VERSION ""

NS_ :

BS_:

BU_: CEM20 GW IDM Tester

BO_ 579 HUT_FD3: 64 GW
 SG_ LgtFolwDistanceSet : 378|3@0+ (1,0) [0|7] "NoUnit"  IDM
 SG_ IntellgntAsscLmpEnaReq : 369|2@0+ (1,0) [0|3] "NoUnit"  IDM
 SG_ UsrExperiProgAuthorSts : 371|2@0+ (1,0) [0|3] "NoUnit"  IDM
 SG_ SidePrkgReq : 373|2@0+ (1,0) [0|3] "NoUnit"  IDM
 SG_ NOAFuncSet : 375|2@0+ (1,0) [0|3] "NoUnit"  IDM
 SG_ OvertakingLightModReq : 361|2@0+ (1,0) [0|3] "NoUnit"  IDM
 SG_ IDsceneModReq : 365|4@0+ (1,0) [0|15] "NoUnit"  IDM
 SG_ PassETCEnaReq : 367|2@0+ (1,0) [0|3] "NoUnit"  IDM
 SG_ DeviateSpdPreReq : 357|6@0+ (1,-1) [-1|39] "Perc"  IDM
 SG_ StartReminderEnaReq : 359|2@0+ (1,0) [0|3] "NoUnit"  IDM
 SG_ DeviateSpdFixdValReq : 349|6@0+ (1,-1) [-1|39] "NoUnit"  IDM
 SG_ HandsoffModReq : 351|2@0+ (1,0) [0|3] "NoUnit"  IDM
 SG_ HWA_FaststSwtReq : 337|2@0+ (1,0) [0|3] "NoUnit"  IDM
 SG_ DeviateSpdModSwtReq : 339|2@0+ (1,0) [0|3] "NoUnit"  IDM
 SG_ MapStatus : 343|4@0+ (1,0) [0|15] ""  IDM
 SG_ ADAS_gpsAuthSys : 329|1@0+ (1,0) [0|1] ""  IDM
 SG_ PrivacySts : 330|1@0+ (1,0) [0|1] ""  IDM
 SG_ UNP_SwtReq : 331|1@0+ (1,0) [0|1] "NoUnit"  IDM
 SG_ NOH_Act_Req : 334|1@0+ (1,0) [0|1] ""  IDM
 SG_ NOH_Swt_Req : 335|1@0+ (1,0) [0|1] ""  IDM
 SG_ AVM_3DAngleReq : 239|9@0+ (1,0) [1|361] "NoUnit"  IDM
 SG_ PrkAreaSts : 225|2@0+ (1,0) [0|3] "NoUnit"  IDM
 SG_ BeginnerModSts : 191|2@0+ (1,0) [0|3] "NoUnit"  IDM
 SG_ OneClickAutDrvgSts : 125|1@0+ (1,0) [0|1] "NoUnit"  IDM
 SG_ HandsoffTimSet : 127|2@0+ (1,0) [0|3] "NoUnit"  IDM
 SG_ HUT_OD_WorkSts : 113|2@0+ (1,0) [0|3] "NoUnit"  IDM
 SG_ TraLightSwtReq : 62|1@0+ (1,0) [0|1] ""  IDM

BO_ 580 CSA3: 8 GW
 SG_ InrMalfct : 43|1@0+ (1,0) [0|1] ""  IDM

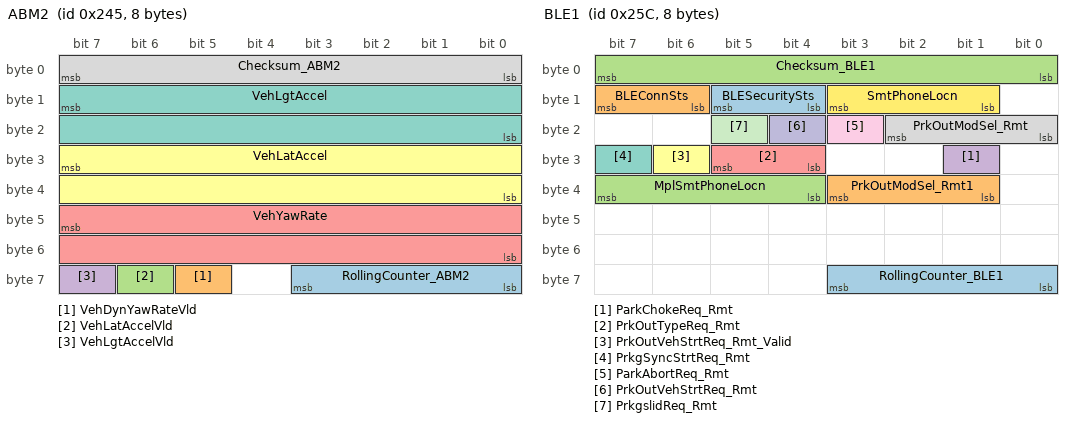
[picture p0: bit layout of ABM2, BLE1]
BO_ 581 ABM2: 8 GW
 SG_ RollingCounter_ABM2 : 59|4@0+ (1,0) [0|15] ""  IDM
 SG_ VehDynYawRateVld : 61|1@0+ (1,0) [0|1] ""  IDM
 SG_ VehLatAccelVld : 62|1@0+ (1,0) [0|1] ""  IDM
 SG_ VehLgtAccelVld : 63|1@0+ (1,0) [0|1] ""  IDM
 SG_ VehYawRate : 47|16@0+ (0.00024,-2.093) [-2.093|2.093] "rad/s"  IDM
 SG_ VehLatAccel : 31|16@0+ (0.00098,-21.592) [-21.592|21.592] "m/s^2"  IDM
 SG_ VehLgtAccel : 15|16@0+ (0.00098,-21.592) [-21.592|21.592] "m/s^2"  IDM
 SG_ Checksum_ABM2 : 7|8@0+ (1,0) [0|255] ""  IDM

BO_ 589 DMS_FD1: 64 GW
 SG_ DrvBehvSts : 370|3@0+ (1,0) [0|7] ""  IDM
 SG_ DMSSts : 303|3@0+ (1,0) [0|7] ""  IDM
 SG_ HeadDetn : 288|1@0+ (1,0) [0|1] ""  IDM
 SG_ DrowsnsLvl_ACC : 92|3@0+ (1,0) [0|7] ""  IDM
 SG_ DistrctnLvl_ACC : 95|3@0+ (1,0) [0|7] ""  IDM
 SG_ ExprsnSts : 34|3@0+ (1,0) [0|7] "NoUnit"  IDM
 SG_ DrvGazSts : 2|3@0+ (1,0) [0|7] ""  IDM

BO_ 596 CSA6: 8 GW
 SG_ LeSideDoRollSts : 19|4@0+ (1,0) [0|15] ""  IDM
 SG_ LeSideUpRollSts : 23|4@0+ (1,0) [0|15] ""  IDM

BO_ 604 BLE1: 8 GW
 SG_ RollingCounter_BLE1 : 59|4@0+ (1,0) [0|15] ""  IDM
 SG_ PrkOutModSel_Rmt1 : 35|3@0+ (1,0) [0|7] "NoUnit"  IDM
 SG_ MplSmtPhoneLocn : 39|4@0+ (1,0) [0|15] "NoUnit"  IDM
 SG_ ParkChokeReq_Rmt : 25|1@0+ (1,0) [0|1] "NoUnit"  IDM
 SG_ PrkOutTypeReq_Rmt : 29|2@0+ (1,0) [0|3] ""  IDM
 SG_ PrkOutVehStrtReq_Rmt_Valid : 30|1@0+ (1,0) [0|1] ""  IDM
 SG_ PrkgSyncStrtReq_Rmt : 31|1@0+ (1,0) [0|1] ""  IDM
 SG_ PrkOutModSel_Rmt : 18|3@0+ (1,0) [0|7] ""  IDM
 SG_ ParkAbortReq_Rmt : 19|1@0+ (1,0) [0|1] ""  IDM
 SG_ PrkOutVehStrtReq_Rmt : 20|1@0+ (1,0) [0|1] ""  IDM
 SG_ PrkgslidReq_Rmt : 21|1@0+ (1,0) [0|1] ""  IDM
 SG_ SmtPhoneLocn : 11|3@0+ (1,0) [0|7] "NoUnit"  IDM
 SG_ BLESecuritySts : 13|2@0+ (1,0) [0|3] ""  IDM
 SG_ BLEConnSts : 15|2@0+ (1,0) [0|3] ""  IDM
 SG_ Checksum_BLE1 : 7|8@0+ (1,0) [0|255] ""  IDM

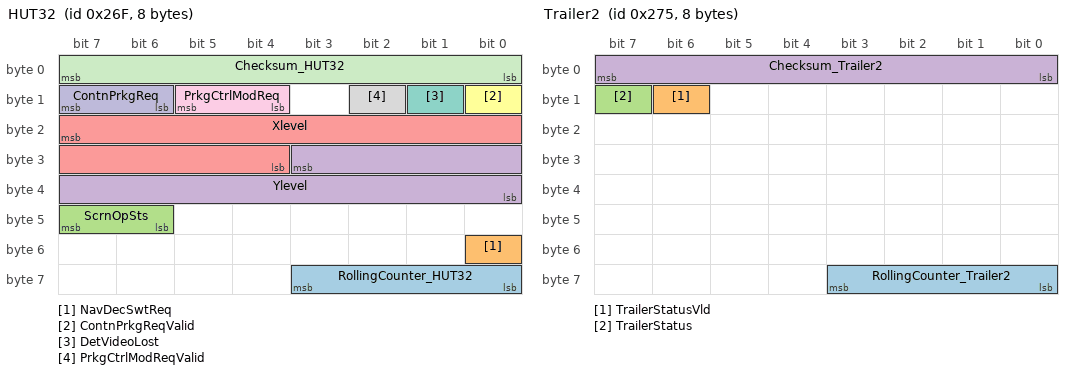
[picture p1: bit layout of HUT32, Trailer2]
BO_ 623 HUT32: 8 GW
 SG_ RollingCounter_HUT32 : 59|4@0+ (1,0) [0|14] ""  IDM
 SG_ NavDecSwtReq : 48|1@0+ (1,0) [0|1] "_"  IDM
 SG_ ScrnOpSts : 47|2@0+ (1,0) [0|3] ""  IDM
 SG_ Ylevel : 27|12@0+ (1,0) [0|4094] "NoUnit"  IDM
 SG_ Xlevel : 23|12@0+ (1,0) [0|4094] "NoUnit"  IDM
 SG_ ContnPrkgReqValid : 8|1@0+ (1,0) [0|1] ""  IDM
 SG_ DetVideoLost : 9|1@0+ (1,0) [0|1] ""  IDM
 SG_ PrkgCtrlModReqValid : 10|1@0+ (1,0) [0|1] ""  IDM
 SG_ PrkgCtrlModReq : 13|2@0+ (1,0) [0|3] ""  IDM
 SG_ ContnPrkgReq : 15|2@0+ (1,0) [0|3] ""  IDM
 SG_ Checksum_HUT32 : 7|8@0+ (1,0) [0|255] ""  IDM

BO_ 627 Trailer1: 8 GW
 SG_ TrailerSts : 7|1@0+ (1,0) [0|1] ""  IDM

BO_ 629 Trailer2: 8 GW
 SG_ RollingCounter_Trailer2 : 59|4@0+ (1,0) [0|14] "NoUnit"  IDM
 SG_ TrailerStatusVld : 14|1@0+ (1,0) [0|1] "NoUnit"  IDM
 SG_ TrailerStatus : 15|1@0+ (1,0) [0|1] "NoUnit"  IDM
 SG_ Checksum_Trailer2 : 7|8@0+ (1,0) [0|255] "NoUnit"  IDM

BO_ 639 IP2: 16 GW
 SG_ IP_Err : 52|1@0+ (1,0) [0|1] ""  IDM
 SG_ IP_VehSpdUnit : 53|1@0+ (1,0) [0|1] ""  IDM
 SG_ IP_VehTotDistanceValid : 46|1@0+ (1,0) [0|1] ""  IDM
 SG_ IP_ACCErr : 47|1@0+ (1,0) [0|1] ""  IDM
 SG_ IP_VehTotDistance : 15|24@0+ (0.1,0) [0|999999.9] "Km"  IDM

BO_ 659 IP1: 8 GW
 SG_ IP_VelSpdDisp_Mile : 51|8@0+ (1,0) [0|254] "mph"  IDM
 SG_ IP_VehSpdDisp : 15|9@0+ (0.5,0) [0|255] "km/h"  IDM

BO_ 670 BMS_FD2: 64 GW
 SG_ BMS_CC2LineSts : 211|2@0+ (1,0) [0|3] "NoUnit"  IDM

BO_ 707 HUT_FD1: 64 GW
 SG_ MAC_Check_HUT_FD1 : 471|48@0+ (1,0) [0|281474976710655] ""  IDM
 SG_ FreshnessValue_HUT_FD1 : 455|16@0+ (1,0) [0|65535] ""  IDM
 SG_ ADAS_Posn_Rehead : 383|8@0+ (1.41732283464567,0) [2.83464566929134|357.165354330709] "NoUnit"  IDM
 SG_ ADAS_Posn_Spd : 360|9@0+ (0.2,-12.8) [-12.6|89] "mps"  IDM
 SG_ ADAS_Posn_CurLane : 363|3@0+ (1,0) [0|7] ""  IDM
 SG_ ADAS_Posn_PosConfdc : 366|3@0+ (1,0) [0|6] "NoUnit"  IDM
 SG_ ADAS_Posn_Age : 344|9@0+ (5,0) [0|2545] "ms"  IDM
 SG_ ADAS_Posn_PosProbb : 349|5@0+ (3.33,0) [3.33|99.9] "NoUnit"  IDM
 SG_ ADAS_Posn_Idx : 351|2@0+ (1,0) [0|3] "m"  IDM
 SG_ ADAS_Posn_Pathldx : 341|6@0+ (1,0) [0|63] ""  IDM
 SG_ ADAS_Posn_CycCnt : 343|2@0+ (1,0) [0|3] ""  IDM
 SG_ ADAS_Posn_Offset : 324|13@0+ (1,0) [0|8190] "m"  IDM
 SG_ ADAS_Posn_MsgTye : 327|3@0+ (1,0) [0|7] ""  IDM
 SG_ NavSpdLimType : 307|2@0+ (1,0) [0|3] ""  IDM
 SG_ NavigationRoadType : 311|4@0+ (1,0) [0|15] ""  IDM
 SG_ ALC_SwtReq : 296|1@0+ (1,0) [0|1] ""  IDM
 SG_ AESSwtReq : 298|1@0+ (1,0) [0|1] ""  IDM
 SG_ AEB_JASwtReq : 299|1@0+ (1,0) [0|1] ""  IDM
 SG_ FCTABrkSwtReq : 300|1@0+ (1,0) [0|1] ""  IDM
 SG_ FCTASwtReq : 301|1@0+ (1,0) [0|1] ""  IDM
 SG_ HWA_SnvtySet : 303|2@0+ (1,0) [0|3] ""  IDM
 SG_ NavTSRTrafSign : 295|8@0+ (1,0) [0|255] ""  IDM
 SG_ HWA_SwtReq : 280|1@0+ (1,0) [0|1] ""  IDM
 SG_ NavSpdLimSignSts : 285|3@0+ (1,0) [0|7] ""  IDM
 SG_ NavCtryType : 279|10@0+ (1,0) [0|1023] ""  IDM
 SG_ NavSpdLimUnit_HUT : 265|2@0+ (1,0) [0|3] ""  IDM
 SG_ NavSpdLimValue : 271|6@0+ (1,0) [0|63] ""  IDM
 SG_ NavVehToTrafEyeDist : 239|10@0+ (1,0) [0|1023] ""  IDM
 SG_ MOD_SwtReq : 207|2@0+ (1,0) [0|3] "NoUnit"  IDM
 SG_ TSR_SnvtySet : 125|5@0+ (1,-15) [-15|15] "km/h"  IDM
 SG_ ISLSwtReq : 126|1@0+ (1,0) [0|1] ""  IDM
 SG_ DOWSwtReq : 104|1@0+ (1,0) [0|1] ""  IDM
 SG_ AEB_PedSwtReq : 105|1@0+ (1,0) [0|1] ""  IDM
 SG_ LSSSwtReq : 106|1@0+ (1,0) [0|1] ""  IDM
 SG_ IntelligentEvaSwtReq : 107|1@0+ (1,0) [0|1] ""  IDM
 SG_ LSSWarnFormSwtReq : 100|2@0+ (1,0) [0|3] ""  IDM
 SG_ TSRWarnSwtReq : 101|1@0+ (1,0) [0|1] ""  IDM
 SG_ TSRSwtReq : 102|1@0+ (1,0) [0|1] ""  IDM
 SG_ LDWSwtReq : 88|1@0+ (1,0) [0|1] ""  IDM
 SG_ ESS_VehSwtReq : 89|1@0+ (1,0) [0|1] ""  IDM
 SG_ ESS_PedSwtReq : 90|1@0+ (1,0) [0|1] ""  IDM
 SG_ ELKSwtReq : 91|1@0+ (1,0) [0|1] ""  IDM
 SG_ LCKSwtReq : 92|1@0+ (1,0) [0|1] ""  IDM
 SG_ LKASwtReq : 93|1@0+ (1,0) [0|1] ""  IDM
 SG_ AEB_VehSwtReq : 95|1@0+ (1,0) [0|1] ""  IDM
 SG_ FCW_SnvtySet : 81|2@0+ (1,0) [0|3] ""  IDM
 SG_ RCWSwtReq : 82|1@0+ (1,0) [0|1] ""  IDM
 SG_ RCTABrkSwtReq : 83|1@0+ (1,0) [0|1] ""  IDM
 SG_ RCTASwtReq : 84|1@0+ (1,0) [0|1] ""  IDM
 SG_ LCASwtReq : 85|1@0+ (1,0) [0|1] ""  IDM
 SG_ IFC_SnvtySet : 77|2@0+ (1,0) [0|3] ""  IDM
 SG_ NOH_Btn_Sts : 65|1@0+ (1,0) [0|1] ""  IDM
 SG_ DR_CalibratedSts : 69|1@0+ (1,0) [0|1] ""  IDM
 SG_ IntellgntcurveReq : 9|1@0+ (1,0) [0|1] ""  IDM

BO_ 717 PDCM1: 8 GW
 SG_ PassWinPosnSts_Perc : 39|5@0+ (1,0) [0|31] ""  IDM
 SG_ RSDS_Pass_LED_Sts : 8|1@0+ (1,0) [0|1] ""  IDM

BO_ 725 PRDCM1: 8 GW
 SG_ PassRearDoorWinPosnSts_Perc : 15|5@0+ (1,0) [0|31] "NoUnit"  IDM

BO_ 726 VCU_FD4: 64 GW
 SG_ WtrAirCoolrPmp_FltSts : 272|1@0+ (1,0) [0|1] "NoUnit"  IDM
 SG_ RollingCounter_VCU13 : 251|4@0+ (1,0) [0|15] "NoUnit"  IDM
 SG_ VCU_LTRadrOutlWtrTemp : 223|8@0+ (1,-40) [-40|130] "DegCgrd"  IDM
 SG_ VCU_WtrPmpOpenRateCtrl : 215|7@0+ (1,0) [0|100] "Perc"  IDM
 SG_ Checksum_VCU13 : 199|8@0+ (1,0) [0|255] "NoUnit"  IDM
 SG_ VCU_VCUSts : 181|5@0+ (1,0) [0|31] "NoUnit"  IDM
 SG_ VCU_ResrDrvRng : 175|10@0+ (1,0) [0|999] "Km"  IDM
 SG_ RollingCounter_VCU3 : 123|4@0+ (1,0) [0|15] "NoUnit"  IDM
 SG_ ChrgnSts : 127|4@0+ (1,0) [0|15] ""  IDM
 SG_ VCU_SysFltLmp : 114|2@0+ (1,0) [0|3] ""  IDM
 SG_ EnrgFlowInd : 111|6@0+ (1,0) [0|63] ""  IDM
 SG_ VCU_TMWtrPmpSts : 98|1@0+ (1,0) [0|1] "NoUnit"  IDM
 SG_ VCU_PwrLo : 99|1@0+ (1,0) [0|1] ""  IDM
 SG_ VCU_EPSEnable : 101|1@0+ (1,0) [0|1] ""  IDM
 SG_ VCU_RdyLEDSts : 103|2@0+ (1,0) [0|3] "No Unit"  IDM
 SG_ VCU_VehBrkLiActv : 80|1@0+ (1,0) [0|1] ""  IDM
 SG_ VCU_OPDSts : 87|3@0+ (1,0) [0|7] ""  IDM
 SG_ VCU_HeatgAimT : 79|8@0+ (1,0) [0|165] ""  IDM
 SG_ Checksum_VCU3 : 71|8@0+ (1,0) [0|255] "NoUnit"  IDM

BO_ 728 HUT23: 8 GW
 SG_ ADAS_Stub_NumOfLaneDrvDir : 58|3@0+ (1,0) [0|7] ""  IDM
 SG_ ADAS_Stub_NumOfLaneOppDir : 60|2@0+ (1,0) [0|3] ""  IDM
 SG_ ADAS_Stub_RtOfWay : 62|2@0+ (1,0) [0|3] ""  IDM
 SG_ ADAS_Stub_LastStub : 63|1@0+ (1,0) [0|1] ""  IDM
 SG_ ADAS_Stub_TurnAngl : 55|8@0+ (1.417,0) [2.834|357.084] "NoUnit"  IDM
 SG_ ADAS_Stub_FormOfWay : 43|4@0+ (1,0) [0|15] ""  IDM
 SG_ ADAS_Stub_CmplxInsct : 45|2@0+ (1,0) [0|3] ""  IDM
 SG_ ADAS_Stub_PartOfCalcRoute : 47|2@0+ (1,0) [0|3] ""  IDM
 SG_ ADAS_Stub_FuncRoadClass : 34|3@0+ (1,0) [0|7] ""  IDM
 SG_ ADAS_Stub_RelProbb : 39|5@0+ (3.33333,0) [3.33333|99.9999] "NoUnit"  IDM
 SG_ ADAS_Stub_Update : 24|1@0+ (1,0) [0|1] ""  IDM
 SG_ ADAS_Stub_Retr : 25|1@0+ (1,0) [0|1] ""  IDM
 SG_ ADAS_Stub_StubPathIdx : 31|6@0+ (1,0) [0|63] ""  IDM
 SG_ ADAS_Stub_PathIdx : 21|6@0+ (1,0) [0|63] ""  IDM
 SG_ ADAS_Stub_CycCnt : 23|2@0+ (1,0) [0|3] "NoUnit"  IDM
 SG_ ADAS_Stub_Offset : 4|13@0+ (1,0) [0|8190] "m"  IDM
 SG_ ADAS_Stub_MsgTyp : 7|3@0+ (1,0) [0|7] ""  IDM

BO_ 730 HUT22: 8 GW
 SG_ ADAS_Seg_NumOfLaneDrvDir : 58|3@0+ (1,0) [0|7] "NoUnit"  IDM
 SG_ ADAS_Seg_NumOfLaneOppDir : 60|2@0+ (1,0) [0|3] ""  IDM
 SG_ ADAS_Seg_DivideRoad : 62|2@0+ (1,0) [0|3] ""  IDM
 SG_ ADAS_Seg_EffSpdLmtTyp : 50|3@0+ (1,0) [0|7] ""  IDM
 SG_ ADAS_Seg_EffSpdLmt : 55|5@0+ (1,0) [0|31] "NoUnit"  IDM
 SG_ ADAS_Seg_FormOfWay : 43|4@0+ (1,0) [0|15] ""  IDM
 SG_ ADAS_Seg_CmplxInsct : 45|2@0+ (1,0) [0|3] ""  IDM
 SG_ ADAS_Seg_PartOfCalcRoute : 47|2@0+ (1,0) [0|3] ""  IDM
 SG_ ADAS_Seg_FuncRoadClass : 34|3@0+ (1,0) [0|7] ""  IDM
 SG_ ADAS_Seg_RelProbb : 39|5@0+ (3.33333333333333,0) [3.33333333333333|99.9999999999999] "NoUnit"  IDM
 SG_ ADAS_Seg_Update : 24|1@0+ (1,0) [0|1] ""  IDM
 SG_ ADAS_Seg_Retr : 25|1@0+ (1,0) [0|1] ""  IDM
 SG_ ADAS_Seg_BuildUpArea : 27|2@0+ (1,0) [0|3] ""  IDM
 SG_ ADAS_Seg_Brdg : 29|2@0+ (1,0) [0|3] ""  IDM
 SG_ ADAS_Seg_Tunnel : 31|2@0+ (1,0) [0|3] ""  IDM
 SG_ ADAS_Seg_PathIdx : 21|6@0+ (1,0) [0|63] "NoUnit"  IDM
 SG_ ADAS_Seg_CycCnt : 23|2@0+ (1,0) [0|3] "NoUnit"  IDM
 SG_ ADAS_Seg_Offset : 4|13@0+ (1,0) [0|8190] "m"  IDM
 SG_ ADAS_Seg_MsgTyp : 7|3@0+ (1,0) [0|7] ""  IDM

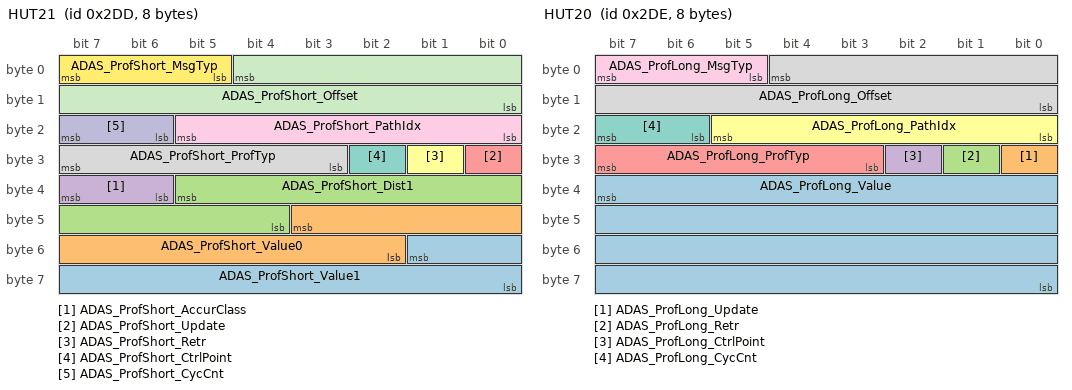
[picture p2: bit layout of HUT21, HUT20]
BO_ 733 HUT21: 8 GW
 SG_ ADAS_ProfShort_Value1 : 49|10@0+ (1,0) [0|1022] ""  IDM
 SG_ ADAS_ProfShort_Value0 : 43|10@0+ (1,0) [0|1022] ""  IDM
 SG_ ADAS_ProfShort_Dist1 : 37|10@0+ (1,0) [1|1022] "m"  IDM
 SG_ ADAS_ProfShort_AccurClass : 39|2@0+ (1,0) [0|3] ""  IDM
 SG_ ADAS_ProfShort_Update : 24|1@0+ (1,0) [0|1] ""  IDM
 SG_ ADAS_ProfShort_Retr : 25|1@0+ (1,0) [0|1] ""  IDM
 SG_ ADAS_ProfShort_CtrlPoint : 26|1@0+ (1,0) [0|1] ""  IDM
 SG_ ADAS_ProfShort_ProfTyp : 31|5@0+ (1,0) [0|31] ""  IDM
 SG_ ADAS_ProfShort_PathIdx : 21|6@0+ (1,0) [0|63] ""  IDM
 SG_ ADAS_ProfShort_CycCnt : 23|2@0+ (1,0) [0|3] ""  IDM
 SG_ ADAS_ProfShort_Offset : 4|13@0+ (1,0) [0|8190] "m"  IDM
 SG_ ADAS_ProfShort_MsgTyp : 7|3@0+ (1,0) [0|7] ""  IDM

BO_ 734 HUT20: 8 GW
 SG_ ADAS_ProfLong_Value : 39|32@0+ (1,0) [0|4294967295] ""  IDM
 SG_ ADAS_ProfLong_Update : 24|1@0+ (1,0) [0|1] ""  IDM
 SG_ ADAS_ProfLong_Retr : 25|1@0+ (1,0) [0|1] ""  IDM
 SG_ ADAS_ProfLong_CtrlPoint : 26|1@0+ (1,0) [0|1] ""  IDM
 SG_ ADAS_ProfLong_ProfTyp : 31|5@0+ (1,0) [0|31] ""  IDM
 SG_ ADAS_ProfLong_PathIdx : 21|6@0+ (1,0) [0|63] ""  IDM
 SG_ ADAS_ProfLong_CycCnt : 23|2@0+ (1,0) [0|3] ""  IDM
 SG_ ADAS_ProfLong_Offset : 4|13@0+ (1,0) [0|8190] "m"  IDM
 SG_ ADAS_ProfLong_MsgTyp : 7|3@0+ (1,0) [0|7] ""  IDM

BO_ 769 ECM_FD3: 64 GW
 SG_ ECM_WCACPmpFailrSts : 294|1@0+ (1,0) [0|1] "NoUnit"  IDM
 SG_ CoolerSts : 167|7@0+ (1,0) [0|100] "Perc"  IDM
 SG_ EngLimpHomeSts : 115|1@0+ (1,0) [0|1] "NoUnit"  IDM

BO_ 795 VCU5: 8 GW
 SG_ VCU_SysFltLvl : 62|3@0+ (1,0) [0|7] "No Unit"  IDM

BO_ 796 HUT13: 8 GW
 SG_ HUT_EPB_SwtPosn : 51|2@0+ (1,0) [0|3] "NoUnit"  IDM

BO_ 799 OBC_FD2: 8 GW
 SG_ OBC_CCLineSts : 48|2@0+ (1,0) [0|3] "NoUnit"  IDM

BO_ 822 HUT_FD10: 32 GW
 SG_ DrvImpairmAsstReq : 185|2@0+ (1,0) [0|3] "NoUnit"  IDM

BO_ 827 HUT17: 8 GW
 SG_ LowPowerEgyMngmntModReq : 57|2@0+ (1,0) [0|3] ""  IDM

BO_ 829 T_BOX_FD6: 16 GW
 SG_ T_BOX_AVPActvReq : 3|2@0+ (1,0) [0|3] ""  IDM

BO_ 840 HUT16: 8 GW
 SG_ IntellgntDrvChildModDetn : 59|2@0+ (1,0) [0|3] "NoUnit"  IDM
 SG_ SentinelMode_HUT : 35|2@0+ (1,0) [0|3] "Nounit"  IDM

BO_ 849 ABM1: 16 GW
 SG_ RollingCounter_ABM1 : 59|4@0+ (1,0) [0|15] ""  IDM
 SG_ CrashSev_1 : 60|1@0+ (1,0) [0|1] "NoUnit"  IDM
 SG_ CrashSev_2 : 61|1@0+ (1,0) [0|1] "NoUnit"  IDM
 SG_ CrashSev_3 : 62|1@0+ (1,0) [0|1] ""  IDM
 SG_ CrashSev_4 : 63|1@0+ (1,0) [0|1] ""  IDM
 SG_ ThrdRowLSperSts : 50|1@0+ (1,0) [0|1] ""  IDM
 SG_ ThrdRowRSperSts : 51|1@0+ (1,0) [0|1] ""  IDM
 SG_ CrashSev_5 : 40|1@0+ (1,0) [0|1] ""  IDM
 SG_ AmntOfPass : 43|3@0+ (1,0) [0|7] ""  IDM
 SG_ SecRowMidSperSts : 44|1@0+ (1,0) [0|1] ""  IDM
 SG_ SecRowRSperSts : 45|1@0+ (1,0) [0|1] ""  IDM
 SG_ SecRowLSperSts : 46|1@0+ (1,0) [0|1] ""  IDM
 SG_ PassSperSts : 47|1@0+ (1,0) [0|1] ""  IDM
 SG_ SecRowRSBR_Visual : 33|2@0+ (1,0) [0|3] ""  IDM
 SG_ ThrdRowLSBR_Visual : 35|2@0+ (1,0) [0|3] ""  IDM
 SG_ ThrdRowRSBR_Visual : 37|2@0+ (1,0) [0|3] ""  IDM
 SG_ ThrdRowLSBR : 38|1@0+ (1,0) [0|1] ""  IDM
 SG_ ThrdRowRSBR : 39|1@0+ (1,0) [0|1] ""  IDM
 SG_ DrvSBR_Visual : 25|2@0+ (1,0) [0|3] ""  IDM
 SG_ PassSBR_Visual : 27|2@0+ (1,0) [0|3] ""  IDM
 SG_ SecRowLSBR_Visual : 29|2@0+ (1,0) [0|3] ""  IDM
 SG_ SecRowMidSBR_Visual : 31|2@0+ (1,0) [0|3] ""  IDM
 SG_ CrashOutputSts : 23|8@0+ (1,0) [0|18] ""  IDM
 SG_ RSCAOFFSts : 8|1@0+ (1,0) [0|1] ""  IDM
 SG_ PassSBLockSts : 9|1@0+ (1,0) [0|1] ""  IDM
 SG_ SecRowRSBLockSts : 10|1@0+ (1,0) [0|1] ""  IDM
 SG_ DrvSBR : 11|1@0+ (1,0) [0|1] ""  IDM
 SG_ SecRowMidSBLockSts : 12|1@0+ (1,0) [0|1] ""  IDM
 SG_ AirbFailLmpCmd : 13|1@0+ (1,0) [0|1] ""  IDM
 SG_ SecRowLSBLockSts : 14|1@0+ (1,0) [0|1] ""  IDM
 SG_ PABSwtSts : 15|1@0+ (1,0) [0|1] ""  IDM
 SG_ Checksum_ABM1 : 7|8@0+ (1,0) [0|255] ""  IDM

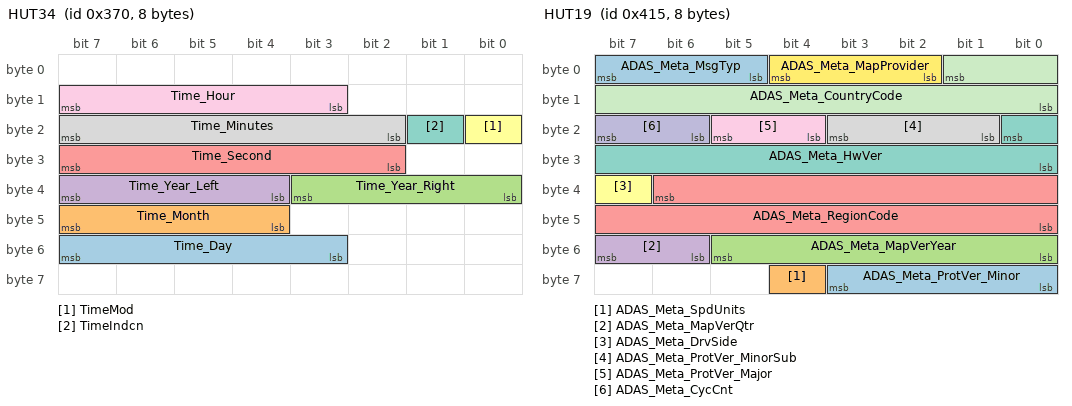
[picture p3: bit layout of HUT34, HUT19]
BO_ 880 HUT34: 8 GW
 SG_ Time_Day : 55|5@0+ (1,0) [1|31] "NoUnit"  IDM
 SG_ Time_Month : 47|4@0+ (1,0) [0|15] ""  IDM
 SG_ Time_Year_Right : 35|4@0+ (1,0) [0|15] ""  IDM
 SG_ Time_Year_Left : 39|4@0+ (1,0) [0|15] ""  IDM
 SG_ Time_Second : 31|6@0+ (1,0) [0|59] "NoUnit"  IDM
 SG_ TimeMod : 16|1@0+ (1,0) [0|1] ""  IDM
 SG_ TimeIndcn : 17|1@0+ (1,0) [0|1] ""  IDM
 SG_ Time_Minutes : 23|6@0+ (1,0) [0|59] "NoUnit"  IDM
 SG_ Time_Hour : 15|5@0+ (1,0) [0|23] "NoUnit"  IDM

BO_ 907 PTCC1: 24 GW
 SG_ RollingCounter_PTCC1_1 : 59|4@0+ (1,0) [0|14] "NoUnit"  IDM
 SG_ BSCSts : 15|3@0+ (1,0) [0|7] "NoUnit"  IDM
 SG_ Checksum_PTCC1_1 : 7|8@0+ (1,0) [0|255] "NoUnit"  IDM

BO_ 1001 T_BOX_FD3: 16 GW
 SG_ MAC_Check_T_BOX_FD3 : 87|48@0+ (1,0) [0|281474976710655] ""  IDM
 SG_ FreshnessValue_T_BOX_FD3 : 71|16@0+ (1,0) [0|65535] ""  IDM
 SG_ T_BOX_SysErrSts : 7|5@0+ (1,0) [0|31] ""  IDM

BO_ 1045 HUT19: 8 GW
 SG_ ADAS_Meta_ProtVer_Minor : 59|4@0+ (1,0) [0|15] ""  IDM
 SG_ ADAS_Meta_SpdUnits : 60|1@0+ (1,0) [0|1] ""  IDM
 SG_ ADAS_Meta_MapVerYear : 53|6@0+ (1,0) [0|62] "NoUnit"  IDM
 SG_ ADAS_Meta_MapVerQtr : 55|2@0+ (1,0) [0|3] ""  IDM
 SG_ ADAS_Meta_RegionCode : 38|15@0+ (1,0) [1|32766] "NoUnit"  IDM
 SG_ ADAS_Meta_DrvSide : 39|1@0+ (1,0) [0|1] ""  IDM
 SG_ ADAS_Meta_HwVer : 16|9@0+ (1,0) [1|511] "NoUnit"  IDM
 SG_ ADAS_Meta_ProtVer_MinorSub : 19|3@0+ (1,0) [0|7] ""  IDM
 SG_ ADAS_Meta_ProtVer_Major : 21|2@0+ (1,0) [0|3] ""  IDM
 SG_ ADAS_Meta_CycCnt : 23|2@0+ (1,0) [0|3] ""  IDM
 SG_ ADAS_Meta_CountryCode : 1|10@0+ (1,0) [1|1023] "NoUnit"  IDM
 SG_ ADAS_Meta_MapProvider : 4|3@0+ (1,0) [0|7] ""  IDM
 SG_ ADAS_Meta_MsgTyp : 7|3@0+ (1,0) [0|7] ""  IDM

BO_ 68 HUT7: 8 GW
 SG_ CarWashModeReq : 50|2@0+ (1,0) [0|3] "NoUnit"  IDM

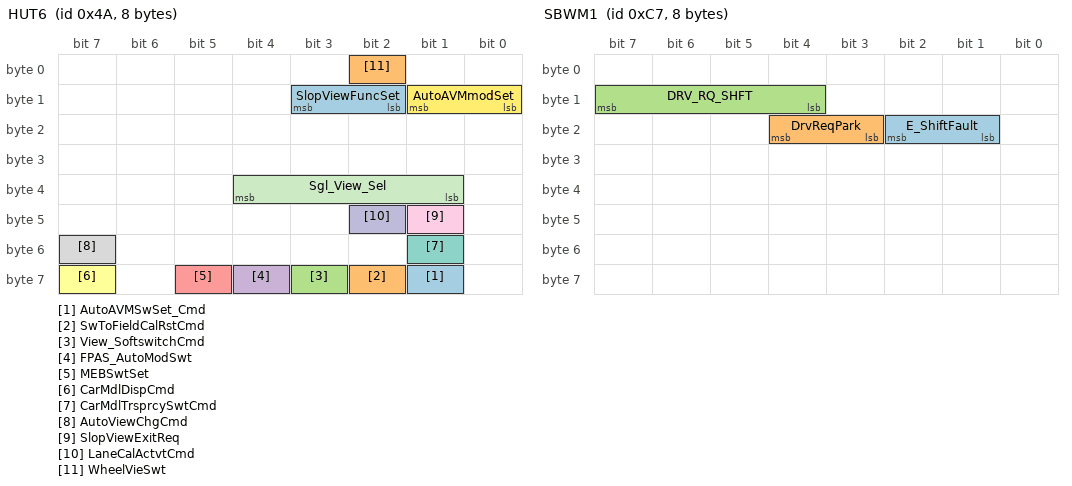
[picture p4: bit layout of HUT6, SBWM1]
BO_ 74 HUT6: 8 GW
 SG_ AutoAVMSwSet_Cmd : 57|1@0+ (1,0) [0|1] ""  IDM
 SG_ SwToFieldCalRstCmd : 58|1@0+ (1,0) [0|1] ""  IDM
 SG_ View_SoftswitchCmd : 59|1@0+ (1,0) [0|1] ""  IDM
 SG_ FPAS_AutoModSwt : 60|1@0+ (1,0) [0|1] ""  IDM
 SG_ MEBSwtSet : 61|1@0+ (1,0) [0|1] ""  IDM
 SG_ CarMdlDispCmd : 63|1@0+ (1,0) [0|1] ""  IDM
 SG_ CarMdlTrsprcySwtCmd : 49|1@0+ (1,0) [0|1] ""  IDM
 SG_ AutoViewChgCmd : 55|1@0+ (1,0) [0|1] ""  IDM
 SG_ SlopViewExitReq : 41|1@0+ (1,0) [0|1] "NoUnit"  IDM
 SG_ LaneCalActvtCmd : 42|1@0+ (1,0) [0|1] ""  IDM
 SG_ Sgl_View_Sel : 36|4@0+ (1,0) [0|15] ""  IDM
 SG_ AutoAVMmodSet : 9|2@0+ (1,0) [0|3] "NoUnit"  IDM
 SG_ SlopViewFuncSet : 11|2@0+ (1,0) [0|3] "NoUnit"  IDM
 SG_ WheelVieSwt : 2|1@0+ (1,0) [0|1] "NoUnit"  IDM

BO_ 96 HCU_FD1: 64 GW
 SG_ RollingCounter_HCU_PT14 : 443|4@0+ (1,0) [0|14] ""  IDM
 SG_ EGRreq : 434|2@0+ (1,0) [0|3] ""  IDM
 SG_ HCU_TgtGearReq_TCU : 407|4@0+ (1,0) [0|15] ""  IDM
 SG_ EmgyEngageReq_TCU : 393|1@0+ (1,0) [0|1] ""  IDM
 SG_ EmgyShiftNReq_TCU : 394|1@0+ (1,0) [0|1] ""  IDM
 SG_ ShiftAllwdCmd_TCU : 395|1@0+ (1,0) [0|1] ""  IDM
 SG_ HCU_bAcvTqCtrl : 396|1@0+ (1,0) [0|1] ""  IDM
 SG_ HCU_bAcvSyncReq : 397|1@0+ (1,0) [0|1] ""  IDM
 SG_ HCU_TCUPTAllwdCmd : 398|1@0+ (1,0) [0|1] ""  IDM
 SG_ HCU_TCUKPAllwdCmd : 399|1@0+ (1,0) [0|1] ""  IDM
 SG_ Checksum_HCU_PT14 : 391|8@0+ (1,0) [0|255] ""  IDM
 SG_ RollingCounter_HCU_HP11 : 379|4@0+ (1,0) [0|14] ""  IDM
 SG_ HCU_TCUEmgyEngageReq : 383|1@0+ (1,0) [0|1] ""  IDM
 SG_ HCU_AccPedalPosnCorrdValid : 368|1@0+ (1,0) [0|1] ""  IDM
 SG_ TargetGear_RA : 370|2@0+ (1,0) [0|3] ""  IDM
 SG_ HCU_TCUEmgyShiftNReq : 360|1@0+ (1,0) [0|1] ""  IDM
 SG_ HCU_StLimphm : 361|1@0+ (1,0) [0|1] ""  IDM
 SG_ HCU_TrqReq_TrsmClutchValid : 362|1@0+ (1,0) [0|1] ""  IDM
 SG_ HCU_AccPedalPosnCorrd : 351|8@0+ (0.3937,0) [0|100.3935] "Perc"  IDM
 SG_ Checksum_HCU_HP11 : 327|8@0+ (1,0) [0|255] ""  IDM
 SG_ RollingCounter_HCU_HP10 : 315|4@0+ (1,0) [0|15] "NoUnit"  IDM
 SG_ TrqReq_FAValid : 316|1@0+ (1,0) [0|1] ""  IDM
 SG_ HCU_EPBReleaseReq : 317|1@0+ (1,0) [0|1] ""  IDM
 SG_ TrqReq_FA : 298|11@0+ (1,-400) [-400|799] "Nm"  IDM
 SG_ HCU_PowertrainSts : 303|5@0+ (1,0) [0|31] "NoUnit"  IDM
 SG_ HCU_ActvSysOperMode : 292|3@0+ (1,0) [0|7] ""  IDM
 SG_ HCU_TgtSysOperMode : 295|3@0+ (1,0) [0|7] ""  IDM
 SG_ HCU_EPBReleaseReqValid : 280|1@0+ (1,0) [0|1] ""  IDM
 SG_ HCU_ChrgDeplt : 281|1@0+ (1,0) [0|1] ""  IDM
 SG_ HCU_DCTCreepInhbn : 282|1@0+ (1,0) [0|1] ""  IDM
 SG_ HCU_KickDownActv : 283|1@0+ (1,0) [0|1] ""  IDM
 SG_ TrqReqFastPathEnable : 284|1@0+ (1,0) [0|1] ""  IDM
 SG_ TrqReqSlowPathEnable : 285|1@0+ (1,0) [0|1] ""  IDM
 SG_ HCU_EngBrkActv_Flg : 286|1@0+ (1,0) [0|1] ""  IDM
 SG_ HCU_TCUSleepReq : 287|1@0+ (1,0) [0|1] ""  IDM
 SG_ HCU_TgtSyPosnReq : 273|2@0+ (1,0) [0|3] ""  IDM
 SG_ HCU_EVTgtGearSts : 275|2@0+ (1,0) [0|3] ""  IDM
 SG_ TrqLowLimit : 271|10@0+ (1,-224) [-224|798] "Nm"  IDM
 SG_ Checksum_HCU_HP10 : 263|8@0+ (1,0) [0|255] "NoUnit"  IDM
 SG_ RollingCounter_HCU_HP1 : 251|4@0+ (1,0) [0|14] ""  IDM
 SG_ HCU_TgtEngTrqValid : 252|1@0+ (1,0) [0|1] ""  IDM
 SG_ HCU_TrqReqWoDCT_TrsmClutchValid : 253|1@0+ (1,0) [0|1] ""  IDM
 SG_ HCU_MaxEngTrqLimtValid : 254|1@0+ (1,0) [0|1] ""  IDM
 SG_ HCU_NetTrq_TrsmClutchValid : 255|1@0+ (1,0) [0|1] ""  IDM
 SG_ HCU_K0ClutchAdaptAck : 240|1@0+ (1,0) [0|1] ""  IDM
 SG_ HCU_TrsmClutchAdaptAck : 241|1@0+ (1,0) [0|1] ""  IDM
 SG_ HCU_MaxTrqLimt_TrsmClutch : 235|10@0+ (0.2,-100) [-100|100] "Perc"  IDM
 SG_ HCU_TrqReqWoDCT_TrsmClutch : 231|12@0+ (0.05,-100) [-100|100] "Perc"  IDM
 SG_ HCU_TrqReq_TrsmClutch : 211|12@0+ (0.05,-100) [-100|100] "Perc"  IDM
 SG_ HCU_NetTrq_TrsmClutch : 207|12@0+ (0.05,-100) [-100|100] "Perc"  IDM
 SG_ Checksum_HCU_HP1 : 199|8@0+ (1,0) [0|255] ""  IDM
 SG_ RollingCounter_HCU_HP8 : 187|4@0+ (1,0) [0|14] ""  IDM
 SG_ HCU_StCluReq : 169|2@0+ (1,0) [0|3] ""  IDM
 SG_ TorqueLossValid : 171|1@0+ (1,0) [0|1] ""  IDM
 SG_ HCU_TrqLimMax_Norm : 144|9@0+ (2,0) [0|880] "Nm"  IDM
 SG_ TorqueLoss : 143|12@0+ (0.0488281,-100) [-100|99.9510695] "Perc"  IDM
 SG_ Checksum_HCU_HP8 : 135|8@0+ (1,0) [0|255] ""  IDM
 SG_ RollingCounter_HCU_PT1 : 123|4@0+ (1,0) [0|15] ""  IDM
 SG_ HCU_StartStopTypReq : 127|4@0+ (1,0) [0|15] ""  IDM
 SG_ ActWheelTrqDmd : 83|12@0+ (5,-6000) [-6000|14475] "Nm"  IDM
 SG_ VCU_RoadTyp : 87|4@0+ (1,0) [0|15] ""  IDM
 SG_ Checksum_HCU_PT1 : 71|8@0+ (1,0) [0|255] ""  IDM
 SG_ RollingCounter_HCU_PT11 : 59|4@0+ (1,0) [0|14] ""  IDM
 SG_ HCU_TrqCrksftReq : 55|12@0+ (0.25,-224) [-224|799.75] "Nm"  IDM
 SG_ HCU_ActTqCrksft : 35|12@0+ (0.25,-224) [-224|799.75] "Nm"  IDM
 SG_ HCU_ActTqCrksftValid : 39|1@0+ (1,0) [0|1] ""  IDM
 SG_ HCU_RefAllwdCmd_TCU : 24|1@0+ (1,0) [0|1] ""  IDM
 SG_ HCU_ECMPumpReq : 31|7@0+ (1,0) [0|100] "Perc"  IDM
 SG_ Idle_C_AWDActv : 16|1@0+ (1,0) [0|1] ""  IDM
 SG_ Idle_H_AWDActv : 17|1@0+ (1,0) [0|1] ""  IDM
 SG_ Idle_E_AWDActv : 18|1@0+ (1,0) [0|1] ""  IDM
 SG_ Checksum_HCU_PT11 : 7|8@0+ (1,0) [0|255] ""  IDM

BO_ 121 ECM_FD1: 64 GW
 SG_ RollingCounter_ECM1 : 315|4@0+ (1,0) [0|15] "NoUnit"  IDM
 SG_ EngSpdVldty : 319|2@0+ (1,0) [0|3] "NoUnit"  IDM
 SG_ EngSpd : 303|16@0+ (0.125,0) [0|8191.875] "rpm"  IDM
 SG_ Start_StopSts : 295|3@0+ (1,0) [0|7] "NoUnit"  IDM
 SG_ BrkPedalSts : 275|2@0+ (1,0) [0|3] "NoUnit"  IDM
 SG_ Checksum_ECM1 : 263|8@0+ (1,0) [0|255] "NoUnit"  IDM

BO_ 124 DCT_FD1: 64 GW
 SG_ TCU_TrqRatio : 431|16@0+ (0.001,0) [0|65.533] ""  IDM
 SG_ RatAct : 215|8@0+ (0.1,0) [0|25.5] "NoUnit"  IDM
 SG_ TC_SLIP_STATE : 191|3@0+ (1,0) [0|7] ""  IDM

BO_ 161 CSA2: 8 GW
 SG_ RollingCounter_CSA2 : 59|4@0+ (1,0) [0|15] ""  IDM
 SG_ HWA_OK_OFFSwt : 60|1@0+ (1,0) [0|1] ""  IDM
 SG_ ManualShiftReq : 63|3@0+ (1,0) [0|7] ""  IDM
 SG_ CC_ACCSwtErr : 48|1@0+ (1,0) [0|1] ""  IDM
 SG_ ACCTimeGapSetSwt : 49|1@0+ (1,0) [0|1] "NoUnit"  IDM
 SG_ CC_ACC_DecSetSpd_SetSwt : 50|1@0+ (1,0) [0|1] ""  IDM
 SG_ CC_ACC_IncSetSpd_ResuSwt : 51|1@0+ (1,0) [0|1] ""  IDM
 SG_ SAS_Sts : 55|2@0+ (1,0) [0|3] ""  IDM
 SG_ ACC_TimeGap_DecSetSwt : 44|1@0+ (1,0) [0|1] ""  IDM
 SG_ ACC_TimeGap_IncSetSwt : 45|1@0+ (1,0) [0|1] ""  IDM
 SG_ CC_ACC_CANCEL_OFFSwt : 46|1@0+ (1,0) [0|1] ""  IDM
 SG_ CC_ACC_CRUISE_OFFSwt : 47|1@0+ (1,0) [0|1] ""  IDM
 SG_ SteerWheelSpdSign : 32|1@0+ (1,0) [0|1] ""  IDM
 SG_ SteerWheelSpd : 31|15@0+ (0.1,0) [0|1016] "deg/s"  IDM
 SG_ SteerWheelAngSign : 16|1@0+ (1,0) [0|1] ""  IDM
 SG_ SteerWheelAng : 15|15@0+ (0.1,0) [0|780] "deg"  IDM
 SG_ Checksum_CSA2 : 7|8@0+ (1,0) [0|255] ""  IDM

BO_ 181 VCU_FD1: 64 GW
 SG_ RollingCounter_VCU19 : 443|4@0+ (1,0) [0|14] ""  IDM
 SG_ FuelCutOffReq : 444|1@0+ (1,0) [0|1] ""  IDM
 SG_ FullTrqReq : 445|1@0+ (1,0) [0|1] ""  IDM
 SG_ RelsIGNReq : 446|1@0+ (1,0) [0|1] ""  IDM
 SG_ HCU_GentrIdleSts_Flg : 447|1@0+ (1,0) [0|1] "NoUnit"  IDM
 SG_ HCU_EngStartPre : 432|1@0+ (1,0) [0|1] "NoUnit"  IDM
 SG_ CrsCtrlOvldAccelPedal : 433|1@0+ (1,0) [0|1] ""  IDM
 SG_ HCU_EngStopReq : 434|1@0+ (1,0) [0|1] ""  IDM
 SG_ HCU_EngStartReq : 435|1@0+ (1,0) [0|1] "NoUnit"  IDM
 SG_ TotWheelTrq_FA : 431|12@0+ (5,-6000) [-6000|14475] "Nm"  IDM
 SG_ NoRampsReq : 416|1@0+ (1,0) [0|1] ""  IDM
 SG_ FastTrqIntvntn : 417|1@0+ (1,0) [0|1] ""  IDM
 SG_ HCU_EngIdleReq : 400|1@0+ (1,0) [0|1] "NoUnit"  IDM
 SG_ TotWheelTrqVld_FA : 401|1@0+ (1,0) [0|1] "NoUnit"  IDM
 SG_ TrqAct_RAValid : 403|1@0+ (1,0) [0|1] ""  IDM
 SG_ TrqAct_RA : 399|12@0+ (0.5,-1024) [-1024|1023.5] "Perc"  IDM
 SG_ Checksum_VCU19 : 391|8@0+ (1,0) [0|255] ""  IDM
 SG_ RollingCounter_VCU8 : 379|4@0+ (1,0) [0|14] ""  IDM
 SG_ HCU_PTRdy : 380|1@0+ (1,0) [0|1] ""  IDM
 SG_ AntiSurgeDamperInhb : 381|1@0+ (1,0) [0|1] ""  IDM
 SG_ IdleTrqReserveReq : 375|10@0+ (1,-224) [-224|799] "Nm"  IDM
 SG_ HCU_EngStopReq_Mon : 360|1@0+ (1,0) [0|1] ""  IDM
 SG_ HCU_TrqInterventionStateESP : 362|2@0+ (1,0) [0|3] ""  IDM
 SG_ HCU_TrsmStsReq : 363|1@0+ (1,0) [0|1] ""  IDM
 SG_ IdleLoadTrq : 359|12@0+ (0.25,-224) [-224|799.5] "Nm"  IDM
 SG_ TrqReqSlowPath : 339|12@0+ (0.25,-224) [-224|799.5] "Nm"  IDM
 SG_ TrqReqFastPath : 335|12@0+ (0.25,-224) [-224|799.5] "Nm"  IDM
 SG_ Checksum_VCU8 : 327|8@0+ (1,0) [0|255] ""  IDM
 SG_ RollingCounter_VCU15 : 315|4@0+ (1,0) [0|15] "NoUnit"  IDM
 SG_ TotWheelTrq_RA : 311|12@0+ (5,-6000) [-6000|14475] "Nm"  IDM
 SG_ VCU_RespHWP : 296|1@0+ (1,0) [0|1] "NoUnit"  IDM
 SG_ TotWheelTrqVld_RA : 297|1@0+ (1,0) [0|1] "NoUnit"  IDM
 SG_ VCU_HWPInterface : 289|2@0+ (1,0) [0|3] "NoUnit"  IDM
 SG_ VCU_HWPInterErrReason : 287|4@0+ (1,0) [0|15] "NoUnit"  IDM
 SG_ VCU_DrvrIntvGearSts : 271|1@0+ (1,0) [0|1] "NoUnit"  IDM
 SG_ Checksum_VCU15 : 263|8@0+ (1,0) [0|255] "NoUnit"  IDM
 SG_ RollingCounter_VCU6 : 251|4@0+ (1,0) [0|15] ""  IDM
 SG_ VCU_RaceLaunchAvlSts : 253|2@0+ (1,0) [0|3] ""  IDM
 SG_ VCU_ActAccrPedlRat : 247|8@0+ (0.3937,0) [0|100.3935] "Perc"  IDM
 SG_ VCU_AutParkAvlSts : 227|1@0+ (1,0) [0|1] "No Unit"  IDM
 SG_ VCU_BrkPedlSts : 217|2@0+ (1,0) [0|3] "No Unit"  IDM
 SG_ HCU_BrkPedalStsValid : 218|1@0+ (1,0) [0|1] "NoUnit"  IDM
 SG_ VCU_APedlPosVld : 219|1@0+ (1,0) [0|1] "No Unit"  IDM
 SG_ VCU_AccelPedalPosnValid : 220|1@0+ (1,0) [0|1] "NoUnit"  IDM
 SG_ VCU_VirtAccrPedlRat : 207|8@0+ (0.3937,0) [0|100.3935] "Perc"  IDM
 SG_ Checksum_VCU6 : 199|8@0+ (1,0) [0|255] ""  IDM
 SG_ RollingCounter_VCU4 : 187|4@0+ (1,0) [0|14] ""  IDM
 SG_ VCU_CurrRgnTqVld : 189|2@0+ (1,0) [0|3] ""  IDM
 SG_ VCU_MaxAvlRgnTqVld : 191|2@0+ (1,0) [0|3] ""  IDM
 SG_ VCU_EPBActvReqVld : 176|1@0+ (1,0) [0|1] ""  IDM
 SG_ VCU_EPBActvReq : 177|1@0+ (1,0) [0|1] ""  IDM
 SG_ VCU_CurrRgnTq : 159|16@0+ (1,-32768) [-32768|32767] "Nm"  IDM
 SG_ VCU_MaxAvlRgnTq : 143|16@0+ (1,-32768) [-32768|32767] "Nm"  IDM
 SG_ Checksum_VCU4 : 135|8@0+ (1,0) [0|255] ""  IDM
 SG_ RollingCounter_VCU1 : 123|4@0+ (1,0) [0|14] ""  IDM
 SG_ VCU_HvPowerCtrl : 126|3@0+ (1,0) [0|7] ""  IDM
 SG_ VCU_IntellEscapeSts : 107|1@0+ (1,0) [0|1] ""  IDM
 SG_ VCU_LoUBattSpU : 103|8@0+ (0.05,4) [4|16] "V"  IDM
 SG_ VCU_DCDCModReq : 90|3@0+ (1,0) [0|7] ""  IDM
 SG_ VCU_ChrgEna : 92|2@0+ (1,0) [0|3] ""  IDM
 SG_ VCU_ACURefFailr : 81|2@0+ (1,0) [0|3] ""  IDM
 SG_ VCU_RaceLaunchSts : 87|3@0+ (1,0) [0|7] ""  IDM
 SG_ VCU_ACUEmgyShiftNReq : 72|1@0+ (1,0) [0|1] ""  IDM
 SG_ VCU_ShiftAllwdCmd_ACU : 73|1@0+ (1,0) [0|1] ""  IDM
 SG_ VCU_TgtGearReq_ACU : 76|3@0+ (1,0) [0|7] ""  IDM
 SG_ VCU_ACUSleepReq : 77|1@0+ (1,0) [0|1] ""  IDM
 SG_ VCU_RefAllwdCmd_ACU : 78|1@0+ (1,0) [0|1] ""  IDM
 SG_ VCU_ACUEmgyEngageReq : 79|1@0+ (1,0) [0|1] ""  IDM
 SG_ Checksum_VCU1 : 71|8@0+ (1,0) [0|255] ""  IDM
 SG_ RollingCounter_VCU18 : 59|4@0+ (1,0) [0|14] ""  IDM
 SG_ HCU_K0ClutchStatusReq : 61|2@0+ (1,0) [0|3] ""  IDM
 SG_ HCU_MinEngTrqLimValid : 62|1@0+ (1,0) [0|1] ""  IDM
 SG_ FastRedTrqLimValid : 63|1@0+ (1,0) [0|1] ""  IDM
 SG_ HCU_TrsmClutchStatusReq : 49|2@0+ (1,0) [0|3] ""  IDM
 SG_ HCU_TrsmClutchTargetSpeedDif : 43|10@0+ (1,-500) [-500|500] ""  IDM
 SG_ HCU_K0ClutchTrqReq : 39|12@0+ (0.05,-100) [-100|100] ""  IDM
 SG_ HCU_MinTrqLim_TrsmClutch : 19|12@0+ (0.05,-100) [-100|100] "Perc"  IDM
 SG_ HCU_FastRedTrqLim_TrsmClutch : 15|12@0+ (0.05,-100) [-100|100] "Perc"  IDM
 SG_ Checksum_VCU18 : 7|8@0+ (1,0) [0|255] ""  IDM

BO_ 189 ESP_FD1: 16 GW
 SG_ RollingCounter_ESP12 : 123|4@0+ (1,0) [0|15] "NoUnit"  IDM
 SG_ ESP_VehHldSts : 107|1@0+ (1,0) [0|1] "NoUnit"  IDM
 SG_ TgtRcprtnTrqReq : 79|14@0+ (1,-16383) [-16383|0] "Nm"  IDM
 SG_ Checksum_ESP12 : 71|8@0+ (1,0) [0|255] "NoUnit"  IDM
 SG_ TgtRcprtnTrqSts : 53|2@0+ (1,0) [0|3] "NoUnit"  IDM

BO_ 199 SBWM1: 8 GW
 SG_ E_ShiftFault : 18|2@0+ (1,0) [0|3] ""  IDM
 SG_ DrvReqPark : 20|2@0+ (1,0) [0|2] ""  IDM
 SG_ DRV_RQ_SHFT : 15|4@0+ (1,0) [0|15] ""  IDM

BO_ 216 ESP10: 8 GW
 SG_ ESP_VehHldSts : 45|1@0+ (1,0) [0|1] "NoUnit"  IDM

BO_ 240 ACU1: 8 GW
 SG_ ACU_ShiftInProgress : 36|2@0+ (1,0) [0|3] "NoUnit"  IDM

BO_ 669 AC1: 8 GW
 SG_ InCarTemp : 15|8@0+ (0.5,-40) [-40|86.5] "°C"  IDM

BO_ 901 AC2: 8 GW
 SG_ ACAmbTemp : 23|8@0+ (0.5,-40) [-40|86.5] "°C"  IDM
 SG_ ACFrntBlwrSpd : 11|4@0+ (1,0) [0|15] ""  IDM

BO_ 688 DRDCM1: 8 GW
 SG_ DrvRearDoorWinPosnSts_Perc : 15|5@0+ (1,0) [0|31] "NoUnit"  IDM

BO_ 714 DDCM1: 8 GW
 SG_ DrvWinPosnSts_Perc : 42|5@0+ (1,0) [0|31] ""  IDM
 SG_ RSDS_Driver_LED_Sts : 9|1@0+ (1,0) [0|1] ""  IDM

BO_ 680 EEM1: 8 CEM20
 SG_ TranPMode_Sts : 7|1@0+ (1,0) [0|1] "NoUnit"  IDM

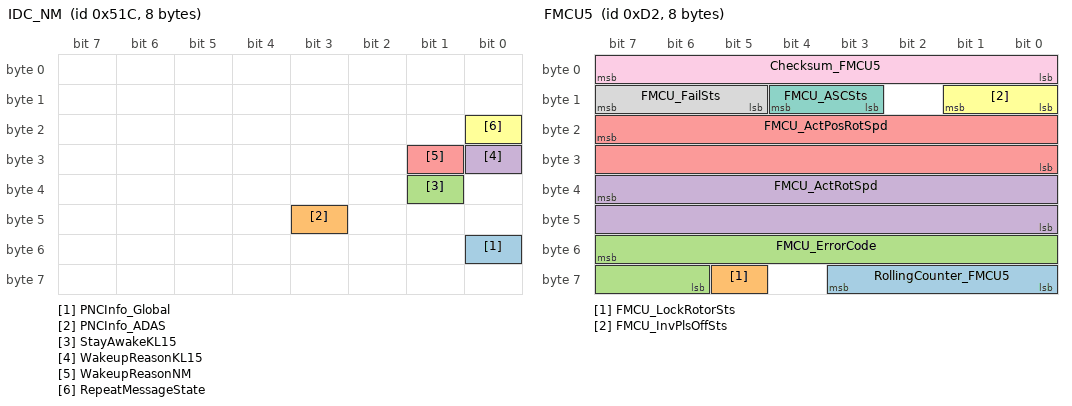
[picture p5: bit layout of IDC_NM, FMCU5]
BO_ 1308 IDC_NM: 8 IDM
 SG_ PNCInfo_Global : 48|1@0+ (1,0) [0|1] "" Vector__XXX
 SG_ PNCInfo_ADAS : 43|1@0+ (1,0) [0|1] "" Vector__XXX
 SG_ StayAwakeKL15 : 33|1@0+ (1,0) [0|1] "" Vector__XXX
 SG_ WakeupReasonKL15 : 24|1@0+ (1,0) [0|1] "" Vector__XXX
 SG_ WakeupReasonNM : 25|1@0+ (1,0) [0|1] "" Vector__XXX
 SG_ RepeatMessageState : 16|1@0+ (1,0) [0|1] "" Vector__XXX

BO_ 1751 IDC_Phy_Req: 8 Tester
 SG_ IDC_Phy_Req : 7|64@0+ (1,0) [0|18446744073709600768] ""  IDM

BO_ 1888 DiagFuncReq: 8 Tester
 SG_ DiagFuncReq : 7|64@0+ (1,0) [0|18446744073709600768] ""  IDM

BO_ 1906 FR_Phy_Req: 8 Tester
 SG_ FR_Phy_Req : 7|64@0+ (1,0) [0|18446744073709600768] ""  IDM

BO_ 1759 IDC_Phy_Resp: 8 IDM
 SG_ IDC_Phy_Resp : 7|64@0+ (1,0) [0|18446744073709600768] ""  Tester

BO_ 1970 FR_Phy_Resp: 8 IDM
 SG_ FR_Phy_Resp : 7|64@0+ (1,0) [0|18446744073709600768] "" Vector__XXX

BO_ 148 FMCU4: 8 GW
 SG_ FMCU_ActualOperMod : 63|4@0+ (1,0) [0|15] "" Vector__XXX
 SG_ FMCU_ActTrq : 31|14@0+ (0.1,-819) [-819|819] "Nm" Vector__XXX

BO_ 210 FMCU5: 8 GW
 SG_ RollingCounter_FMCU5 : 59|4@0+ (1,0) [0|14] "" Vector__XXX
 SG_ FMCU_LockRotorSts : 61|1@0+ (1,0) [0|1] "" Vector__XXX
 SG_ FMCU_ErrorCode : 55|10@0+ (1,0) [0|1023] "" Vector__XXX
 SG_ FMCU_ActRotSpd : 39|16@0+ (1,-20000) [-20000|45534] "rpm" Vector__XXX
 SG_ FMCU_ActPosRotSpd : 23|16@0+ (1,0) [0|65534] "rpm" Vector__XXX
 SG_ FMCU_InvPlsOffSts : 9|2@0+ (1,0) [0|3] "" Vector__XXX
 SG_ FMCU_ASCSts : 12|2@0+ (1,0) [0|3] "" Vector__XXX
 SG_ FMCU_FailSts : 15|3@0+ (1,0) [0|7] "" Vector__XXX
 SG_ Checksum_FMCU5 : 7|8@0+ (1,0) [0|255] "" Vector__XXX

BO_ 230 RMCU3: 8 GW
 SG_ RMCU_ActTrq : 47|14@0+ (0.1,-819) [-819|819] "Nm" Vector__XXX

BO_ 231 RMCU4: 8 GW
 SG_ RMCU_ActualOperMod : 63|4@0+ (1,0) [0|15] "" Vector__XXX
 SG_ RMCU_ActRotSpd : 31|16@0+ (1,-20000) [-20000|45534] "rpm" Vector__XXX

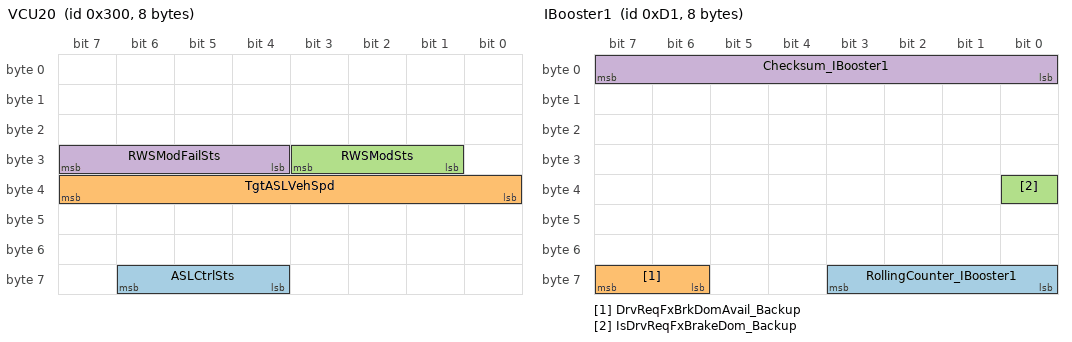
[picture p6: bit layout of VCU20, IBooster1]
BO_ 768 VCU20: 8 GW
 SG_ ASLCtrlSts : 62|3@0+ (1,0) [0|7] "" Vector__XXX
 SG_ TgtASLVehSpd : 39|8@0+ (1,0) [0|255] "" Vector__XXX
 SG_ RWSModSts : 27|3@0+ (1,0) [0|7] "" Vector__XXX
 SG_ RWSModFailSts : 31|4@0+ (1,0) [0|15] "" Vector__XXX

BO_ 188 RWS1: 16 GW
 SG_ RWS_FailSts : 63|2@0+ (1,0) [0|3] "" Vector__XXX
 SG_ RWS_SteerSpd : 38|9@0+ (0.1,-0.1) [0|27] "DegPerSec" Vector__XXX
 SG_ RWS_SteerSpdVld : 39|1@0+ (1,0) [0|1] "" Vector__XXX
 SG_ RWS_AngActVld : 24|1@0+ (1,0) [0|1] "" Vector__XXX
 SG_ RWS_AngAct : 23|12@0+ (0.01,-10) [-10|10] "Deg" Vector__XXX
 SG_ RWS_StsResp : 15|2@0+ (1,0) [0|3] "" Vector__XXX

BO_ 209 IBooster1: 8 GW
 SG_ RollingCounter_IBooster1 : 59|4@0+ (1,0) [0|15] "" Vector__XXX
 SG_ DrvReqFxBrkDomAvail_Backup : 63|2@0+ (1,0) [0|3] "" Vector__XXX
 SG_ IsDrvReqFxBrakeDom_Backup : 32|1@0+ (1,0) [0|1] "" Vector__XXX
 SG_ Checksum_IBooster1 : 7|8@0+ (1,0) [0|255] "" Vector__XXX

BO_ 241 BMS4: 8 GW
 SG_ BMS_ErrCategory : 62|3@0+ (1,0) [0|7] "" Vector__XXX

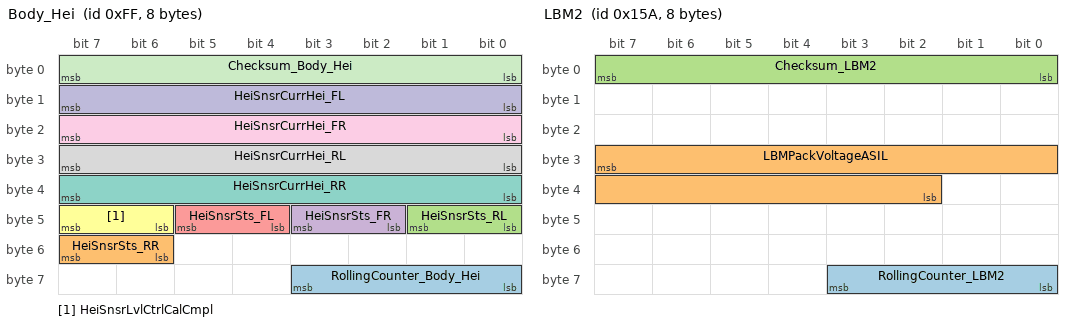
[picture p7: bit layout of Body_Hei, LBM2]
BO_ 255 Body_Hei: 8 GW
 SG_ RollingCounter_Body_Hei : 59|4@0+ (1,0) [0|14] "" Vector__XXX
 SG_ HeiSnsrSts_RR : 55|2@0+ (1,0) [0|3] "" Vector__XXX
 SG_ HeiSnsrSts_RL : 41|2@0+ (1,0) [0|3] "" Vector__XXX
 SG_ HeiSnsrSts_FR : 43|2@0+ (1,0) [0|3] "" Vector__XXX
 SG_ HeiSnsrSts_FL : 45|2@0+ (1,0) [0|3] "" Vector__XXX
 SG_ HeiSnsrLvlCtrlCalCmpl : 47|2@0+ (1,0) [0|3] "" Vector__XXX
 SG_ HeiSnsrCurrHei_RR : 39|8@0+ (1.2,-151.2) [-150|153.6] "mm" Vector__XXX
 SG_ HeiSnsrCurrHei_RL : 31|8@0+ (1.2,-151.2) [-150|153.6] "mm" Vector__XXX
 SG_ HeiSnsrCurrHei_FR : 23|8@0+ (1.2,-151.2) [-150|153.6] "mm" Vector__XXX
 SG_ HeiSnsrCurrHei_FL : 15|8@0+ (1.2,-151.2) [-150|153.6] "mm" Vector__XXX
 SG_ Checksum_Body_Hei : 7|8@0+ (1,0) [0|255] "" Vector__XXX

BO_ 287 RBC_FD1: 64 GW
 SG_ L3_ADCRampOffSuspendSts_Backup : 9|2@0+ (1,0) [0|3] "" Vector__XXX

BO_ 288 IBooster_FD2: 64 GW
 SG_ RollingCounter_ABS2_Backup : 379|4@0+ (1,0) [0|15] "" Vector__XXX
 SG_ WssRREdgesSumVld_Backup : 382|1@0+ (1,0) [0|1] "" Vector__XXX
 SG_ WssRLEdgesSumVld_Backup : 383|1@0+ (1,0) [0|1] "" Vector__XXX
 SG_ WssRLEdgesSum_Backup : 375|8@0+ (1,0) [0|255] "" Vector__XXX
 SG_ WssRREdgesSum_Backup : 367|8@0+ (1,0) [0|255] "" Vector__XXX
 SG_ RRWheelSpd_Backup : 348|13@0+ (0.05625,0) [0|299.98125] "kph" Vector__XXX
 SG_ RRWheelSpdVld_Backup : 349|1@0+ (1,0) [0|1] "" Vector__XXX
 SG_ RRWheelDriveDirection_Backup : 351|2@0+ (1,0) [0|3] "" Vector__XXX
 SG_ RLWheelSpd_Backup : 332|13@0+ (0.05625,0) [0|299.98125] "kph" Vector__XXX
 SG_ RLWheelSpdVld_Backup : 333|1@0+ (1,0) [0|1] "" Vector__XXX
 SG_ RLWheelDriveDirection_Backup : 335|2@0+ (1,0) [0|3] "" Vector__XXX
 SG_ Checksum_ABS2_Backup : 327|8@0+ (1,0) [0|255] "" Vector__XXX
 SG_ RollingCounter_IBooster_FD2_5 : 315|4@0+ (1,0) [0|15] "" Vector__XXX
 SG_ Checksum_IBooster_FD2_5 : 263|8@0+ (1,0) [0|255] "" Vector__XXX
 SG_ RollingCounter_ABS3_Backup : 251|4@0+ (1,0) [0|15] "" Vector__XXX
 SG_ VehSpd_Backup : 204|13@0+ (0.05625,0) [0|299.98125] "kph" Vector__XXX
 SG_ VehSpdVld_Backup : 205|1@0+ (1,0) [0|1] "" Vector__XXX
 SG_ Checksum_ABS3_Backup : 199|8@0+ (1,0) [0|255] "" Vector__XXX
 SG_ RollingCounter_ABS1_Backup : 187|4@0+ (1,0) [0|15] "" Vector__XXX
 SG_ WssFREdgesSumVld_Backup : 190|1@0+ (1,0) [0|1] "" Vector__XXX
 SG_ WssFLEdgesSumVld_Backup : 191|1@0+ (1,0) [0|1] "" Vector__XXX
 SG_ WssFREdgesSum_Backup : 183|8@0+ (1,0) [0|255] "" Vector__XXX
 SG_ WssFLEdgesSum_Backup : 175|8@0+ (1,0) [0|255] "" Vector__XXX
 SG_ FRWheelSpd_Backup : 156|13@0+ (0.05625,0) [0|299.98125] "kph" Vector__XXX
 SG_ FRWheelSpdVld_Backup : 157|1@0+ (1,0) [0|1] "" Vector__XXX
 SG_ FRWheelDriveDirection_Backup : 159|2@0+ (1,0) [0|3] "" Vector__XXX
 SG_ FLWheelSpd_Backup : 140|13@0+ (0.05625,0) [0|299.98125] "kph" Vector__XXX
 SG_ FLWheelSpdVld_Backup : 141|1@0+ (1,0) [0|1] "" Vector__XXX
 SG_ FLWheelDriveDirection_Backup : 143|2@0+ (1,0) [0|3] "" Vector__XXX
 SG_ Checksum_ABS1_Backup : 135|8@0+ (1,0) [0|255] "" Vector__XXX
 SG_ VehStandstill_Backup : 78|2@0+ (1,0) [0|3] "" Vector__XXX
 SG_ IB_BrkPedalAppldVld : 10|2@0+ (1,0) [0|3] "" Vector__XXX
 SG_ IB_BrkPedalAppld : 11|1@0+ (1,0) [0|1] "" Vector__XXX

BO_ 296 DCDC1: 8 GW
 SG_ DCDC_FailSts : 63|4@0+ (1,0) [0|15] "" Vector__XXX

BO_ 320 RWA_FD2: 24 GW
 SG_ RollingCounter_RWA_FD2_2 : 123|4@0+ (1,0) [0|14] "" Vector__XXX
 SG_ SBWActr_PinionAngSpd_Backup : 81|15@0+ (0.1,-1016.1) [-1016|1016] "DegPerSec" Vector__XXX
 SG_ SBWActr_PinionAng_Backup : 79|14@0+ (0.1,-780.1) [-780|780] "Deg" Vector__XXX
 SG_ Checksum_RWA_FD2_2 : 71|8@0+ (1,0) [0|255] "" Vector__XXX

BO_ 326 VDC_FD1: 24 GW
 SG_ SuspLvlTrigSrc : 83|3@0+ (1,0) [0|7] "" Vector__XXX
 SG_ RollingCounter_VDC1 : 59|4@0+ (1,0) [0|15] "" Vector__XXX
 SG_ LvlCtrlCalCmpl : 63|1@0+ (1,0) [0|1] "" Vector__XXX
 SG_ TarLvlChg : 51|3@0+ (1,0) [0|7] "" Vector__XXX
 SG_ CurrLvlCtrlMode : 54|3@0+ (1,0) [0|7] "" Vector__XXX
 SG_ CurrHei_RR : 47|8@0+ (1.2,-150) [-150|154.8] "mm" Vector__XXX
 SG_ CurrHei_RL : 39|8@0+ (1.2,-150) [-150|154.8] "mm" Vector__XXX
 SG_ CurrHei_FR : 31|8@0+ (1.2,-150) [-150|154.8] "mm" Vector__XXX
 SG_ CurrHei_FL : 23|8@0+ (1.2,-150) [-150|154.8] "mm" Vector__XXX
 SG_ LvlAdjmtSts : 10|3@0+ (1,0) [0|7] "" Vector__XXX
 SG_ Checksum_VDC1 : 7|8@0+ (1,0) [0|255] "" Vector__XXX

BO_ 332 RWA_FD1: 24 GW
 SG_ RollingCounter_RWA_FD1_2 : 123|4@0+ (1,0) [0|14] "" Vector__XXX
 SG_ SBWActr_PinionAngSpd : 81|15@0+ (0.1,-1016.1) [-1016|1016] "DegPerSec" Vector__XXX
 SG_ SBWActr_PinionAng : 79|14@0+ (0.1,-780.1) [-780|780] "Deg" Vector__XXX
 SG_ Checksum_RWA_FD1_2 : 71|8@0+ (1,0) [0|255] "" Vector__XXX

BO_ 346 LBM2: 8 GW
 SG_ RollingCounter_LBM2 : 59|4@0+ (1,0) [0|15] "" Vector__XXX
 SG_ LBMPackVoltageASIL : 31|14@0+ (0.001,0) [0|16.382] "V" Vector__XXX
 SG_ Checksum_LBM2 : 7|8@0+ (1,0) [0|255] "" Vector__XXX

BO_ 356 EPS_FD2: 64 GW
 SG_ RollingCounter_EPS_FD2_3 : 187|4@0+ (1,0) [0|14] "" Vector__XXX
 SG_ Checksum_EPS_FD2_3 : 135|8@0+ (1,0) [0|255] "" Vector__XXX
 SG_ RollingCounter_EPS_FD2_2 : 123|4@0+ (1,0) [0|14] "" Vector__XXX
 SG_ EPS_LKATrqOvlDlvdSts_Backup : 115|2@0+ (1,0) [0|3] "" Vector__XXX
 SG_ EPS_LKAAngDlvdSts_Backup : 117|2@0+ (1,0) [0|3] "" Vector__XXX
 SG_ EPS_HADHndShkRespSt_Backup : 104|3@0+ (1,0) [0|7] "" Vector__XXX
 SG_ EPS_AvailSts_Backup : 107|3@0+ (1,0) [0|3] "" Vector__XXX
 SG_ EPS_DrvInpTrqVal_HiRes_Backup : 103|12@0+ (0.015625,-31.984375) [-31.984375|32] "Nm" Vector__XXX
 SG_ EPS_DrvInpTrqVal_HiResVld_Backup : 88|1@0+ (1,0) [0|1] "" Vector__XXX
 SG_ EPS_AvailStsforHAD_Backup : 90|2@0+ (1,0) [0|3] "" Vector__XXX
 SG_ EPS_HADerror_Reason_Backup : 94|4@0+ (1,0) [0|15] "" Vector__XXX
 SG_ EPS_LKATorqOvrlDlvdVld_Backup : 95|1@0+ (1,0) [0|1] "" Vector__XXX
 SG_ EPS_LKATorqOvrlDlvd_Backup : 79|16@0+ (0.01,-15) [-15|15] "Nm" Vector__XXX
 SG_ Checksum_EPS_FD2_2 : 71|8@0+ (1,0) [0|255] "" Vector__XXX
 SG_ RollingCounter_EPS_FD2_1 : 59|4@0+ (1,0) [0|14] "" Vector__XXX
 SG_ EPS_TrqSnsrSts_Backup : 60|1@0+ (1,0) [0|1] "" Vector__XXX
 SG_ EPS_InterferDetdVld_Backup : 48|1@0+ (1,0) [0|1] "" Vector__XXX
 SG_ EPS_SteerWheelSpd_Backup : 47|15@0+ (0.1,0) [0|1016] "DegPerSec" Vector__XXX
 SG_ EPS_SteerWheelSpdSign_Backup : 32|1@0+ (1,0) [0|1] "" Vector__XXX
 SG_ EPS_SteerWheelAng_Backup : 31|15@0+ (0.1,0) [0|780] "Deg" Vector__XXX
 SG_ EPS_SteerWheelAngVld_Backup : 16|1@0+ (1,0) [0|1] "" Vector__XXX
 SG_ EPS_SteerWheelAngSign_Backup : 17|1@0+ (1,0) [0|1] "" Vector__XXX
 SG_ EPS_InterferDetd_Backup : 12|1@0+ (1,0) [0|1] "" Vector__XXX
 SG_ EPS_AngCmdOverRange_Backup : 13|1@0+ (1,0) [0|1] "" Vector__XXX
 SG_ EPS_FailSts_Backup : 15|2@0+ (1,0) [0|3] "" Vector__XXX
 SG_ Checksum_EPS_FD2_1 : 7|8@0+ (1,0) [0|255] "" Vector__XXX

BO_ 536 DCDC6: 8 GW
 SG_ DCDC_ActSts : 27|4@0+ (1,0) [0|15] "" Vector__XXX

BO_ 597 ZCU_L1: 8 CEM20
 SG_ PhyHazardSwt : 63|1@0+ (1,0) [0|1] "" Vector__XXX
 SG_ RFPosnLmpFailSts_Zone : 40|1@0+ (1,0) [0|1] "" Vector__XXX
 SG_ LFPosnLmpFailSts_Zone : 41|1@0+ (1,0) [0|1] "" Vector__XXX
 SG_ RFTurnLmpFailSts_Zone : 42|1@0+ (1,0) [0|1] "" Vector__XXX
 SG_ LFTurnLmpFailSts_Zone : 43|1@0+ (1,0) [0|1] "" Vector__XXX
 SG_ RLowBeamFailSts_Zone : 46|1@0+ (1,0) [0|1] "" Vector__XXX
 SG_ LLowBeamFailSts_Zone : 47|1@0+ (1,0) [0|1] "" Vector__XXX
 SG_ RHiBeamFailSts_Zone : 32|1@0+ (1,0) [0|1] "" Vector__XXX
 SG_ LHiBeamFailSts_Zone : 33|1@0+ (1,0) [0|1] "" Vector__XXX
 SG_ HiPosnBrkLmpFailSts_Zone : 35|1@0+ (1,0) [0|1] "" Vector__XXX
 SG_ RRFogLmpFailSts_Zone : 38|1@0+ (1,0) [0|1] "" Vector__XXX
 SG_ LRFogLmpFailSts_Zone : 39|1@0+ (1,0) [0|1] "" Vector__XXX
 SG_ RFFogLmpFailSts_Zone : 24|1@0+ (1,0) [0|1] "" Vector__XXX
 SG_ LFFogLmpFailSts_Zone : 25|1@0+ (1,0) [0|1] "" Vector__XXX
 SG_ RBrkLmpFailSts_Zone : 26|1@0+ (1,0) [0|1] "" Vector__XXX
 SG_ LBrkLmpFailSts_Zone : 27|1@0+ (1,0) [0|1] "" Vector__XXX
 SG_ RRPosnLmpFailSts_Zone : 28|1@0+ (1,0) [0|1] "" Vector__XXX
 SG_ LRPosnLmpFailSts_Zone : 29|1@0+ (1,0) [0|1] "" Vector__XXX
 SG_ RRTurnLmpFailSts_Zone : 30|1@0+ (1,0) [0|1] "" Vector__XXX
 SG_ LRTurnLmpFailSts_Zone : 31|1@0+ (1,0) [0|1] "" Vector__XXX
 SG_ HiPosnBrkLmpOutpSts_Zone : 22|1@0+ (1,0) [0|1] "" Vector__XXX
 SG_ PosnLmpOutpSts_Zone : 23|1@0+ (1,0) [0|1] "" Vector__XXX
 SG_ RBrkLmpOutpSts_Zone : 8|1@0+ (1,0) [0|1] "" Vector__XXX
 SG_ LBrkLmpOutpSts_Zone : 9|1@0+ (1,0) [0|1] "" Vector__XXX
 SG_ RFogLmpSts_Zone : 10|1@0+ (1,0) [0|1] "" Vector__XXX
 SG_ FFogLmpSts_Zone : 11|1@0+ (1,0) [0|1] "" Vector__XXX
 SG_ RTurnLmpSts_Zone : 12|1@0+ (1,0) [0|1] "" Vector__XXX
 SG_ LTurnLmpSts_Zone : 13|1@0+ (1,0) [0|1] "" Vector__XXX
 SG_ LowBeamSts_Zone : 14|1@0+ (1,0) [0|1] "" Vector__XXX
 SG_ HiBeamSts_Zone : 15|1@0+ (1,0) [0|1] "" Vector__XXX

BO_ 647 ALS1: 16 GW
 SG_ RollingCounter_HC1 : 59|4@0+ (1,0) [0|15] "" Vector__XXX
 SG_ ALS_FailSts : 8|1@0+ (1,0) [0|1] "" Vector__XXX
 SG_ Checksum_HC1 : 7|8@0+ (1,0) [0|255] "" Vector__XXX

BO_ 748 DVR_FD1: 64 GW
 SG_ DVR_360VideoCaptureReq : 9|1@0+ (1,0) [0|1] "" Vector__XXX
 SG_ DVRSts : 15|4@0+ (1,0) [0|15] "" Vector__XXX

BO_ 770 PEPS4: 8 CEM20
 SG_ WarnKeyInCarWhenExit : 10|1@0+ (1,0) [0|1] "" Vector__XXX

BO_ 772 HCM_L2: 8 GW
 SG_ FLIntellgntAsscLmpSts : 23|2@0+ (1,0) [0|3] "" Vector__XXX

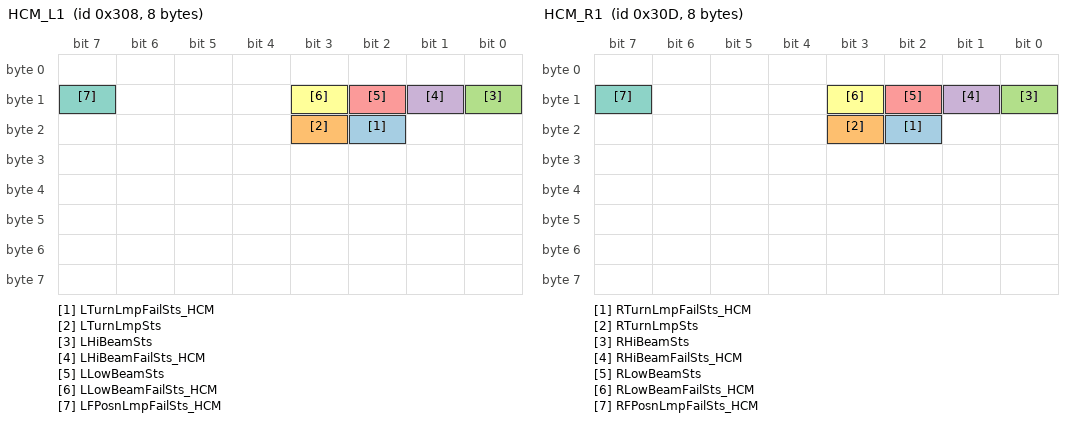
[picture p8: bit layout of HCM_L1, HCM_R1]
BO_ 776 HCM_L1: 8 GW
 SG_ LTurnLmpFailSts_HCM : 18|1@0+ (1,0) [0|1] "" Vector__XXX
 SG_ LTurnLmpSts : 19|1@0+ (1,0) [0|1] "" Vector__XXX
 SG_ LHiBeamSts : 8|1@0+ (1,0) [0|1] "" Vector__XXX
 SG_ LHiBeamFailSts_HCM : 9|1@0+ (1,0) [0|1] "" Vector__XXX
 SG_ LLowBeamSts : 10|1@0+ (1,0) [0|1] "" Vector__XXX
 SG_ LLowBeamFailSts_HCM : 11|1@0+ (1,0) [0|1] "" Vector__XXX
 SG_ LFPosnLmpFailSts_HCM : 15|1@0+ (1,0) [0|1] "" Vector__XXX

BO_ 781 HCM_R1: 8 GW
 SG_ RTurnLmpFailSts_HCM : 18|1@0+ (1,0) [0|1] "" Vector__XXX
 SG_ RTurnLmpSts : 19|1@0+ (1,0) [0|1] "" Vector__XXX
 SG_ RHiBeamSts : 8|1@0+ (1,0) [0|1] "" Vector__XXX
 SG_ RHiBeamFailSts_HCM : 9|1@0+ (1,0) [0|1] "" Vector__XXX
 SG_ RLowBeamSts : 10|1@0+ (1,0) [0|1] "" Vector__XXX
 SG_ RLowBeamFailSts_HCM : 11|1@0+ (1,0) [0|1] "" Vector__XXX
 SG_ RFPosnLmpFailSts_HCM : 15|1@0+ (1,0) [0|1] "" Vector__XXX

BO_ 816 HCM_R2: 8 GW
 SG_ FRIntellgntAsscLmpSts : 23|2@0+ (1,0) [0|3] "" Vector__XXX

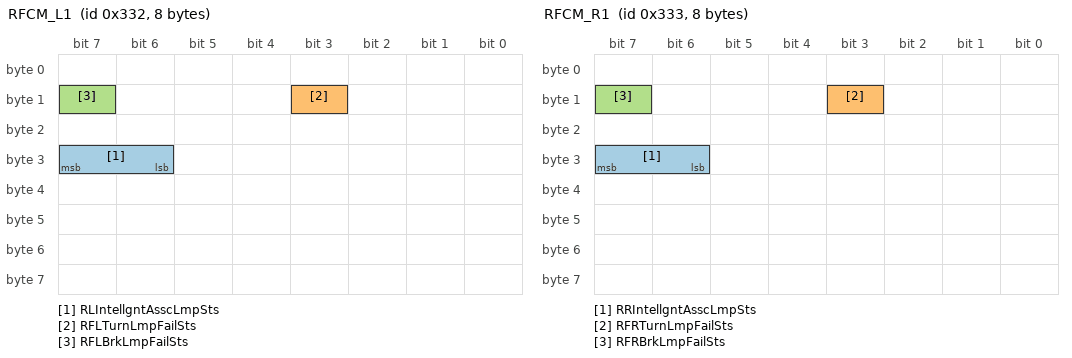
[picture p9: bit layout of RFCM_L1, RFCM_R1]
BO_ 818 RFCM_L1: 8 GW
 SG_ RLIntellgntAsscLmpSts : 31|2@0+ (1,0) [0|3] "" Vector__XXX
 SG_ RFLTurnLmpFailSts : 11|1@0+ (1,0) [0|1] "" Vector__XXX
 SG_ RFLBrkLmpFailSts : 15|1@0+ (1,0) [0|1] "" Vector__XXX

BO_ 819 RFCM_R1: 8 GW
 SG_ RRIntellgntAsscLmpSts : 31|2@0+ (1,0) [0|3] "" Vector__XXX
 SG_ RFRTurnLmpFailSts : 11|1@0+ (1,0) [0|1] "" Vector__XXX
 SG_ RFRBrkLmpFailSts : 15|1@0+ (1,0) [0|1] "" Vector__XXX

BO_ 860 HUT29: 8 GW
 SG_ ValetParkingModSts : 43|2@0+ (1,0) [0|3] "" Vector__XXX

BO_ 879 VCU_FD15: 64 GW
 SG_ WtrPmpSts : 285|2@0+ (1,0) [0|3] "" Vector__XXX
 SG_ WtrPmpActRotSpd : 271|8@0+ (0.4,-0.4) [0|100] "Perc" Vector__XXX

CM_ SG_ 589 DrvGazSts "/";
CM_ SG_ 629 RollingCounter_Trailer2 "ASIL A";
CM_ SG_ 629 TrailerStatusVld "ASIL A";
CM_ SG_ 629 TrailerStatus "ASIL A";
CM_ SG_ 629 Checksum_Trailer2 "ASIL A";
CM_ SG_ 707 IntellgntcurveReq "/";
CM_ SG_ 726 VCU_LTRadrOutlWtrTemp "/";
CM_ SG_ 726 VCU_WtrPmpOpenRateCtrl "/";
CM_ SG_ 726 VCU_VCUSts "/";
CM_ SG_ 726 VCU_ResrDrvRng "/";
CM_ SG_ 726 ChrgnSts "/";
CM_ SG_ 726 VCU_SysFltLmp "/";
CM_ SG_ 726 EnrgFlowInd "/";
CM_ SG_ 726 VCU_PwrLo "/";
CM_ SG_ 726 VCU_EPSEnable "/";
CM_ SG_ 726 VCU_RdyLEDSts "/";
CM_ SG_ 726 VCU_VehBrkLiActv "/";
CM_ SG_ 726 VCU_OPDSts "/";
CM_ SG_ 726 VCU_HeatgAimT "/";
CM_ SG_ 795 VCU_SysFltLvl "/";
CM_ SG_ 799 OBC_CCLineSts "B";
CM_ SG_ 840 IntellgntDrvChildModDetn "/";
CM_ SG_ 849 CrashSev_3 "/";
CM_ SG_ 849 CrashSev_4 "/";
CM_ SG_ 849 ThrdRowLSperSts "/";
CM_ SG_ 849 ThrdRowRSperSts "/";
CM_ SG_ 849 CrashSev_5 "/";
CM_ SG_ 849 AmntOfPass "/";
CM_ SG_ 849 SecRowMidSperSts "/";
CM_ SG_ 849 SecRowRSperSts "/";
CM_ SG_ 849 SecRowLSperSts "/";
CM_ SG_ 849 PassSperSts "/";
CM_ SG_ 849 ThrdRowLSBR_Visual "/";
CM_ SG_ 849 ThrdRowRSBR_Visual "/";
CM_ SG_ 849 ThrdRowLSBR "/";
CM_ SG_ 849 ThrdRowRSBR "/";
CM_ SG_ 849 RSCAOFFSts "/";
CM_ SG_ 1001 MAC_Check_T_BOX_FD3 "/";
CM_ SG_ 1001 FreshnessValue_T_BOX_FD3 "/";
CM_ SG_ 96 RollingCounter_HCU_PT14 "/";
CM_ SG_ 96 EGRreq "/";
CM_ SG_ 96 HCU_TgtGearReq_TCU "/";
CM_ SG_ 96 EmgyEngageReq_TCU "/";
CM_ SG_ 96 EmgyShiftNReq_TCU "/";
CM_ SG_ 96 ShiftAllwdCmd_TCU "/";
CM_ SG_ 96 HCU_bAcvTqCtrl "/";
CM_ SG_ 96 HCU_bAcvSyncReq "/";
CM_ SG_ 96 HCU_TCUPTAllwdCmd "/";
CM_ SG_ 96 HCU_TCUKPAllwdCmd "/";
CM_ SG_ 96 Checksum_HCU_PT14 "/";
CM_ SG_ 96 RollingCounter_HCU_HP11 "/";
CM_ SG_ 96 HCU_TCUEmgyEngageReq "/";
CM_ SG_ 96 HCU_AccPedalPosnCorrdValid "/";
CM_ SG_ 96 TargetGear_RA "/";
CM_ SG_ 96 HCU_TCUEmgyShiftNReq "/";
CM_ SG_ 96 HCU_StLimphm "/";
CM_ SG_ 96 HCU_TrqReq_TrsmClutchValid "/";
CM_ SG_ 96 HCU_AccPedalPosnCorrd "/";
CM_ SG_ 96 Checksum_HCU_HP11 "/";
CM_ SG_ 96 TrqReq_FAValid "/";
CM_ SG_ 96 HCU_EPBReleaseReq "/";
CM_ SG_ 96 TrqReq_FA "/";
CM_ SG_ 96 HCU_ActvSysOperMode "/";
CM_ SG_ 96 HCU_TgtSysOperMode "/";
CM_ SG_ 96 HCU_EPBReleaseReqValid "/";
CM_ SG_ 96 HCU_ChrgDeplt "/";
CM_ SG_ 96 HCU_DCTCreepInhbn "/";
CM_ SG_ 96 HCU_KickDownActv "/";
CM_ SG_ 96 TrqReqFastPathEnable "/";
CM_ SG_ 96 TrqReqSlowPathEnable "/";
CM_ SG_ 96 HCU_EngBrkActv_Flg "/";
CM_ SG_ 96 HCU_TCUSleepReq "/";
CM_ SG_ 96 HCU_TgtSyPosnReq "/";
CM_ SG_ 96 HCU_EVTgtGearSts "/";
CM_ SG_ 96 TrqLowLimit "/";
CM_ SG_ 96 RollingCounter_HCU_HP1 "/";
CM_ SG_ 96 HCU_TgtEngTrqValid "/";
CM_ SG_ 96 HCU_TrqReqWoDCT_TrsmClutchValid "/";
CM_ SG_ 96 HCU_MaxEngTrqLimtValid "/";
CM_ SG_ 96 HCU_NetTrq_TrsmClutchValid "/";
CM_ SG_ 96 HCU_K0ClutchAdaptAck "/";
CM_ SG_ 96 HCU_TrsmClutchAdaptAck "/";
CM_ SG_ 96 HCU_MaxTrqLimt_TrsmClutch "/";
CM_ SG_ 96 HCU_TrqReqWoDCT_TrsmClutch "/";
CM_ SG_ 96 HCU_TrqReq_TrsmClutch "/";
CM_ SG_ 96 HCU_NetTrq_TrsmClutch "/";
CM_ SG_ 96 Checksum_HCU_HP1 "/";
CM_ SG_ 96 RollingCounter_HCU_HP8 "/";
CM_ SG_ 96 HCU_StCluReq "/";
CM_ SG_ 96 TorqueLossValid "/";
CM_ SG_ 96 HCU_TrqLimMax_Norm "/";
CM_ SG_ 96 TorqueLoss "/";
CM_ SG_ 96 Checksum_HCU_HP8 "/";
CM_ SG_ 96 HCU_StartStopTypReq "/";
CM_ SG_ 96 VCU_RoadTyp "/";
CM_ SG_ 96 RollingCounter_HCU_PT11 "/";
CM_ SG_ 96 HCU_TrqCrksftReq "/";
CM_ SG_ 96 HCU_ActTqCrksft "/";
CM_ SG_ 96 HCU_ActTqCrksftValid "/";
CM_ SG_ 96 HCU_RefAllwdCmd_TCU "/";
CM_ SG_ 96 HCU_ECMPumpReq "/";
CM_ SG_ 96 Idle_C_AWDActv "/";
CM_ SG_ 96 Idle_H_AWDActv "/";
CM_ SG_ 96 Idle_E_AWDActv "/";
CM_ SG_ 96 Checksum_HCU_PT11 "/";
CM_ SG_ 161 HWA_OK_OFFSwt "B";
CM_ SG_ 161 CC_ACCSwtErr "A";
CM_ SG_ 161 CC_ACC_DecSetSpd_SetSwt "A";
CM_ SG_ 161 CC_ACC_IncSetSpd_ResuSwt "A";
CM_ SG_ 161 ACC_TimeGap_DecSetSwt "A";
CM_ SG_ 161 ACC_TimeGap_IncSetSwt "A";
CM_ SG_ 161 CC_ACC_CANCEL_OFFSwt "A";
CM_ SG_ 161 CC_ACC_CRUISE_OFFSwt "A";
CM_ SG_ 181 RollingCounter_VCU19 "/";
CM_ SG_ 181 FuelCutOffReq "/";
CM_ SG_ 181 FullTrqReq "/";
CM_ SG_ 181 RelsIGNReq "/";
CM_ SG_ 181 CrsCtrlOvldAccelPedal "/";
CM_ SG_ 181 HCU_EngStopReq "/";
CM_ SG_ 181 NoRampsReq "/";
CM_ SG_ 181 FastTrqIntvntn "/";
CM_ SG_ 181 TrqAct_RAValid "/";
CM_ SG_ 181 TrqAct_RA "/";
CM_ SG_ 181 Checksum_VCU19 "/";
CM_ SG_ 181 RollingCounter_VCU8 "/";
CM_ SG_ 181 HCU_PTRdy "/";
CM_ SG_ 181 AntiSurgeDamperInhb "/";
CM_ SG_ 181 IdleTrqReserveReq "/";
CM_ SG_ 181 HCU_EngStopReq_Mon "/";
CM_ SG_ 181 HCU_TrqInterventionStateESP "/";
CM_ SG_ 181 HCU_TrsmStsReq "/";
CM_ SG_ 181 IdleLoadTrq "/";
CM_ SG_ 181 TrqReqSlowPath "/";
CM_ SG_ 181 TrqReqFastPath "/";
CM_ SG_ 181 Checksum_VCU8 "/";
CM_ SG_ 181 VCU_RespHWP "/";
CM_ SG_ 181 VCU_HWPInterface "/";
CM_ SG_ 181 VCU_RaceLaunchAvlSts "/";
CM_ SG_ 181 VCU_ActAccrPedlRat "/";
CM_ SG_ 181 VCU_AutParkAvlSts "/";
CM_ SG_ 181 VCU_BrkPedlSts "/";
CM_ SG_ 181 HCU_BrkPedalStsValid "/";
CM_ SG_ 181 VCU_APedlPosVld "/";
CM_ SG_ 181 VCU_AccelPedalPosnValid "C";
CM_ SG_ 181 VCU_VirtAccrPedlRat "/";
CM_ SG_ 181 RollingCounter_VCU4 "/";
CM_ SG_ 181 VCU_CurrRgnTqVld "/";
CM_ SG_ 181 VCU_MaxAvlRgnTqVld "/";
CM_ SG_ 181 VCU_EPBActvReqVld "/";
CM_ SG_ 181 VCU_EPBActvReq "/";
CM_ SG_ 181 VCU_CurrRgnTq "/";
CM_ SG_ 181 VCU_MaxAvlRgnTq "/";
CM_ SG_ 181 Checksum_VCU4 "/";
CM_ SG_ 181 RollingCounter_VCU1 "/";
CM_ SG_ 181 VCU_HvPowerCtrl "/";
CM_ SG_ 181 VCU_IntellEscapeSts "/";
CM_ SG_ 181 VCU_LoUBattSpU "/";
CM_ SG_ 181 VCU_DCDCModReq "/";
CM_ SG_ 181 VCU_ChrgEna "/";
CM_ SG_ 181 VCU_ACURefFailr "/";
CM_ SG_ 181 VCU_RaceLaunchSts "/";
CM_ SG_ 181 VCU_ACUEmgyShiftNReq "/";
CM_ SG_ 181 VCU_ShiftAllwdCmd_ACU "/";
CM_ SG_ 181 VCU_TgtGearReq_ACU "/";
CM_ SG_ 181 VCU_ACUSleepReq "/";
CM_ SG_ 181 VCU_RefAllwdCmd_ACU "/";
CM_ SG_ 181 VCU_ACUEmgyEngageReq "/";
CM_ SG_ 181 Checksum_VCU1 "/";
CM_ SG_ 181 RollingCounter_VCU18 "/";
CM_ SG_ 181 HCU_K0ClutchStatusReq "/";
CM_ SG_ 181 HCU_MinEngTrqLimValid "/";
CM_ SG_ 181 FastRedTrqLimValid "/";
CM_ SG_ 181 HCU_TrsmClutchStatusReq "/";
CM_ SG_ 181 HCU_TrsmClutchTargetSpeedDif "/";
CM_ SG_ 181 HCU_K0ClutchTrqReq "/";
CM_ SG_ 181 HCU_MinTrqLim_TrsmClutch "/";
CM_ SG_ 181 HCU_FastRedTrqLim_TrsmClutch "/";
CM_ SG_ 181 Checksum_VCU18 "/";
CM_ SG_ 148 FMCU_ActTrq "C";
CM_ SG_ 210 RollingCounter_FMCU5 "/";
CM_ SG_ 210 FMCU_LockRotorSts "/";
CM_ SG_ 210 FMCU_ErrorCode "/";
CM_ SG_ 210 FMCU_ActPosRotSpd "/";
CM_ SG_ 210 FMCU_InvPlsOffSts "/";
CM_ SG_ 210 FMCU_ASCSts "/";
CM_ SG_ 210 FMCU_FailSts "/";
CM_ SG_ 210 Checksum_FMCU5 "/";
CM_ SG_ 230 RMCU_ActTrq "C";
CM_ SG_ 231 RMCU_ActualOperMod "A";
CM_ SG_ 231 RMCU_ActRotSpd "C";
CM_ SG_ 346 RollingCounter_LBM2 "/";
CM_ SG_ 346 LBMPackVoltageASIL "ASIL B ";
CM_ SG_ 346 Checksum_LBM2 "/";
CM_ SG_ 879 WtrPmpSts "/";
CM_ SG_ 879 WtrPmpActRotSpd "/";
BA_DEF_ BO_  "GenMsgILSupport" ENUM  "No","Yes";
BA_DEF_ BO_  "VFrameFormat" ENUM  "StandardCAN","ExtendedCAN","reserved","reserved","reserved","reserved","reserved","reserved","reserved","reserved","reserved","reserved","reserved","reserved","StandardCAN_FD","ExtendedCAN_FD";
BA_DEF_ BO_  "DiagState" ENUM  "No","Yes";
BA_DEF_ BO_  "DiagRequest" ENUM  "No","Yes";
BA_DEF_ BO_  "DiagResponse" ENUM  "No","Yes";
BA_DEF_ BO_  "NmAsrMessage" ENUM  "No","Yes";
BA_DEF_ SG_  "GenSigSendType" ENUM  "Cyclic","OnWrite","OnWriteWithRepetition","OnChange","OnChangeWithRepetition","IfActive","IfActiveWithRepetition","NoSigSendType","CyclicAndSpontanX","NotUsed","Event","CE";
BA_DEF_ SG_  "IsMonitor" ENUM  "*","Monitor";
BA_DEF_ SG_  "UnitConversionFactor" FLOAT -100 100;
BA_DEF_ SG_  "SigInvalidSetFlag" ENUM  "*","Yes";
BA_DEF_ SG_  "Internal_type" ENUM  "*","UB","UW","UL","SB","SW","SL";
BA_DEF_ SG_  "IsCrcSignal" ENUM  "No","Yes";
BA_DEF_ SG_  "IsRcSignal" ENUM  "No","Yes";
BA_DEF_ BO_  "GenMsgSendType" ENUM  "Cyclic","Event","CE","NotUsed","NotUsed","NotUsed","NotUsed","NotUsed","NoMsgSendType","IfActive","IfActiveWithRepetition","CyclicAndSpontanX";
BA_DEF_ SG_  "GenSigStartValue" INT 0 2147483647;
BA_DEF_ SG_  "GenSigInactiveValue" INT 0 2147483647;
BA_DEF_ BO_  "MsgType" ENUM  "Normal","NM","Diag","";
BA_DEF_ BO_  "GenMsgCycleTime" INT 0 65535;
BA_DEF_DEF_  "GenMsgILSupport" "Yes";
BA_DEF_DEF_  "VFrameFormat" "StandardCAN";
BA_DEF_DEF_  "DiagState" "No";
BA_DEF_DEF_  "DiagRequest" "No";
BA_DEF_DEF_  "DiagResponse" "No";
BA_DEF_DEF_  "NmAsrMessage" "No";
BA_DEF_DEF_  "GenSigSendType" "Cyclic";
BA_DEF_DEF_  "IsMonitor" "*";
BA_DEF_DEF_  "UnitConversionFactor" 1;
BA_DEF_DEF_  "SigInvalidSetFlag" "*";
BA_DEF_DEF_  "Internal_type" "*";
BA_DEF_DEF_  "IsCrcSignal" "No";
BA_DEF_DEF_  "IsRcSignal" "No";
BA_DEF_DEF_  "GenMsgSendType" "Cyclic";
BA_DEF_DEF_  "GenSigStartValue" 0;
BA_DEF_DEF_  "GenSigInactiveValue" 0;
BA_DEF_DEF_  "MsgType" "";
BA_DEF_DEF_  "GenMsgCycleTime" 0;
BA_ "VFrameFormat" BO_ 579 14;
BA_ "MsgType" BO_ 579 0;
BA_ "GenMsgCycleTime" BO_ 579 50;
BA_ "GenSigInactiveValue" SG_ 579 DeviateSpdPreReq 63;
BA_ "GenSigInactiveValue" SG_ 579 DeviateSpdFixdValReq 63;
BA_ "GenSigInactiveValue" SG_ 579 AVM_3DAngleReq 511;
BA_ "VFrameFormat" BO_ 580 14;
BA_ "MsgType" BO_ 580 0;
BA_ "GenMsgCycleTime" BO_ 580 50;
BA_ "VFrameFormat" BO_ 581 14;
BA_ "MsgType" BO_ 581 0;
BA_ "GenMsgCycleTime" BO_ 581 20;
BA_ "GenSigInactiveValue" SG_ 581 RollingCounter_ABM2 15;
BA_ "IsRcSignal" SG_ 581 RollingCounter_ABM2 1;
BA_ "GenSigStartValue" SG_ 581 VehYawRate 8721;
BA_ "GenSigStartValue" SG_ 581 VehLatAccel 22033;
BA_ "GenSigStartValue" SG_ 581 VehLgtAccel 22033;
BA_ "IsCrcSignal" SG_ 581 Checksum_ABM2 1;
BA_ "VFrameFormat" BO_ 589 14;
BA_ "MsgType" BO_ 589 0;
BA_ "GenMsgCycleTime" BO_ 589 50;
BA_ "GenSigStartValue" SG_ 589 DrvBehvSts 7;
BA_ "GenSigInactiveValue" SG_ 589 DrvBehvSts 7;
BA_ "GenSigStartValue" SG_ 589 DMSSts 7;
BA_ "GenSigInactiveValue" SG_ 589 DMSSts 1;
BA_ "GenSigStartValue" SG_ 589 DrowsnsLvl_ACC 7;
BA_ "GenSigInactiveValue" SG_ 589 DrowsnsLvl_ACC 7;
BA_ "GenSigStartValue" SG_ 589 DistrctnLvl_ACC 7;
BA_ "GenSigInactiveValue" SG_ 589 DistrctnLvl_ACC 7;
BA_ "GenSigStartValue" SG_ 589 ExprsnSts 7;
BA_ "GenSigInactiveValue" SG_ 589 ExprsnSts 7;
BA_ "VFrameFormat" BO_ 596 14;
BA_ "MsgType" BO_ 596 0;
BA_ "GenMsgCycleTime" BO_ 596 50;
BA_ "VFrameFormat" BO_ 604 14;
BA_ "MsgType" BO_ 604 0;
BA_ "GenMsgCycleTime" BO_ 604 50;
BA_ "GenSigInactiveValue" SG_ 604 RollingCounter_BLE1 15;
BA_ "IsRcSignal" SG_ 604 RollingCounter_BLE1 1;
BA_ "IsCrcSignal" SG_ 604 Checksum_BLE1 1;
BA_ "VFrameFormat" BO_ 623 14;
BA_ "MsgType" BO_ 623 0;
BA_ "GenMsgCycleTime" BO_ 623 50;
BA_ "GenSigInactiveValue" SG_ 623 RollingCounter_HUT32 15;
BA_ "IsRcSignal" SG_ 623 RollingCounter_HUT32 1;
BA_ "GenSigStartValue" SG_ 623 Ylevel 4094;
BA_ "GenSigInactiveValue" SG_ 623 Ylevel 4095;
BA_ "GenSigStartValue" SG_ 623 Xlevel 4094;
BA_ "GenSigInactiveValue" SG_ 623 Xlevel 4095;
BA_ "GenSigInactiveValue" SG_ 623 ContnPrkgReqValid 1;
BA_ "GenSigInactiveValue" SG_ 623 PrkgCtrlModReqValid 1;
BA_ "GenSigInactiveValue" SG_ 623 ContnPrkgReq 3;
BA_ "IsCrcSignal" SG_ 623 Checksum_HUT32 1;
BA_ "VFrameFormat" BO_ 627 14;
BA_ "MsgType" BO_ 627 0;
BA_ "GenMsgCycleTime" BO_ 627 50;
BA_ "VFrameFormat" BO_ 629 14;
BA_ "MsgType" BO_ 629 0;
BA_ "GenMsgCycleTime" BO_ 629 50;
BA_ "GenSigInactiveValue" SG_ 629 RollingCounter_Trailer2 15;
BA_ "IsRcSignal" SG_ 629 RollingCounter_Trailer2 1;
BA_ "GenSigStartValue" SG_ 629 TrailerStatusVld 1;
BA_ "IsCrcSignal" SG_ 629 Checksum_Trailer2 1;
BA_ "VFrameFormat" BO_ 639 14;
BA_ "MsgType" BO_ 639 0;
BA_ "GenMsgCycleTime" BO_ 639 50;
BA_ "GenSigInactiveValue" SG_ 639 IP_Err 1;
BA_ "GenSigInactiveValue" SG_ 639 IP_ACCErr 1;
BA_ "GenSigInactiveValue" SG_ 639 IP_VehTotDistance 16777215;
BA_ "VFrameFormat" BO_ 659 14;
BA_ "MsgType" BO_ 659 0;
BA_ "GenMsgCycleTime" BO_ 659 100;
BA_ "GenSigInactiveValue" SG_ 659 IP_VelSpdDisp_Mile 255;
BA_ "GenSigInactiveValue" SG_ 659 IP_VehSpdDisp 511;
BA_ "VFrameFormat" BO_ 670 14;
BA_ "MsgType" BO_ 670 0;
BA_ "GenMsgCycleTime" BO_ 670 100;
BA_ "GenSigInactiveValue" SG_ 670 BMS_CC2LineSts 2;
BA_ "VFrameFormat" BO_ 707 14;
BA_ "MsgType" BO_ 707 0;
BA_ "GenMsgCycleTime" BO_ 707 100;
BA_ "GenSigInactiveValue" SG_ 707 ADAS_Posn_Rehead 255;
BA_ "GenSigStartValue" SG_ 707 ADAS_Posn_Spd 511;
BA_ "GenSigInactiveValue" SG_ 707 ADAS_Posn_Spd 511;
BA_ "GenSigInactiveValue" SG_ 707 ADAS_Posn_CurLane 7;
BA_ "GenSigInactiveValue" SG_ 707 ADAS_Posn_PosConfdc 7;
BA_ "GenSigInactiveValue" SG_ 707 ADAS_Posn_Age 511;
BA_ "GenSigInactiveValue" SG_ 707 ADAS_Posn_PosProbb 31;
BA_ "GenSigStartValue" SG_ 707 ADAS_Posn_Offset 8191;
BA_ "GenSigInactiveValue" SG_ 707 ADAS_Posn_Offset 8191;
BA_ "GenSigInactiveValue" SG_ 707 NavTSRTrafSign 255;
BA_ "GenSigStartValue" SG_ 707 HWA_SwtReq 1;
BA_ "GenSigStartValue" SG_ 707 NavCtryType 156;
BA_ "GenSigStartValue" SG_ 707 NavSpdLimUnit_HUT 1;
BA_ "GenSigInactiveValue" SG_ 707 NavSpdLimValue 63;
BA_ "GenSigStartValue" SG_ 707 TSR_SnvtySet 15;
BA_ "GenSigInactiveValue" SG_ 707 TSR_SnvtySet 31;
BA_ "GenSigStartValue" SG_ 707 AEB_PedSwtReq 1;
BA_ "GenSigStartValue" SG_ 707 AEB_VehSwtReq 1;
BA_ "VFrameFormat" BO_ 717 14;
BA_ "MsgType" BO_ 717 0;
BA_ "GenMsgCycleTime" BO_ 717 100;
BA_ "GenSigInactiveValue" SG_ 717 RSDS_Pass_LED_Sts 1;
BA_ "VFrameFormat" BO_ 725 14;
BA_ "MsgType" BO_ 725 0;
BA_ "GenMsgCycleTime" BO_ 725 100;
BA_ "VFrameFormat" BO_ 726 14;
BA_ "MsgType" BO_ 726 0;
BA_ "GenMsgCycleTime" BO_ 726 100;
BA_ "GenSigInactiveValue" SG_ 726 RollingCounter_VCU13 15;
BA_ "IsRcSignal" SG_ 726 RollingCounter_VCU13 1;
BA_ "GenSigInactiveValue" SG_ 726 VCU_LTRadrOutlWtrTemp 255;
BA_ "IsCrcSignal" SG_ 726 Checksum_VCU13 1;
BA_ "GenSigInactiveValue" SG_ 726 RollingCounter_VCU3 15;
BA_ "IsRcSignal" SG_ 726 RollingCounter_VCU3 1;
BA_ "GenSigStartValue" SG_ 726 EnrgFlowInd 1;
BA_ "IsCrcSignal" SG_ 726 Checksum_VCU3 1;
BA_ "GenMsgSendType" BO_ 728 1;
BA_ "VFrameFormat" BO_ 728 14;
BA_ "MsgType" BO_ 728 0;
BA_ "GenSigSendType" SG_ 728 ADAS_Stub_NumOfLaneDrvDir 9;
BA_ "GenSigInactiveValue" SG_ 728 ADAS_Stub_NumOfLaneDrvDir 7;
BA_ "GenSigSendType" SG_ 728 ADAS_Stub_NumOfLaneOppDir 9;
BA_ "GenSigInactiveValue" SG_ 728 ADAS_Stub_NumOfLaneOppDir 3;
BA_ "GenSigSendType" SG_ 728 ADAS_Stub_RtOfWay 9;
BA_ "GenSigInactiveValue" SG_ 728 ADAS_Stub_RtOfWay 3;
BA_ "GenSigSendType" SG_ 728 ADAS_Stub_LastStub 9;
BA_ "GenSigSendType" SG_ 728 ADAS_Stub_TurnAngl 9;
BA_ "GenSigInactiveValue" SG_ 728 ADAS_Stub_TurnAngl 255;
BA_ "GenSigSendType" SG_ 728 ADAS_Stub_FormOfWay 9;
BA_ "GenSigSendType" SG_ 728 ADAS_Stub_CmplxInsct 9;
BA_ "GenSigInactiveValue" SG_ 728 ADAS_Stub_CmplxInsct 3;
BA_ "GenSigSendType" SG_ 728 ADAS_Stub_PartOfCalcRoute 9;
BA_ "GenSigInactiveValue" SG_ 728 ADAS_Stub_PartOfCalcRoute 3;
BA_ "GenSigSendType" SG_ 728 ADAS_Stub_FuncRoadClass 9;
BA_ "GenSigInactiveValue" SG_ 728 ADAS_Stub_FuncRoadClass 7;
BA_ "GenSigSendType" SG_ 728 ADAS_Stub_RelProbb 9;
BA_ "GenSigInactiveValue" SG_ 728 ADAS_Stub_RelProbb 31;
BA_ "GenSigSendType" SG_ 728 ADAS_Stub_Update 9;
BA_ "GenSigSendType" SG_ 728 ADAS_Stub_Retr 9;
BA_ "GenSigSendType" SG_ 728 ADAS_Stub_StubPathIdx 9;
BA_ "GenSigSendType" SG_ 728 ADAS_Stub_PathIdx 9;
BA_ "GenSigSendType" SG_ 728 ADAS_Stub_CycCnt 9;
BA_ "GenSigSendType" SG_ 728 ADAS_Stub_Offset 9;
BA_ "GenSigInactiveValue" SG_ 728 ADAS_Stub_Offset 8191;
BA_ "GenSigSendType" SG_ 728 ADAS_Stub_MsgTyp 9;
BA_ "GenMsgSendType" BO_ 730 1;
BA_ "VFrameFormat" BO_ 730 14;
BA_ "MsgType" BO_ 730 0;
BA_ "GenSigSendType" SG_ 730 ADAS_Seg_NumOfLaneDrvDir 9;
BA_ "GenSigInactiveValue" SG_ 730 ADAS_Seg_NumOfLaneDrvDir 7;
BA_ "GenSigSendType" SG_ 730 ADAS_Seg_NumOfLaneOppDir 9;
BA_ "GenSigInactiveValue" SG_ 730 ADAS_Seg_NumOfLaneOppDir 3;
BA_ "GenSigSendType" SG_ 730 ADAS_Seg_DivideRoad 9;
BA_ "GenSigSendType" SG_ 730 ADAS_Seg_EffSpdLmtTyp 9;
BA_ "GenSigSendType" SG_ 730 ADAS_Seg_EffSpdLmt 9;
BA_ "GenSigSendType" SG_ 730 ADAS_Seg_FormOfWay 9;
BA_ "GenSigSendType" SG_ 730 ADAS_Seg_CmplxInsct 9;
BA_ "GenSigInactiveValue" SG_ 730 ADAS_Seg_CmplxInsct 3;
BA_ "GenSigSendType" SG_ 730 ADAS_Seg_PartOfCalcRoute 9;
BA_ "GenSigInactiveValue" SG_ 730 ADAS_Seg_PartOfCalcRoute 3;
BA_ "GenSigSendType" SG_ 730 ADAS_Seg_FuncRoadClass 9;
BA_ "GenSigInactiveValue" SG_ 730 ADAS_Seg_FuncRoadClass 7;
BA_ "GenSigSendType" SG_ 730 ADAS_Seg_RelProbb 9;
BA_ "GenSigInactiveValue" SG_ 730 ADAS_Seg_RelProbb 31;
BA_ "GenSigSendType" SG_ 730 ADAS_Seg_Update 9;
BA_ "GenSigSendType" SG_ 730 ADAS_Seg_Retr 9;
BA_ "GenSigSendType" SG_ 730 ADAS_Seg_BuildUpArea 9;
BA_ "GenSigInactiveValue" SG_ 730 ADAS_Seg_BuildUpArea 3;
BA_ "GenSigSendType" SG_ 730 ADAS_Seg_Brdg 9;
BA_ "GenSigInactiveValue" SG_ 730 ADAS_Seg_Brdg 3;
BA_ "GenSigSendType" SG_ 730 ADAS_Seg_Tunnel 9;
BA_ "GenSigInactiveValue" SG_ 730 ADAS_Seg_Tunnel 3;
BA_ "GenSigSendType" SG_ 730 ADAS_Seg_PathIdx 9;
BA_ "GenSigSendType" SG_ 730 ADAS_Seg_CycCnt 9;
BA_ "GenSigSendType" SG_ 730 ADAS_Seg_Offset 9;
BA_ "GenSigInactiveValue" SG_ 730 ADAS_Seg_Offset 8191;
BA_ "GenSigSendType" SG_ 730 ADAS_Seg_MsgTyp 9;
BA_ "GenMsgSendType" BO_ 733 1;
BA_ "VFrameFormat" BO_ 733 14;
BA_ "MsgType" BO_ 733 0;
BA_ "GenSigSendType" SG_ 733 ADAS_ProfShort_Value1 9;
BA_ "GenSigSendType" SG_ 733 ADAS_ProfShort_Value0 9;
BA_ "GenSigSendType" SG_ 733 ADAS_ProfShort_Dist1 9;
BA_ "GenSigInactiveValue" SG_ 733 ADAS_ProfShort_Dist1 1023;
BA_ "GenSigStartValue" SG_ 733 ADAS_ProfShort_AccurClass 3;
BA_ "GenSigSendType" SG_ 733 ADAS_ProfShort_AccurClass 9;
BA_ "GenSigSendType" SG_ 733 ADAS_ProfShort_Update 9;
BA_ "GenSigSendType" SG_ 733 ADAS_ProfShort_Retr 9;
BA_ "GenSigSendType" SG_ 733 ADAS_ProfShort_CtrlPoint 9;
BA_ "GenSigSendType" SG_ 733 ADAS_ProfShort_ProfTyp 9;
BA_ "GenSigSendType" SG_ 733 ADAS_ProfShort_PathIdx 9;
BA_ "GenSigSendType" SG_ 733 ADAS_ProfShort_CycCnt 9;
BA_ "GenSigSendType" SG_ 733 ADAS_ProfShort_Offset 9;
BA_ "GenSigInactiveValue" SG_ 733 ADAS_ProfShort_Offset 8191;
BA_ "GenSigSendType" SG_ 733 ADAS_ProfShort_MsgTyp 9;
BA_ "GenMsgSendType" BO_ 734 1;
BA_ "VFrameFormat" BO_ 734 14;
BA_ "MsgType" BO_ 734 0;
BA_ "GenSigSendType" SG_ 734 ADAS_ProfLong_Value 9;
BA_ "GenSigInactiveValue" SG_ 734 ADAS_ProfLong_Value -2147483648;
BA_ "GenSigSendType" SG_ 734 ADAS_ProfLong_Update 9;
BA_ "GenSigSendType" SG_ 734 ADAS_ProfLong_Retr 9;
BA_ "GenSigSendType" SG_ 734 ADAS_ProfLong_CtrlPoint 9;
BA_ "GenSigSendType" SG_ 734 ADAS_ProfLong_ProfTyp 9;
BA_ "GenSigSendType" SG_ 734 ADAS_ProfLong_PathIdx 9;
BA_ "GenSigSendType" SG_ 734 ADAS_ProfLong_CycCnt 9;
BA_ "GenSigSendType" SG_ 734 ADAS_ProfLong_Offset 9;
BA_ "GenSigInactiveValue" SG_ 734 ADAS_ProfLong_Offset 8191;
BA_ "GenSigSendType" SG_ 734 ADAS_ProfLong_MsgTyp 9;
BA_ "VFrameFormat" BO_ 769 14;
BA_ "MsgType" BO_ 769 0;
BA_ "GenMsgCycleTime" BO_ 769 100;
BA_ "GenSigInactiveValue" SG_ 769 CoolerSts 255;
BA_ "VFrameFormat" BO_ 795 14;
BA_ "MsgType" BO_ 795 0;
BA_ "GenMsgCycleTime" BO_ 795 200;
BA_ "VFrameFormat" BO_ 796 14;
BA_ "MsgType" BO_ 796 0;
BA_ "GenMsgCycleTime" BO_ 796 100;
BA_ "VFrameFormat" BO_ 799 14;
BA_ "MsgType" BO_ 799 0;
BA_ "GenMsgCycleTime" BO_ 799 100;
BA_ "GenSigInactiveValue" SG_ 799 OBC_CCLineSts 3;
BA_ "GenMsgSendType" BO_ 822 1;
BA_ "VFrameFormat" BO_ 822 14;
BA_ "MsgType" BO_ 822 0;
BA_ "GenMsgSendType" BO_ 827 1;
BA_ "VFrameFormat" BO_ 827 14;
BA_ "MsgType" BO_ 827 0;
BA_ "GenSigSendType" SG_ 827 LowPowerEgyMngmntModReq 9;
BA_ "GenMsgSendType" BO_ 829 1;
BA_ "VFrameFormat" BO_ 829 14;
BA_ "MsgType" BO_ 829 0;
BA_ "GenSigSendType" SG_ 829 T_BOX_AVPActvReq 9;
BA_ "VFrameFormat" BO_ 840 14;
BA_ "MsgType" BO_ 840 0;
BA_ "GenMsgCycleTime" BO_ 840 500;
BA_ "GenMsgSendType" BO_ 849 11;
BA_ "VFrameFormat" BO_ 849 14;
BA_ "MsgType" BO_ 849 0;
BA_ "GenMsgCycleTime" BO_ 849 500;
BA_ "GenSigInactiveValue" SG_ 849 RollingCounter_ABM1 15;
BA_ "IsRcSignal" SG_ 849 RollingCounter_ABM1 1;
BA_ "GenSigStartValue" SG_ 849 ThrdRowLSperSts 1;
BA_ "GenSigStartValue" SG_ 849 ThrdRowRSperSts 1;
BA_ "GenSigStartValue" SG_ 849 AmntOfPass 1;
BA_ "GenSigStartValue" SG_ 849 SecRowMidSperSts 1;
BA_ "GenSigStartValue" SG_ 849 SecRowRSperSts 1;
BA_ "GenSigStartValue" SG_ 849 SecRowLSperSts 1;
BA_ "GenSigStartValue" SG_ 849 PassSperSts 1;
BA_ "GenSigStartValue" SG_ 849 SecRowRSBR_Visual 1;
BA_ "GenSigStartValue" SG_ 849 ThrdRowLSBR_Visual 1;
BA_ "GenSigStartValue" SG_ 849 ThrdRowRSBR_Visual 1;
BA_ "GenSigStartValue" SG_ 849 ThrdRowLSBR 1;
BA_ "GenSigStartValue" SG_ 849 ThrdRowRSBR 1;
BA_ "GenSigStartValue" SG_ 849 DrvSBR_Visual 1;
BA_ "GenSigStartValue" SG_ 849 PassSBR_Visual 1;
BA_ "GenSigStartValue" SG_ 849 SecRowLSBR_Visual 1;
BA_ "GenSigStartValue" SG_ 849 SecRowMidSBR_Visual 1;
BA_ "GenSigStartValue" SG_ 849 RSCAOFFSts 1;
BA_ "GenSigStartValue" SG_ 849 PassSBLockSts 1;
BA_ "GenSigStartValue" SG_ 849 SecRowRSBLockSts 1;
BA_ "GenSigStartValue" SG_ 849 DrvSBR 1;
BA_ "GenSigStartValue" SG_ 849 SecRowMidSBLockSts 1;
BA_ "GenSigStartValue" SG_ 849 AirbFailLmpCmd 1;
BA_ "GenSigStartValue" SG_ 849 SecRowLSBLockSts 1;
BA_ "GenSigStartValue" SG_ 849 PABSwtSts 1;
BA_ "IsCrcSignal" SG_ 849 Checksum_ABM1 1;
BA_ "VFrameFormat" BO_ 880 14;
BA_ "MsgType" BO_ 880 0;
BA_ "GenMsgCycleTime" BO_ 880 1000;
BA_ "GenSigStartValue" SG_ 880 Time_Year_Right 15;
BA_ "GenSigInactiveValue" SG_ 880 Time_Year_Right 15;
BA_ "GenSigStartValue" SG_ 880 Time_Year_Left 15;
BA_ "GenSigInactiveValue" SG_ 880 Time_Year_Left 15;
BA_ "GenSigStartValue" SG_ 880 Time_Second 63;
BA_ "GenSigInactiveValue" SG_ 880 Time_Second 63;
BA_ "GenSigStartValue" SG_ 880 Time_Minutes 63;
BA_ "GenSigInactiveValue" SG_ 880 Time_Minutes 63;
BA_ "GenSigStartValue" SG_ 880 Time_Hour 31;
BA_ "GenSigInactiveValue" SG_ 880 Time_Hour 31;
BA_ "GenMsgSendType" BO_ 907 11;
BA_ "VFrameFormat" BO_ 907 14;
BA_ "MsgType" BO_ 907 0;
BA_ "GenMsgCycleTime" BO_ 907 500;
BA_ "GenSigInactiveValue" SG_ 907 RollingCounter_PTCC1_1 15;
BA_ "IsRcSignal" SG_ 907 RollingCounter_PTCC1_1 1;
BA_ "GenSigInactiveValue" SG_ 907 BSCSts 4;
BA_ "IsCrcSignal" SG_ 907 Checksum_PTCC1_1 1;
BA_ "VFrameFormat" BO_ 1001 14;
BA_ "MsgType" BO_ 1001 0;
BA_ "GenMsgCycleTime" BO_ 1001 1000;
BA_ "GenSigInactiveValue" SG_ 1001 T_BOX_SysErrSts 1;
BA_ "VFrameFormat" BO_ 1045 14;
BA_ "MsgType" BO_ 1045 0;
BA_ "GenMsgCycleTime" BO_ 1045 5000;
BA_ "GenSigInactiveValue" SG_ 1045 ADAS_Meta_MapVerYear 63;
BA_ "GenSigInactiveValue" SG_ 1045 ADAS_Meta_RegionCode 32767;
BA_ "GenSigStartValue" SG_ 1045 ADAS_Meta_DrvSide 1;
BA_ "GenMsgSendType" BO_ 68 1;
BA_ "VFrameFormat" BO_ 68 14;
BA_ "MsgType" BO_ 68 0;
BA_ "GenSigStartValue" SG_ 68 CarWashModeReq 2;
BA_ "GenSigSendType" SG_ 68 CarWashModeReq 9;
BA_ "GenMsgSendType" BO_ 74 1;
BA_ "VFrameFormat" BO_ 74 14;
BA_ "MsgType" BO_ 74 0;
BA_ "GenSigSendType" SG_ 74 AutoAVMSwSet_Cmd 9;
BA_ "GenSigSendType" SG_ 74 SwToFieldCalRstCmd 9;
BA_ "GenSigSendType" SG_ 74 View_SoftswitchCmd 9;
BA_ "GenSigSendType" SG_ 74 FPAS_AutoModSwt 9;
BA_ "GenSigSendType" SG_ 74 MEBSwtSet 9;
BA_ "GenSigSendType" SG_ 74 CarMdlDispCmd 9;
BA_ "GenSigSendType" SG_ 74 CarMdlTrsprcySwtCmd 9;
BA_ "GenSigSendType" SG_ 74 AutoViewChgCmd 9;
BA_ "GenSigSendType" SG_ 74 SlopViewExitReq 9;
BA_ "GenSigSendType" SG_ 74 LaneCalActvtCmd 9;
BA_ "GenSigSendType" SG_ 74 Sgl_View_Sel 9;
BA_ "GenSigSendType" SG_ 74 AutoAVMmodSet 9;
BA_ "GenSigSendType" SG_ 74 SlopViewFuncSet 9;
BA_ "GenSigSendType" SG_ 74 WheelVieSwt 9;
BA_ "VFrameFormat" BO_ 96 14;
BA_ "MsgType" BO_ 96 0;
BA_ "GenMsgCycleTime" BO_ 96 10;
BA_ "GenSigInactiveValue" SG_ 96 RollingCounter_HCU_PT14 15;
BA_ "IsRcSignal" SG_ 96 RollingCounter_HCU_PT14 1;
BA_ "IsCrcSignal" SG_ 96 Checksum_HCU_PT14 1;
BA_ "GenSigInactiveValue" SG_ 96 RollingCounter_HCU_HP11 15;
BA_ "IsRcSignal" SG_ 96 RollingCounter_HCU_HP11 1;
BA_ "GenSigStartValue" SG_ 96 HCU_AccPedalPosnCorrdValid 1;
BA_ "GenSigStartValue" SG_ 96 HCU_TrqReq_TrsmClutchValid 1;
BA_ "IsCrcSignal" SG_ 96 Checksum_HCU_HP11 1;
BA_ "GenSigInactiveValue" SG_ 96 RollingCounter_HCU_HP10 15;
BA_ "IsRcSignal" SG_ 96 RollingCounter_HCU_HP10 1;
BA_ "GenSigStartValue" SG_ 96 HCU_TCUSleepReq 1;
BA_ "GenSigInactiveValue" SG_ 96 HCU_EVTgtGearSts 2;
BA_ "GenSigInactiveValue" SG_ 96 TrqLowLimit 1023;
BA_ "IsCrcSignal" SG_ 96 Checksum_HCU_HP10 1;
BA_ "GenSigInactiveValue" SG_ 96 RollingCounter_HCU_HP1 15;
BA_ "IsRcSignal" SG_ 96 RollingCounter_HCU_HP1 1;
BA_ "GenSigStartValue" SG_ 96 HCU_TgtEngTrqValid 1;
BA_ "GenSigStartValue" SG_ 96 HCU_TrqReqWoDCT_TrsmClutchValid 1;
BA_ "GenSigStartValue" SG_ 96 HCU_MaxEngTrqLimtValid 1;
BA_ "GenSigStartValue" SG_ 96 HCU_NetTrq_TrsmClutchValid 1;
BA_ "GenSigStartValue" SG_ 96 HCU_MaxTrqLimt_TrsmClutch 500;
BA_ "GenSigStartValue" SG_ 96 HCU_TrqReqWoDCT_TrsmClutch 2000;
BA_ "GenSigStartValue" SG_ 96 HCU_TrqReq_TrsmClutch 2000;
BA_ "GenSigStartValue" SG_ 96 HCU_NetTrq_TrsmClutch 2000;
BA_ "IsCrcSignal" SG_ 96 Checksum_HCU_HP1 1;
BA_ "GenSigInactiveValue" SG_ 96 RollingCounter_HCU_HP8 15;
BA_ "IsRcSignal" SG_ 96 RollingCounter_HCU_HP8 1;
BA_ "GenSigStartValue" SG_ 96 TorqueLossValid 1;
BA_ "GenSigStartValue" SG_ 96 HCU_TrqLimMax_Norm 275;
BA_ "GenSigStartValue" SG_ 96 TorqueLoss 2048;
BA_ "IsCrcSignal" SG_ 96 Checksum_HCU_HP8 1;
BA_ "GenSigInactiveValue" SG_ 96 RollingCounter_HCU_PT1 15;
BA_ "IsRcSignal" SG_ 96 RollingCounter_HCU_PT1 1;
BA_ "GenSigStartValue" SG_ 96 ActWheelTrqDmd 1200;
BA_ "IsCrcSignal" SG_ 96 Checksum_HCU_PT1 1;
BA_ "GenSigInactiveValue" SG_ 96 RollingCounter_HCU_PT11 15;
BA_ "IsRcSignal" SG_ 96 RollingCounter_HCU_PT11 1;
BA_ "GenSigStartValue" SG_ 96 HCU_ActTqCrksftValid 1;
BA_ "IsCrcSignal" SG_ 96 Checksum_HCU_PT11 1;
BA_ "VFrameFormat" BO_ 121 14;
BA_ "MsgType" BO_ 121 0;
BA_ "GenMsgCycleTime" BO_ 121 10;
BA_ "GenSigInactiveValue" SG_ 121 RollingCounter_ECM1 15;
BA_ "IsRcSignal" SG_ 121 RollingCounter_ECM1 1;
BA_ "GenSigStartValue" SG_ 121 EngSpdVldty 2;
BA_ "GenSigInactiveValue" SG_ 121 Start_StopSts 7;
BA_ "GenSigInactiveValue" SG_ 121 BrkPedalSts 3;
BA_ "IsCrcSignal" SG_ 121 Checksum_ECM1 1;
BA_ "VFrameFormat" BO_ 124 14;
BA_ "MsgType" BO_ 124 0;
BA_ "GenMsgCycleTime" BO_ 124 10;
BA_ "GenSigStartValue" SG_ 124 TCU_TrqRatio 65534;
BA_ "GenSigInactiveValue" SG_ 124 TCU_TrqRatio 65535;
BA_ "GenSigStartValue" SG_ 124 RatAct 254;
BA_ "GenSigInactiveValue" SG_ 124 RatAct 255;
BA_ "GenSigInactiveValue" SG_ 124 TC_SLIP_STATE 7;
BA_ "VFrameFormat" BO_ 161 14;
BA_ "MsgType" BO_ 161 0;
BA_ "GenMsgCycleTime" BO_ 161 10;
BA_ "GenSigInactiveValue" SG_ 161 RollingCounter_CSA2 15;
BA_ "IsRcSignal" SG_ 161 RollingCounter_CSA2 1;
BA_ "GenSigInactiveValue" SG_ 161 ManualShiftReq 6;
BA_ "GenSigInactiveValue" SG_ 161 CC_ACCSwtErr 1;
BA_ "GenSigInactiveValue" SG_ 161 SAS_Sts 2;
BA_ "GenSigInactiveValue" SG_ 161 SteerWheelSpd 32767;
BA_ "GenSigInactiveValue" SG_ 161 SteerWheelAng 32767;
BA_ "IsCrcSignal" SG_ 161 Checksum_CSA2 1;
BA_ "VFrameFormat" BO_ 181 14;
BA_ "MsgType" BO_ 181 0;
BA_ "GenMsgCycleTime" BO_ 181 10;
BA_ "GenSigInactiveValue" SG_ 181 RollingCounter_VCU19 15;
BA_ "IsRcSignal" SG_ 181 RollingCounter_VCU19 1;
BA_ "GenSigStartValue" SG_ 181 TotWheelTrq_FA 1200;
BA_ "GenSigStartValue" SG_ 181 TrqAct_RAValid 1;
BA_ "GenSigStartValue" SG_ 181 TrqAct_RA 2048;
BA_ "IsCrcSignal" SG_ 181 Checksum_VCU19 1;
BA_ "GenSigInactiveValue" SG_ 181 RollingCounter_VCU8 15;
BA_ "IsRcSignal" SG_ 181 RollingCounter_VCU8 1;
BA_ "GenSigInactiveValue" SG_ 181 IdleLoadTrq 4095;
BA_ "GenSigInactiveValue" SG_ 181 TrqReqSlowPath 4095;
BA_ "GenSigInactiveValue" SG_ 181 TrqReqFastPath 4095;
BA_ "IsCrcSignal" SG_ 181 Checksum_VCU8 1;
BA_ "GenSigInactiveValue" SG_ 181 RollingCounter_VCU15 15;
BA_ "IsRcSignal" SG_ 181 RollingCounter_VCU15 1;
BA_ "GenSigStartValue" SG_ 181 TotWheelTrq_RA 1200;
BA_ "IsCrcSignal" SG_ 181 Checksum_VCU15 1;
BA_ "GenSigInactiveValue" SG_ 181 RollingCounter_VCU6 15;
BA_ "IsRcSignal" SG_ 181 RollingCounter_VCU6 1;
BA_ "GenSigInactiveValue" SG_ 181 VCU_BrkPedlSts 2;
BA_ "GenSigStartValue" SG_ 181 VCU_AccelPedalPosnValid 1;
BA_ "IsCrcSignal" SG_ 181 Checksum_VCU6 1;
BA_ "GenSigInactiveValue" SG_ 181 RollingCounter_VCU4 15;
BA_ "IsRcSignal" SG_ 181 RollingCounter_VCU4 1;
BA_ "IsCrcSignal" SG_ 181 Checksum_VCU4 1;
BA_ "GenSigInactiveValue" SG_ 181 RollingCounter_VCU1 15;
BA_ "IsRcSignal" SG_ 181 RollingCounter_VCU1 1;
BA_ "GenSigInactiveValue" SG_ 181 VCU_LoUBattSpU 255;
BA_ "GenSigStartValue" SG_ 181 VCU_ACURefFailr 2;
BA_ "IsCrcSignal" SG_ 181 Checksum_VCU1 1;
BA_ "GenSigInactiveValue" SG_ 181 RollingCounter_VCU18 15;
BA_ "IsRcSignal" SG_ 181 RollingCounter_VCU18 1;
BA_ "GenSigStartValue" SG_ 181 HCU_MinEngTrqLimValid 1;
BA_ "GenSigStartValue" SG_ 181 FastRedTrqLimValid 1;
BA_ "GenSigStartValue" SG_ 181 HCU_K0ClutchTrqReq 2000;
BA_ "GenSigStartValue" SG_ 181 HCU_MinTrqLim_TrsmClutch 2000;
BA_ "GenSigStartValue" SG_ 181 HCU_FastRedTrqLim_TrsmClutch 2000;
BA_ "IsCrcSignal" SG_ 181 Checksum_VCU18 1;
BA_ "VFrameFormat" BO_ 189 14;
BA_ "MsgType" BO_ 189 0;
BA_ "GenMsgCycleTime" BO_ 189 20;
BA_ "GenSigInactiveValue" SG_ 189 RollingCounter_ESP12 15;
BA_ "IsRcSignal" SG_ 189 RollingCounter_ESP12 1;
BA_ "GenSigStartValue" SG_ 189 TgtRcprtnTrqReq 8192;
BA_ "IsCrcSignal" SG_ 189 Checksum_ESP12 1;
BA_ "VFrameFormat" BO_ 199 14;
BA_ "MsgType" BO_ 199 0;
BA_ "GenMsgCycleTime" BO_ 199 50;
BA_ "GenSigStartValue" SG_ 199 DRV_RQ_SHFT 8;
BA_ "VFrameFormat" BO_ 216 14;
BA_ "MsgType" BO_ 216 0;
BA_ "GenMsgCycleTime" BO_ 216 10;
BA_ "VFrameFormat" BO_ 240 14;
BA_ "MsgType" BO_ 240 0;
BA_ "GenMsgCycleTime" BO_ 240 10;
BA_ "GenSigInactiveValue" SG_ 240 ACU_ShiftInProgress 3;
BA_ "VFrameFormat" BO_ 669 14;
BA_ "MsgType" BO_ 669 0;
BA_ "GenMsgCycleTime" BO_ 669 100;
BA_ "GenSigStartValue" SG_ 669 InCarTemp 254;
BA_ "GenSigInactiveValue" SG_ 669 InCarTemp 255;
BA_ "VFrameFormat" BO_ 901 14;
BA_ "MsgType" BO_ 901 0;
BA_ "GenMsgCycleTime" BO_ 901 100;
BA_ "GenSigStartValue" SG_ 901 ACAmbTemp 254;
BA_ "GenSigInactiveValue" SG_ 901 ACAmbTemp 255;
BA_ "GenSigStartValue" SG_ 901 ACFrntBlwrSpd 15;
BA_ "VFrameFormat" BO_ 688 14;
BA_ "MsgType" BO_ 688 0;
BA_ "GenMsgCycleTime" BO_ 688 100;
BA_ "VFrameFormat" BO_ 714 14;
BA_ "MsgType" BO_ 714 0;
BA_ "GenMsgCycleTime" BO_ 714 100;
BA_ "GenSigInactiveValue" SG_ 714 RSDS_Driver_LED_Sts 1;
BA_ "VFrameFormat" BO_ 680 14;
BA_ "MsgType" BO_ 680 0;
BA_ "GenMsgCycleTime" BO_ 680 100;
BA_ "GenMsgSendType" BO_ 1308 8;
BA_ "NmAsrMessage" BO_ 1308 1;
BA_ "MsgType" BO_ 1308 0;
BA_ "GenSigSendType" SG_ 1308 PNCInfo_Global 9;
BA_ "GenSigSendType" SG_ 1308 PNCInfo_ADAS 9;
BA_ "GenSigSendType" SG_ 1308 StayAwakeKL15 9;
BA_ "GenSigSendType" SG_ 1308 WakeupReasonKL15 9;
BA_ "GenSigSendType" SG_ 1308 WakeupReasonNM 9;
BA_ "GenSigSendType" SG_ 1308 RepeatMessageState 9;
BA_ "GenMsgSendType" BO_ 1751 1;
BA_ "GenMsgILSupport" BO_ 1751 0;
BA_ "DiagRequest" BO_ 1751 1;
BA_ "MsgType" BO_ 1751 0;
BA_ "GenSigSendType" SG_ 1751 IDC_Phy_Req 9;
BA_ "GenMsgSendType" BO_ 1888 1;
BA_ "GenMsgILSupport" BO_ 1888 0;
BA_ "DiagState" BO_ 1888 1;
BA_ "MsgType" BO_ 1888 0;
BA_ "GenSigSendType" SG_ 1888 DiagFuncReq 9;
BA_ "GenMsgSendType" BO_ 1906 1;
BA_ "GenMsgILSupport" BO_ 1906 0;
BA_ "MsgType" BO_ 1906 0;
BA_ "GenSigSendType" SG_ 1906 FR_Phy_Req 9;
BA_ "GenMsgSendType" BO_ 1759 8;
BA_ "GenMsgILSupport" BO_ 1759 0;
BA_ "DiagResponse" BO_ 1759 1;
BA_ "MsgType" BO_ 1759 0;
BA_ "GenSigSendType" SG_ 1759 IDC_Phy_Resp 9;
BA_ "GenMsgSendType" BO_ 1970 8;
BA_ "GenMsgILSupport" BO_ 1970 0;
BA_ "MsgType" BO_ 1970 0;
BA_ "GenSigSendType" SG_ 1970 FR_Phy_Resp 9;
BA_ "VFrameFormat" BO_ 148 14;
BA_ "MsgType" BO_ 148 0;
BA_ "GenMsgCycleTime" BO_ 148 10;
BA_ "GenSigStartValue" SG_ 148 FMCU_ActualOperMod 1;
BA_ "GenSigStartValue" SG_ 148 FMCU_ActTrq 8190;
BA_ "VFrameFormat" BO_ 210 14;
BA_ "MsgType" BO_ 210 0;
BA_ "GenMsgCycleTime" BO_ 210 10;
BA_ "IsRcSignal" SG_ 210 RollingCounter_FMCU5 1;
BA_ "GenSigStartValue" SG_ 210 FMCU_ActRotSpd 20000;
BA_ "IsCrcSignal" SG_ 210 Checksum_FMCU5 1;
BA_ "VFrameFormat" BO_ 230 14;
BA_ "MsgType" BO_ 230 0;
BA_ "GenMsgCycleTime" BO_ 230 10;
BA_ "GenSigStartValue" SG_ 230 RMCU_ActTrq 8190;
BA_ "VFrameFormat" BO_ 231 14;
BA_ "MsgType" BO_ 231 0;
BA_ "GenMsgCycleTime" BO_ 231 10;
BA_ "GenSigStartValue" SG_ 231 RMCU_ActualOperMod 1;
BA_ "GenSigStartValue" SG_ 231 RMCU_ActRotSpd 20000;
BA_ "VFrameFormat" BO_ 768 14;
BA_ "MsgType" BO_ 768 0;
BA_ "GenMsgCycleTime" BO_ 768 100;
BA_ "GenSigStartValue" SG_ 768 TgtASLVehSpd 255;
BA_ "VFrameFormat" BO_ 188 14;
BA_ "MsgType" BO_ 188 0;
BA_ "GenMsgCycleTime" BO_ 188 10;
BA_ "GenSigStartValue" SG_ 188 RWS_AngAct 4095;
BA_ "VFrameFormat" BO_ 209 14;
BA_ "MsgType" BO_ 209 0;
BA_ "GenMsgCycleTime" BO_ 209 10;
BA_ "IsRcSignal" SG_ 209 RollingCounter_IBooster1 1;
BA_ "IsCrcSignal" SG_ 209 Checksum_IBooster1 1;
BA_ "VFrameFormat" BO_ 241 14;
BA_ "MsgType" BO_ 241 0;
BA_ "GenMsgCycleTime" BO_ 241 10;
BA_ "VFrameFormat" BO_ 255 14;
BA_ "MsgType" BO_ 255 0;
BA_ "GenMsgCycleTime" BO_ 255 10;
BA_ "IsRcSignal" SG_ 255 RollingCounter_Body_Hei 1;
BA_ "IsCrcSignal" SG_ 255 Checksum_Body_Hei 1;
BA_ "VFrameFormat" BO_ 287 14;
BA_ "MsgType" BO_ 287 0;
BA_ "GenMsgCycleTime" BO_ 287 20;
BA_ "VFrameFormat" BO_ 288 14;
BA_ "MsgType" BO_ 288 0;
BA_ "GenMsgCycleTime" BO_ 288 20;
BA_ "IsRcSignal" SG_ 288 RollingCounter_ABS2_Backup 1;
BA_ "GenSigStartValue" SG_ 288 WssRREdgesSumVld_Backup 1;
BA_ "GenSigStartValue" SG_ 288 WssRLEdgesSumVld_Backup 1;
BA_ "IsCrcSignal" SG_ 288 Checksum_ABS2_Backup 1;
BA_ "IsRcSignal" SG_ 288 RollingCounter_IBooster_FD2_5 1;
BA_ "IsCrcSignal" SG_ 288 Checksum_IBooster_FD2_5 1;
BA_ "IsRcSignal" SG_ 288 RollingCounter_ABS3_Backup 1;
BA_ "IsCrcSignal" SG_ 288 Checksum_ABS3_Backup 1;
BA_ "IsRcSignal" SG_ 288 RollingCounter_ABS1_Backup 1;
BA_ "GenSigStartValue" SG_ 288 WssFREdgesSumVld_Backup 1;
BA_ "GenSigStartValue" SG_ 288 WssFLEdgesSumVld_Backup 1;
BA_ "IsCrcSignal" SG_ 288 Checksum_ABS1_Backup 1;
BA_ "VFrameFormat" BO_ 296 14;
BA_ "MsgType" BO_ 296 0;
BA_ "GenMsgCycleTime" BO_ 296 20;
BA_ "VFrameFormat" BO_ 320 14;
BA_ "MsgType" BO_ 320 0;
BA_ "GenMsgCycleTime" BO_ 320 20;
BA_ "IsRcSignal" SG_ 320 RollingCounter_RWA_FD2_2 1;
BA_ "IsCrcSignal" SG_ 320 Checksum_RWA_FD2_2 1;
BA_ "VFrameFormat" BO_ 326 14;
BA_ "MsgType" BO_ 326 0;
BA_ "GenMsgCycleTime" BO_ 326 20;
BA_ "IsRcSignal" SG_ 326 RollingCounter_VDC1 1;
BA_ "IsCrcSignal" SG_ 326 Checksum_VDC1 1;
BA_ "VFrameFormat" BO_ 332 14;
BA_ "MsgType" BO_ 332 0;
BA_ "GenMsgCycleTime" BO_ 332 20;
BA_ "IsRcSignal" SG_ 332 RollingCounter_RWA_FD1_2 1;
BA_ "IsCrcSignal" SG_ 332 Checksum_RWA_FD1_2 1;
BA_ "VFrameFormat" BO_ 346 14;
BA_ "MsgType" BO_ 346 0;
BA_ "GenMsgCycleTime" BO_ 346 20;
BA_ "IsRcSignal" SG_ 346 RollingCounter_LBM2 1;
BA_ "IsCrcSignal" SG_ 346 Checksum_LBM2 1;
BA_ "VFrameFormat" BO_ 356 14;
BA_ "MsgType" BO_ 356 0;
BA_ "GenMsgCycleTime" BO_ 356 20;
BA_ "IsRcSignal" SG_ 356 RollingCounter_EPS_FD2_3 1;
BA_ "IsCrcSignal" SG_ 356 Checksum_EPS_FD2_3 1;
BA_ "IsRcSignal" SG_ 356 RollingCounter_EPS_FD2_2 1;
BA_ "GenSigStartValue" SG_ 356 EPS_DrvInpTrqVal_HiRes_Backup 2047;
BA_ "GenSigStartValue" SG_ 356 EPS_LKATorqOvrlDlvd_Backup 1500;
BA_ "IsCrcSignal" SG_ 356 Checksum_EPS_FD2_2 1;
BA_ "IsRcSignal" SG_ 356 RollingCounter_EPS_FD2_1 1;
BA_ "GenSigStartValue" SG_ 356 EPS_TrqSnsrSts_Backup 1;
BA_ "IsCrcSignal" SG_ 356 Checksum_EPS_FD2_1 1;
BA_ "VFrameFormat" BO_ 536 14;
BA_ "MsgType" BO_ 536 0;
BA_ "GenMsgCycleTime" BO_ 536 50;
BA_ "VFrameFormat" BO_ 597 14;
BA_ "MsgType" BO_ 597 0;
BA_ "GenMsgCycleTime" BO_ 597 50;
BA_ "VFrameFormat" BO_ 647 14;
BA_ "MsgType" BO_ 647 0;
BA_ "GenMsgCycleTime" BO_ 647 100;
BA_ "IsRcSignal" SG_ 647 RollingCounter_HC1 1;
BA_ "IsCrcSignal" SG_ 647 Checksum_HC1 1;
BA_ "VFrameFormat" BO_ 748 14;
BA_ "MsgType" BO_ 748 0;
BA_ "GenMsgCycleTime" BO_ 748 100;
BA_ "GenMsgSendType" BO_ 770 11;
BA_ "VFrameFormat" BO_ 770 14;
BA_ "MsgType" BO_ 770 0;
BA_ "GenMsgCycleTime" BO_ 770 200;
BA_ "VFrameFormat" BO_ 772 14;
BA_ "MsgType" BO_ 772 0;
BA_ "GenMsgCycleTime" BO_ 772 200;
BA_ "VFrameFormat" BO_ 776 14;
BA_ "MsgType" BO_ 776 0;
BA_ "GenMsgCycleTime" BO_ 776 200;
BA_ "VFrameFormat" BO_ 781 14;
BA_ "MsgType" BO_ 781 0;
BA_ "GenMsgCycleTime" BO_ 781 200;
BA_ "VFrameFormat" BO_ 816 14;
BA_ "MsgType" BO_ 816 0;
BA_ "GenMsgCycleTime" BO_ 816 200;
BA_ "VFrameFormat" BO_ 818 14;
BA_ "MsgType" BO_ 818 0;
BA_ "GenMsgCycleTime" BO_ 818 200;
BA_ "VFrameFormat" BO_ 819 14;
BA_ "MsgType" BO_ 819 0;
BA_ "GenMsgCycleTime" BO_ 819 200;
BA_ "VFrameFormat" BO_ 860 14;
BA_ "MsgType" BO_ 860 0;
BA_ "GenMsgCycleTime" BO_ 860 500;
BA_ "VFrameFormat" BO_ 879 14;
BA_ "MsgType" BO_ 879 0;
BA_ "GenMsgCycleTime" BO_ 879 500;
VAL_ 579 LgtFolwDistanceSet 0 "Initial_value" 1 "Tight_gap" 2 "Proper_gap" 3 "Large_gap" ;
VAL_ 579 IntellgntAsscLmpEnaReq 0 "Initial_value" 1 "Off" 2 "Full_bright" 3 "Olny_Parking_on" ;
VAL_ 579 UsrExperiProgAuthorSts 0 "Initial_Value" 1 "Unauthorize" 2 "Authorized" ;
VAL_ 579 SidePrkgReq 0 "Initial_value" 1 "OFF" 2 "ON" 3 "Resvered" ;
VAL_ 579 NOAFuncSet 0 "Initial_value" 1 "OFF" 2 "ON" ;
VAL_ 579 OvertakingLightModReq 0 "Initial_value" 1 "OFF" 2 "Auto_beam" 3 "Auto_beam_and_whistle" ;
VAL_ 579 IDsceneModReq 0 "Initial_value" 1 "Commuting_mode" 2 "Comfort_mode" 3 "Distract" ;
VAL_ 579 PassETCEnaReq 0 "Initial_value" 1 "No_request" 2 "Request" ;
VAL_ 579 DeviateSpdPreReq 0 "Valid_values" 63 "Invalid" ;
VAL_ 579 StartReminderEnaReq 0 "Initial_value" 1 "OFF" 2 "ON" ;
VAL_ 579 DeviateSpdFixdValReq 0 "Valid_values" 63 "Invalid" ;
VAL_ 579 HandsoffModReq 0 "Initial_value" 1 "HandsOff" 2 "Attention_And_HandsOff" ;
VAL_ 579 HWA_FaststSwtReq 0 "Initial_value" 1 "OFF" 2 "ON" 3 "Resvered" ;
VAL_ 579 DeviateSpdModSwtReq 0 "Initial_value" 1 "Fixed_value" 2 "Percentage" 3 "Resvered" ;
VAL_ 579 MapStatus 0 "Unauthorize" 1 "Authorize" 2 "Reserved" ;
VAL_ 579 ADAS_gpsAuthSys 0 "Unauthorize" 1 "Authorize" ;
VAL_ 579 PrivacySts 0 "Unauthorize" 1 "Authorize" ;
VAL_ 579 UNP_SwtReq 0 "OFF" 1 "ON" ;
VAL_ 579 NOH_Act_Req 0 "deactivate" 1 "activate" ;
VAL_ 579 NOH_Swt_Req 0 "OFF" 1 "ON" ;
VAL_ 579 AVM_3DAngleReq 0 "No_request" 1 "Valid_values" 511 "Invalid" ;
VAL_ 579 PrkAreaSts 0 "No_Parking_area" 1 "Parking_area" 2 "Unknown" 3 "Reserved" ;
VAL_ 579 BeginnerModSts 0 "Initial_value" 1 "OFF" 2 "ON" ;
VAL_ 579 OneClickAutDrvgSts 0 "Initial_Value" 1 "Choose" ;
VAL_ 579 HandsoffTimSet 0 "Initial" 1 "Handsoff_time_is_normal" 2 "Handsoff_time_is_long" 3 "Reserved" ;
VAL_ 579 HUT_OD_WorkSts 0 "OFF" 1 "FOD Active" 2 "ROD Active" 3 "Reserved" ;
VAL_ 579 TraLightSwtReq 0 "OFF" 1 "ON" ;
VAL_ 580 InrMalfct 0 "No_Error" 1 "Error" ;
VAL_ 581 RollingCounter_ABM2 0 "Valid value" 15 "Invalid value" ;
VAL_ 581 VehDynYawRateVld 0 "Invalid" 1 "Valid" ;
VAL_ 581 VehLatAccelVld 0 "Invalid" 1 "Valid" ;
VAL_ 581 VehLgtAccelVld 0 "Invalid" 1 "Valid" ;
VAL_ 581 VehYawRate 0 "Valid Value" 17442 "Reserved" ;
VAL_ 581 VehLatAccel 0 "Valid Value" 44067 "Reserved" ;
VAL_ 581 VehLgtAccel 0 "Valid Value" 44067 "Reserved" ;
VAL_ 581 Checksum_ABM2 0 "Valid values" ;
VAL_ 589 DrvBehvSts 0 "No action" 1 "Smoking" 2 "on the phone" 3 "Drinking" 4 "Reserved" 7 "Invalid" ;
VAL_ 589 DMSSts 0 "Blindness" 1 "Error" 2 "Active" 3 "Not active" 4 "Reserved" 7 "Invalid" ;
VAL_ 589 HeadDetn 0 "No" 1 "Yes" ;
VAL_ 589 DrowsnsLvl_ACC 0 "No Drowsiness" 1 "Low level Drowsiness" 2 "Middle level Drowsiness" 3 "Hi level Drowsiness" 4 "Driver_Drowsiness_Unresponsive" 7 "Invalid" ;
VAL_ 589 DistrctnLvl_ACC 0 "No distraction" 1 "Low level distraction" 2 "Middle level distraction" 3 "Hi level distraction" 4 "Driver_Distraction_Unresponsive" 7 "Invalid" ;
VAL_ 589 ExprsnSts 0 "No_expression" 1 "Smile" 2 "Angry" 3 "Surprise" 4 "Sad" 5 "Calm" 6 "Reserved" 7 "Invalid" ;
VAL_ 589 DrvGazSts 0 "Initial_value" 1 "Gaze_towards_forward" 2 "Gaze_away" 3 "Gaze_towards_left" 4 "Gaze_towards_right" 5 "Gaze_blocked" ;
VAL_ 596 LeSideDoRollSts 0 "No_Rolling" 1 "Up1" 2 "Up2" 3 "Up3" 4 "Up4" 5 "Up5" 6 "Up6" 7 "Up7" 8 "Reserved" ;
VAL_ 596 LeSideUpRollSts 0 "No_Rolling" 1 "Up1" 2 "Up2" 3 "Up3" 4 "Up4" 5 "Up5" 6 "Up6" 7 "Up7" 8 "Reserved" ;
VAL_ 604 RollingCounter_BLE1 0 "Valid value" 15 "Invalid value" ;
VAL_ 604 PrkOutModSel_Rmt1 0 "No_select" 1 "Vertical_front_left_berthing" 2 "Vertical_front_right_berthing" 3 "Vertical_rear_left_berthing" 4 "Vertical_rear_right_berthing" 5 "Line_Summon" ;
VAL_ 604 MplSmtPhoneLocn 0 "Initial_value" 1 "Smartphone_in_Car" 2 "Smartphone_in_Driver_Door_Passive_Entry_Exit_range" 3 "Smartphone_in_Passenger_Door_Passive_Entry_Exit_range" 4 "Smartphone_in_Driver_Door_Auto_Lock_range" 5 "Smartphone_in_Passenger_Door_Auto_Lock_range" 6 "Smartphone_in_Trunk_Passive_Entry_Exit_range" 7 "Smartphone_in_Passive_Entry_Exit_range" 8 "Smartphone_in_Trunk_range" 9 "Smartphone_in_Welcome_Area_range" ;
VAL_ 604 ParkChokeReq_Rmt 0 "No Request" 1 "Request" ;
VAL_ 604 PrkOutTypeReq_Rmt 0 "No select" 1 "Parallel park out" 2 "Vertical park out" 3 "Intelligent Summon" ;
VAL_ 604 PrkOutVehStrtReq_Rmt_Valid 0 "Invalid" 1 "Valid" ;
VAL_ 604 PrkgSyncStrtReq_Rmt 0 "No request" 1 "Request" ;
VAL_ 604 PrkOutModSel_Rmt 0 "No select" 1 "Front vertical head park out" 2 "Rear vertical tail park out" 3 "Left parallel left park out" 4 "Right parallel right park out" 5 "Summon path one park out" 6 "Summon path two park out" 7 "Reserved" ;
VAL_ 604 ParkAbortReq_Rmt 0 "No request" 1 "Request" ;
VAL_ 604 PrkOutVehStrtReq_Rmt 0 "No request" 1 "Request" ;
VAL_ 604 PrkgslidReq_Rmt 0 "User not sliding circle" 1 "User sliding circle" ;
VAL_ 604 SmtPhoneLocn 0 "Initial_value" 1 "Smartphone_in_Car" 2 "Smartphone_in_Passive_Entry_Exit_range" ;
VAL_ 604 BLESecuritySts 0 "Initial value" 1 "Not in Security certification status" 2 "In security certification status" 3 "Reserved" ;
VAL_ 604 BLEConnSts 0 "Initial value" 1 "Not connection" 2 "Connection" 3 "Reserved" ;
VAL_ 604 Checksum_BLE1 0 "Valid value" ;
VAL_ 623 RollingCounter_HUT32 0 "Valid value" 15 "Invalid value" ;
VAL_ 623 NavDecSwtReq 0 "OFF" 1 "ON" ;
VAL_ 623 ScrnOpSts 0 "Release" 1 "Pressed" 2 "Hold" 3 "Reserved" ;
VAL_ 623 Ylevel 0 "Valid_value" 4095 "Invalid" ;
VAL_ 623 Xlevel 0 "Valid_value" 4095 "Invalid" ;
VAL_ 623 ContnPrkgReqValid 0 "valid" 1 "invalid" ;
VAL_ 623 DetVideoLost 0 "Nomal" 1 "Video lost" ;
VAL_ 623 PrkgCtrlModReqValid 0 "valid" 1 "invalid" ;
VAL_ 623 PrkgCtrlModReq 0 "No action" 1 "Parking in car" 2 "Remote parking" 3 "Remote searching slot" ;
VAL_ 623 ContnPrkgReq 0 "no select" 1 "select continue parking" 2 "cancle parking" 3 "invalid" ;
VAL_ 623 Checksum_HUT32 0 "Valid value" ;
VAL_ 627 TrailerSts 0 "Trailer off" 1 "Trailer on" ;
VAL_ 629 RollingCounter_Trailer2 15 "Invalid_value" ;
VAL_ 629 TrailerStatusVld 0 "InValid" 1 "Valid" ;
VAL_ 629 TrailerStatus 0 "Trailer_off" 1 "Trailer_on" ;
VAL_ 639 IP_Err 0 "No error" 1 "Error" ;
VAL_ 639 IP_VehSpdUnit 0 "kph" 1 "mph" ;
VAL_ 639 IP_VehTotDistanceValid 0 "Invalid" 1 "Valid" ;
VAL_ 639 IP_ACCErr 0 "No error" 1 "Error" ;
VAL_ 639 IP_VehTotDistance 0 "0-9999999-km" 10000000 "Reserved" 16777215 "Invalid" ;
VAL_ 659 IP_VelSpdDisp_Mile 0 "Valid_values" 255 "Invalid" ;
VAL_ 659 IP_VehSpdDisp 0 "Valid_values" 511 "Invalid" ;
VAL_ 670 BMS_CC2LineSts 0 "Not_Connect" 1 "Connect" 2 "Error" 3 "Discharge_connected" ;
VAL_ 707 ADAS_Posn_Rehead 0 "In_path_direction" 1 "_1point417_degrees_right" 2 "Valid_values" 126 "_178point583_degrees_right" 127 "Opposite_direction" 128 "_178point583_degrees_left_181point417_degrees_right" 253 "_1point417_degrees_left_358point583_degrees_right" 254 "Unknown" 255 "Invalid" ;
VAL_ 707 ADAS_Posn_Spd 0 "Equal_or_less_than_negative12point8" 1 "Valid_values" 64 "Standing_still" 65 "Valid_values" 510 "Equal_or_more_than_positive_89_point_2" 511 "Invalid_data" ;
VAL_ 707 ADAS_Posn_CurLane 0 "Unknown" 1 "Emergency lane" 2 "Single-lane road" 3 "Left-most lane" 4 "Right-most lane" 5 "One of middle lanes on road with three or more lanes" 6 "Reserved" 7 "Invalid data" ;
VAL_ 707 ADAS_Posn_PosConfdc 0 "Valid_values" 7 "Invalid_value" ;
VAL_ 707 ADAS_Posn_Age 0 "0~2545ms" 510 ">2545ms" 511 "Invalid data" ;
VAL_ 707 ADAS_Posn_PosProbb 0 "Unknown" 31 "Invalid" ;
VAL_ 707 ADAS_Posn_Idx 0 "Valid value" ;
VAL_ 707 ADAS_Posn_Pathldx 0 "Valid value" ;
VAL_ 707 ADAS_Posn_CycCnt 0 "Valid value" ;
VAL_ 707 ADAS_Posn_Offset 0 "Valid value" 8191 "Invalid data" ;
VAL_ 707 ADAS_Posn_MsgTye 0 "System Specific" 1 "Position" 2 "Segment" 3 "Stub" 4 "Profile Short" 5 "Profile Long" 6 "Meta-data" 7 "Reserved" ;
VAL_ 707 NavSpdLimType 0 "Unknown" 1 "Traffic sign" 2 "Electronic eye" 3 "Rode Default" ;
VAL_ 707 NavigationRoadType 0 "Unknown" 1 "Expressway" 2 "City expressway" 3 "National rode" 4 "Provincial rode" 5 "County rode" 6 "Township road" 7 "ramp" 8 "Tunnel" 9 "Side rode" 10 "Channel" 11 "Major road" 12 "Ordinary road" 13 "Village road" 14 "Reserved" ;
VAL_ 707 ALC_SwtReq 0 "OFF" 1 "ON" ;
VAL_ 707 AESSwtReq 0 "OFF" 1 "ON" ;
VAL_ 707 AEB_JASwtReq 0 "OFF" 1 "ON" ;
VAL_ 707 FCTABrkSwtReq 0 "OFF" 1 "ON" ;
VAL_ 707 FCTASwtReq 0 "OFF" 1 "ON" ;
VAL_ 707 HWA_SnvtySet 0 "Normal" 1 "High_Sensitivity" 2 "Low_Sensitivity" 3 "Max_Sensitivity" ;
VAL_ 707 NavTSRTrafSign 0 "None" 1 "Snow" 2 "Fog" 3 "ThunderStorm" 4 "Rain" 5 "FWay" 6 "EFWay" 7 "Straight" 8 "FrontageLeft" 9 "TurnLeftRight" 10 "FrontageRight" 11 "Right" 12 "TurnRight" 13 "Left" 14 "TurnLeft" 15 "RelieveNoOvertake" 16 "NoOvertake" 17 "StopGiveWay" 18 "GiveWay" 19 "NoPass" 20 "NoEntry" 21 "NoCar" 22 "NoTruck" 23 "NoBus" 24 "NoTurnaround" 25 "NoStraightLeftTurn" 26 "NoStraightRightTurn" 27 "NoLeftRightTurn" 28 "NoLeftTurn" 29 "NoRightTurn" 30 "NoStraight" 31 "WarnKids" 32 "WarnPed" 33 "WarnBike" 34 "WarnWorks" 35 "WarnWildanimal" 36 "WarnCattle" 37 "AccidentProneSection" 38 "Town" 39 "Slow" 40 "SharpTurnR" 41 "SharpTurnL" 42 "ReverseCurveL" 43 "ReverseCurveR" 44 "ContinuousBend" 45 "Crossroads" 46 "ConfluenceR" 47 "ConfluenceL" 48 "Reserved" 255 "Invalid" ;
VAL_ 707 HWA_SwtReq 0 "OFF" 1 "ON" ;
VAL_ 707 NavSpdLimSignSts 0 "Unknow" 1 "Exist SPL sign" 2 "Exist Traffic sign" 3 "Exist SPL and Traffic sign" 4 "None" 5 "Plural" 6 "Reserved" ;
VAL_ 707 NavCtryType 0 "Reserved" 156 "China" 157 "Reserved" ;
VAL_ 707 NavSpdLimUnit_HUT 0 "Unknown" 1 "KMH" 2 "MPH" 3 "Reserved" ;
VAL_ 707 NavSpdLimValue 0 "No Display" 1 "SPL 5" 2 "SPL 10" 3 "SPL 15" 4 "SPL 20" 5 "SPL 25" 6 "SPL 30" 7 "SPL 35" 8 "SPL 40" 9 "SPL 45" 10 "SPL 50" 11 "SPL 55" 12 "SPL 60" 13 "SPL 65" 14 "SPL 70" 15 "SPL 75" 16 "SPL 80" 17 "SPL 85" 18 "SPL 90" 19 "SPL 95" 20 "SPL 100" 21 "SPL 105" 22 "SPL 110" 23 "SPL 115" 24 "SPL 120" 25 "SPL 125" 26 "SPL 130" 27 "SPL 135" 28 "SPL 140" 29 "SPL 145" 30 "SPL 150" 31 "Reserved" 63 "Invalid" ;
VAL_ 707 NavVehToTrafEyeDist 0 "Valid value" ;
VAL_ 707 MOD_SwtReq 0 "Initial_value" 1 "OFF" 2 "ON" 3 "Resvered" ;
VAL_ 707 TSR_SnvtySet 0 "valid" 31 "Invalid" ;
VAL_ 707 ISLSwtReq 0 "OFF" 1 "ON" ;
VAL_ 707 DOWSwtReq 0 "OFF" 1 "ON" ;
VAL_ 707 AEB_PedSwtReq 0 "OFF" 1 "ON" ;
VAL_ 707 LSSSwtReq 0 "OFF" 1 "ON" ;
VAL_ 707 IntelligentEvaSwtReq 0 "OFF" 1 "ON" ;
VAL_ 707 LSSWarnFormSwtReq 0 "Voice" 1 "Haptic" 2 "Voice+Haptic" 3 "Reserved" ;
VAL_ 707 TSRWarnSwtReq 0 "OFF" 1 "ON" ;
VAL_ 707 TSRSwtReq 0 "OFF" 1 "ON" ;
VAL_ 707 LDWSwtReq 0 "OFF" 1 "ON" ;
VAL_ 707 ESS_VehSwtReq 0 "OFF" 1 "ON" ;
VAL_ 707 ESS_PedSwtReq 0 "OFF" 1 "ON" ;
VAL_ 707 ELKSwtReq 0 "OFF" 1 "ON" ;
VAL_ 707 LCKSwtReq 0 "OFF" 1 "ON" ;
VAL_ 707 LKASwtReq 0 "OFF" 1 "ON" ;
VAL_ 707 AEB_VehSwtReq 0 "OFF" 1 "ON" ;
VAL_ 707 FCW_SnvtySet 0 "Normal" 1 "High sensitivity" 2 "Low sensitivity" 3 "Reserved" ;
VAL_ 707 RCWSwtReq 0 "OFF" 1 "ON" ;
VAL_ 707 RCTABrkSwtReq 0 "OFF" 1 "ON" ;
VAL_ 707 RCTASwtReq 0 "OFF" 1 "ON" ;
VAL_ 707 LCASwtReq 0 "OFF" 1 "ON" ;
VAL_ 707 IFC_SnvtySet 0 "Normal" 1 "High sensitivity" 2 "Low sensitivity" 3 "Reserved" ;
VAL_ 707 NOH_Btn_Sts 0 "Not_apply" 1 "Apply" ;
VAL_ 707 DR_CalibratedSts 0 "Not_Calibrated" 1 "Calibrated" ;
VAL_ 707 IntellgntcurveReq 0 "OFF" 1 "ON" ;
VAL_ 717 PassWinPosnSts_Perc 0 "Unknown" 1 "Close" 2 "Open" 3 "5%Open" 4 "10%Open" 5 "15%Open" 6 "20%Open" 7 "25%Open" 8 "30%Open" 9 "35%Open" 10 "40%Open" 11 "45%Open" 12 "50%Open" 13 "55%Open" 14 "60%Open" 15 "65%Open" 16 "70%Open" 17 "75%Open" 18 "80%Open" 19 "85%Open" 20 "90%Open" 21 "95%Open" 22 "Reserved" ;
VAL_ 717 RSDS_Pass_LED_Sts 0 "No error" 1 "error" ;
VAL_ 725 PassRearDoorWinPosnSts_Perc 0 "Unknown" 1 "Close" 2 "Open" 3 "5%Open" 4 "10%Open" 5 "15%Open" 6 "20%Open" 7 "25%Open" 8 "30%Open" 9 "35%Open" 10 "40%Open" 11 "45%Open" 12 "50%Open" 13 "55%Open" 14 "60%Open" 15 "65%Open" 16 "70%Open" 17 "75%Open" 18 "80%Open" 19 "85%Open" 20 "90%Open" 21 "95%Open" 22 "Reserved" ;
VAL_ 726 WtrAirCoolrPmp_FltSts 0 "Normal" 1 "Fail" ;
VAL_ 726 RollingCounter_VCU13 0 "Valid_Value" 15 "Invalid_Value" ;
VAL_ 726 VCU_LTRadrOutlWtrTemp 0 "Valid_Value" 171 "Reserved" 254 "Init" 255 "Invalid_Value" ;
VAL_ 726 VCU_WtrPmpOpenRateCtrl 0 "Valid_Value" 101 "Reserved" ;
VAL_ 726 Checksum_VCU13 0 "Valid_Values" ;
VAL_ 726 VCU_VCUSts 0 "SleepState" 1 "Standby" 2 "During Ready" 3 "PowerUp4Ready" 4 "HVPowerUpProcess" 5 "Powr Up For Charge" 6 "Charging" 7 "Charge Power down" 8 "HV Powerdown" 9 "During LV Powerdown" 10 "Powerdown finish" 11 "Prepare Sleep" 12 "Powerup4LVcharging" 13 "Default" 14 "Heat only" 15 "End heating" 16 "Cool" 17 "Reserved" ;
VAL_ 726 VCU_ResrDrvRng 0 "Valid_Values" 1000 "Reserved" ;
VAL_ 726 RollingCounter_VCU3 0 "Valid_Value" 15 "Invalid_Value" ;
VAL_ 726 ChrgnSts 0 "Default" 1 "Charging" 2 "Delaying" 3 "Charge_complete" 4 "Charge_stopped" 5 "Charge_Initialize" 6 "Charging_Heating" 7 "Fault" ;
VAL_ 726 VCU_SysFltLmp 0 "No_Fault" 1 "Yellow_lamp_ON" 2 "Red_lamp_ON" ;
VAL_ 726 EnrgFlowInd 0 "Mode_1" 1 "Mode_2" 2 "Mode_3" 3 "Mode_4" 4 "Mode_5" 5 "Mode_6" 6 "Mode_7" 7 "Mode_8" 8 "Mode_9" 9 "Mode_10" 10 "Mode_11" 11 "Mode_12" 12 "Mode_13" 13 "Mode_14" 14 "Mode_15" 15 "Mode_16" 16 "Mode_17" 17 "Mode_18" 18 "Mode_19" 19 "Mode_20" 20 "Mode_21" 21 "Mode_22" 22 "Mode_23" 23 "Mode_24" 24 "Mode_25" 25 "Mode_26" 26 "Mode_27" 27 "Mode_28" 28 "Mode_29" 29 "Mode_30" 30 "Mode_31" 31 "Mode_32" 32 "Mode_33" 33 "Mode_34" 34 "Mode_35" 35 "Mode_36" 36 "Mode_37" 37 "Mode_38" 38 "Mode_39" ;
VAL_ 726 VCU_TMWtrPmpSts 0 "No_fault" 1 "Fault" ;
VAL_ 726 VCU_PwrLo 0 "Normal" 1 "Power_low" ;
VAL_ 726 VCU_EPSEnable 0 "Disable" 1 "Enable" ;
VAL_ 726 VCU_RdyLEDSts 0 "OFF" 1 "ON" 2 "Flashing" 3 "Reserved" ;
VAL_ 726 VCU_VehBrkLiActv 0 "Inactive" 1 "Active" ;
VAL_ 726 VCU_OPDSts 0 "Inactive" 1 "Active" 2 "Abnormal_quit" 3 "Cannot_active" 4 "Have_no_OPD_function" ;
VAL_ 726 VCU_HeatgAimT 0 "Valid_values" ;
VAL_ 726 Checksum_VCU3 0 "Valid_Values" ;
VAL_ 728 ADAS_Stub_NumOfLaneDrvDir 0 "One-direction road driven in wrong direction" 1 "Verbatim values" 6 "6 or more lanes" 7 "invalid" ;
VAL_ 728 ADAS_Stub_NumOfLaneOppDir 0 "one-direction road" 1 "one lane only" 2 "indicates 2 or more lanes" 3 "invalid" ;
VAL_ 728 ADAS_Stub_RtOfWay 0 "Drvg towards this stub has priority over all conflicting vehicle movements" 1 "Drvg towards this stub might require yielding to conflicting vehicle movements" 2 "Unknown" 3 "Invalid" ;
VAL_ 728 ADAS_Stub_LastStub 0 "False" 1 "True" ;
VAL_ 728 ADAS_Stub_TurnAngl 0 "In_path_direction" 1 "_1point417_degrees_right" 2 "Valid_values" 126 "_178point583_degrees_right" 127 "Opposite_direction" 128 "_178point583__degrees_left_181.417_degrees_right" 129 "Valid_values" 253 "_1point417_degrees_left_358.583_degrees_right" 254 "Unknown" 255 "Invalid" ;
VAL_ 728 ADAS_Stub_FormOfWay 0 "Unkown" 1 "Freeway or Controlled Access road that is not a slip road/ramp" 2 "Multiple Carriageway or Multiply Digitized Road" 3 "Single Carriageway (default)" 4 "Roundabout Circle" 5 "Traffic Square/Special Traffic Figure" 6 "Reserved" 8 "Parallel Road (as special type of a slip road/ramp)" 9 "Slip Road/Ramp on a Freeway or Controlled Access road" 10 "Slip Road/Ramp (not on a Freeway or Controlled Access road)" 11 "Service Road or Frontage Road" 12 "Entrance to or exit of a Car Park" 13 "Entrance to or exit to Service" 14 "Pedestrian Zone" 15 "Unknow" ;
VAL_ 728 ADAS_Stub_CmplxInsct 0 "New path is not part of complex intersection" 1 "New path is part of a complex intersection" 2 "Unknown" 3 "invalid" ;
VAL_ 728 ADAS_Stub_PartOfCalcRoute 0 "New path from this point on is not part of Calculated Route" 1 "New path from this point on is part of Calculated Route" 2 "Unknown" 3 "invalid" ;
VAL_ 728 ADAS_Stub_FuncRoadClass 0 "Unkown" 1 "Expressway" 2 "City expressway" 3 "National road" 4 "Provincial rode or County road" 5 "City or Village road" 6 "Other road" 7 "Invalid" ;
VAL_ 728 ADAS_Stub_RelProbb 0 "unknown" 1 "Valid_values" 31 "Invalid" ;
VAL_ 728 ADAS_Stub_Update 0 "False" 1 "True" ;
VAL_ 728 ADAS_Stub_Retr 0 "False" 1 "True" ;
VAL_ 728 ADAS_Stub_StubPathIdx 0 "Valid value" ;
VAL_ 728 ADAS_Stub_PathIdx 0 "Valid value" ;
VAL_ 728 ADAS_Stub_CycCnt 0 "Valid_value1" 1 "Valid_value2" 2 "Valid_value3" 3 "Valid_value4" ;
VAL_ 728 ADAS_Stub_Offset 0 "Valid data" 8191 "Invalid data" ;
VAL_ 728 ADAS_Stub_MsgTyp 0 "System Specific" 1 "Position" 2 "Segment" 3 "Stub" 4 "Profile Short" 5 "Profile Long" 6 "Meta-data" 7 "Reserved" ;
VAL_ 730 ADAS_Seg_NumOfLaneDrvDir 0 "One_direction_road_driven_in_wrong_direction" 1 "Verbatim_values1" 2 "Verbatim_values2" 3 "Verbatim_values3" 4 "Verbatim_values4" 5 "Verbatim_values5" 6 "Six_or_more_lanes" 7 "Invalid" ;
VAL_ 730 ADAS_Seg_NumOfLaneOppDir 0 "One-direction road" 1 "One lane only" 2 "Indicates 2 or more lanes" 3 "Invalid" ;
VAL_ 730 ADAS_Seg_DivideRoad 0 "Segment is not part of a divided road/dual carriageway" 1 "Segment is part of a divided road/dual carriageway" 2 "Unknown" 3 "N/A" ;
VAL_ 730 ADAS_Seg_EffSpdLmtTyp 0 "Implicit (for instance, default speed limit in the cities)" 1 "Explicit ?C on traffic sign" 2 "Explicit ?C by night" 3 "Explicit ?C by day" 4 "Explicit ?C time of day" 5 "Explicit ?C Electronic eye" 6 "Explicit ?C snow" 7 "Unknown" ;
VAL_ 730 ADAS_Seg_EffSpdLmt 0 "Unknown_including_variable_value_sign_controlled" 1 "value1" 2 "value2" 3 "value3" 4 "value4" 5 "value5" 6 "value6" 7 "value7" 8 "value8" 9 "value9" 10 "value10" 11 "value11" 12 "value12" 13 "value13" 14 "value14" 15 "value15" 16 "value16" 17 "value17" 18 "value18" 19 "value19" 20 "value20" 21 "value21" 22 "value22" 23 "value23" 24 "value24" 25 "value25" 26 "value26" 27 "value27" 28 "value28" 29 "Less_Than_Unlimited" 30 "Unlimited" ;
VAL_ 730 ADAS_Seg_FormOfWay 0 "Unkown" 1 "Freeway or Controlled Access road that is not a slip road/ramp" 2 "Multiple Carriageway or Multiply Digitized Road" 3 "Single Carriageway (default)" 4 "Roundabout Circle" 5 "Traffic Square/Special Traffic Figure" 6 "Reserved" 8 "Parallel Road (as special type of a slip road/ramp)" 9 "Slip Road/Ramp on a Freeway or Controlled Access road" 10 "Slip Road/Ramp (not on a Freeway or Controlled Access road)" 11 "Service Road or Frontage Road" 12 "Entrance to or exit of a Car Park" 13 "Entrance to or exit to Service" 14 "Pedestrian Zone" 15 "Unknow" ;
VAL_ 730 ADAS_Seg_CmplxInsct 0 "Segment is not part of complex intersection" 1 "Segment is part of a complex intersection" 2 "Unknown" 3 "Invalid" ;
VAL_ 730 ADAS_Seg_PartOfCalcRoute 0 "Segment is not part of Calculated Route" 1 "Segment is part of Calculated Route" 2 "Unknown" 3 "Invalid" ;
VAL_ 730 ADAS_Seg_FuncRoadClass 0 "Unkown" 1 "Expressway" 2 "City expressway" 3 "National road" 4 "Provincial rode or County road" 5 "City or Village road" 6 "Other road" 7 "Invalid" ;
VAL_ 730 ADAS_Seg_RelProbb 0 "Unknown" 1 "Valid_values" 31 "Invalid" ;
VAL_ 730 ADAS_Seg_Update 0 "False" 1 "True" ;
VAL_ 730 ADAS_Seg_Retr 0 "False" 1 "True" ;
VAL_ 730 ADAS_Seg_BuildUpArea 0 "Segment is not part of a built-up area" 1 "Segment is part of a built-up area" 2 "Unknown" 3 "Invalid" ;
VAL_ 730 ADAS_Seg_Brdg 0 "Segment is not part of a bridge" 1 "Segment is part of a bridge" 2 "Unknown" 3 "Invalid" ;
VAL_ 730 ADAS_Seg_Tunnel 0 "Segment is not part of a tunnel" 1 "Segment is part of a tunnel" 2 "Unknown" 3 "Invalid" ;
VAL_ 730 ADAS_Seg_PathIdx 0 "Valid value" ;
VAL_ 730 ADAS_Seg_CycCnt 0 "Valid_value_1" 1 "Valid_value_2" 2 "Valid_value_3" 3 "Valid_value_4" ;
VAL_ 730 ADAS_Seg_Offset 0 "Valid data" 8191 "Invalid data" ;
VAL_ 730 ADAS_Seg_MsgTyp 0 "System Specific" 1 "Position" 2 "Segment" 3 "Stub" 4 "Profile Short" 5 "Profile Long" 6 "Meta-data" 7 "Reserved" ;
VAL_ 733 ADAS_ProfShort_Value1 0 "Valid data" 1023 "Unknow" ;
VAL_ 733 ADAS_ProfShort_Value0 0 "Valid data" 1023 "Unknow" ;
VAL_ 733 ADAS_ProfShort_Dist1 0 "No_other_profile_values_are_defined_in_this_message" 1 "Valid_values" 1023 "Invalid" ;
VAL_ 733 ADAS_ProfShort_AccurClass 0 "Hiest accuracy" 1 "Medium accuracy" 2 "Lowest accuracy" 3 "Unknown" ;
VAL_ 733 ADAS_ProfShort_Update 0 "false" 1 "true" ;
VAL_ 733 ADAS_ProfShort_Retr 0 "false" 1 "true" ;
VAL_ 733 ADAS_ProfShort_CtrlPoint 0 "false" 1 "true" ;
VAL_ 733 ADAS_ProfShort_ProfTyp 0 "Unknow" 1 "Curvature" 2 "Route Number Types" 3 "Slope（step）" 4 "Slope（liner）" 5 "Road ACCessibility" 6 "Road condition" 7 "Variable Speed Sign Position" 8 "Heading Change" 9 "Reserved for standard types" 16 "Reserved for system specific types" 18 "History average speed" 19 "Traffic Flow" 20 "Reserved for system specific types" ;
VAL_ 733 ADAS_ProfShort_PathIdx 0 "Valid value" ;
VAL_ 733 ADAS_ProfShort_CycCnt 0 "Valid value" ;
VAL_ 733 ADAS_ProfShort_Offset 0 "0-8190m" 8191 "Invalid" ;
VAL_ 733 ADAS_ProfShort_MsgTyp 0 "System Specific" 1 "Position" 2 "Segment" 3 "Stub" 4 "Profile Short" 5 "Profile Long" 6 "Meta-data" 7 "Reserved" ;
VAL_ 734 ADAS_ProfLong_Value -2147483648 "invalid" 0 "Valid value" ;
VAL_ 734 ADAS_ProfLong_Update 0 "false" 1 "true" ;
VAL_ 734 ADAS_ProfLong_Retr 0 "false" 1 "true" ;
VAL_ 734 ADAS_ProfLong_CtrlPoint 0 "false" 1 "true" ;
VAL_ 734 ADAS_ProfLong_ProfTyp 0 "unkown" 1 "Longitude" 2 "Latitude" 3 "Altitude" 4 "Control Point Longitude" 5 "Control Point Latitude" 6 "Control Point Altitude" 7 "Link Identifier" 8 "Traffic Sign" 9 "Truck Speed Limits" 10 "Extended Lane" 11 "Reserved for standard types" 16 "Reserved for system specific types" 19 "Traffic Event" 20 "weather" 21 "Reserved for system specific types" ;
VAL_ 734 ADAS_ProfLong_PathIdx 0 "Valid value" ;
VAL_ 734 ADAS_ProfLong_CycCnt 0 "Valid value" ;
VAL_ 734 ADAS_ProfLong_Offset 0 "Valid value" 8191 "Invalid" ;
VAL_ 734 ADAS_ProfLong_MsgTyp 0 "System Specific" 1 "Position" 2 "Segment" 3 "Stub" 4 "Profile Short" 5 "Profile Long" 6 "Meta-data" 7 "Reserved" ;
VAL_ 769 ECM_WCACPmpFailrSts 0 "No_fail" 1 "Fail" ;
VAL_ 769 CoolerSts 0 "Rotation_speed" 255 "Error" ;
VAL_ 769 EngLimpHomeSts 0 "Not in limp home mode" 1 "In limp home mode" ;
VAL_ 795 VCU_SysFltLvl 0 "No_Fault" 1 "Level_1" 2 "Level_2" 3 "Level_3" 4 "Level_4" 5 "Level_5" 6 "Reserved" ;
VAL_ 796 HUT_EPB_SwtPosn 0 "Neutral" 1 "Release" 2 "Apply" ;
VAL_ 799 OBC_CCLineSts 0 "Not connected" 1 "Connected" 2 "Half connection" 3 "Error" ;
VAL_ 822 DrvImpairmAsstReq 0 "Initial_value" 1 "OFF" 2 "ON" ;
VAL_ 827 LowPowerEgyMngmntModReq 0 "No_Action" 1 "OFF" 2 "ON" ;
VAL_ 829 T_BOX_AVPActvReq 0 "No Request" 1 "Request HAVP" 2 "Request PAVP" 3 "Reserved" ;
VAL_ 840 IntellgntDrvChildModDetn 0 "Initial_value" 1 "In_Child_mode" 2 "No_In_Child_Mode" ;
VAL_ 840 SentinelMode_HUT 0 "No_action" 1 "OFF" 2 "ON" 3 "Reserved" ;
VAL_ 849 RollingCounter_ABM1 0 "Valid value" 15 "Invalid value" ;
VAL_ 849 CrashSev_1 0 "Not Trigger" 1 "Trigger" ;
VAL_ 849 CrashSev_2 0 "Not Trigger" 1 "Trigger" ;
VAL_ 849 CrashSev_3 0 "Not_Trigger" 1 "Trigger" ;
VAL_ 849 CrashSev_4 0 "Not_Trigger" 1 "Trigger" ;
VAL_ 849 ThrdRowLSperSts 0 "No_person" 1 "Person" ;
VAL_ 849 ThrdRowRSperSts 0 "No_person" 1 "Person" ;
VAL_ 849 CrashSev_5 0 "Not_Trigger" 1 "Trigger" ;
VAL_ 849 AmntOfPass 0 "Not_support" 1 "_1_passenger" 2 "_2_passengers" 3 "_3_passengers" 4 "_4_passengers" 5 "_5_passengers" 6 "_6_passengers" 7 "_7_passengers" ;
VAL_ 849 SecRowMidSperSts 0 "No_person" 1 "Person" ;
VAL_ 849 SecRowRSperSts 0 "No_person" 1 "Person" ;
VAL_ 849 SecRowLSperSts 0 "No_person" 1 "Person" ;
VAL_ 849 PassSperSts 0 "No_person" 1 "Person" ;
VAL_ 849 SecRowRSBR_Visual 0 "Lamp off" 1 "Lamp on" 2 "Reserved" 3 "Lamp  blink & sound remind" ;
VAL_ 849 ThrdRowLSBR_Visual 0 "Lamp_off" 1 "Lamp_on" 3 "Lamp_blink_sound_remind" ;
VAL_ 849 ThrdRowRSBR_Visual 0 "Lamp_off" 1 "Lamp_on" 3 "Lamp_blink_sound_remind" ;
VAL_ 849 ThrdRowLSBR 0 "No_reminder" 1 "Reminder" ;
VAL_ 849 ThrdRowRSBR 0 "No_reminder" 1 "Reminder" ;
VAL_ 849 DrvSBR_Visual 0 "Lamp off" 1 "Lamp on" 2 "Reserved" 3 "Lamp  blink & sound remind" ;
VAL_ 849 PassSBR_Visual 0 "Lamp off" 1 "Lamp on" 2 "Reserved" 3 "Lamp  blink & sound remind" ;
VAL_ 849 SecRowLSBR_Visual 0 "Lamp off" 1 "Lamp on" 2 "Reserved" 3 "Lamp  blink & sound remind" ;
VAL_ 849 SecRowMidSBR_Visual 0 "Lamp off" 1 "Lamp on" 2 "Reserved" 3 "Lamp  blink & sound remind" ;
VAL_ 849 CrashOutputSts 0 "No crash" 1 "Reserved" 2 "Front First level" 3 "rear crash(Reserved)" 4 "Reserved" 8 "Right hand side" 9 "Reserved" 16 "Left hand side" 17 "Rollover(Reserved)" 18 "Static Roll(Reserved)" 19 "Reserved" ;
VAL_ 849 RSCAOFFSts 0 "Lamp_off" 1 "Lamp_on" ;
VAL_ 849 PassSBLockSts 0 "Buckled" 1 "Unbuckle" ;
VAL_ 849 SecRowRSBLockSts 0 "Buckled" 1 "Unbuckle" ;
VAL_ 849 DrvSBR 0 "No reminder" 1 "Reminder" ;
VAL_ 849 SecRowMidSBLockSts 0 "Buckled" 1 "Unbuckle" ;
VAL_ 849 AirbFailLmpCmd 0 "Lamp off" 1 "Lamp on" ;
VAL_ 849 SecRowLSBLockSts 0 "Buckled" 1 "Unbuckle" ;
VAL_ 849 PABSwtSts 0 "Switch OFF_PAB Ban" 1 "Switch ON_PAB Not Ban" ;
VAL_ 849 Checksum_ABM1 0 "Valid values" ;
VAL_ 880 Time_Day 0 "Invalid" 1 "Valid_values" ;
VAL_ 880 Time_Month 0 "Invalid" 1 "Valid month" 13 "Reserved" ;
VAL_ 880 Time_Year_Right 0 "Valid year" 10 "Reserved" 15 "Invalid" ;
VAL_ 880 Time_Year_Left 0 "Valid year" 10 "Reserved" 15 "Invalid" ;
VAL_ 880 Time_Second 0 "Valid_values" 63 "Invalid" ;
VAL_ 880 TimeMod 0 "24" 1 "12" ;
VAL_ 880 TimeIndcn 0 "am" 1 "pm" ;
VAL_ 880 Time_Minutes 0 "Valid_values" 63 "Invalid" ;
VAL_ 880 Time_Hour 0 "Valid_values" 31 "Invalid" ;
VAL_ 907 RollingCounter_PTCC1_1 15 "Invalid_value" ;
VAL_ 907 BSCSts 0 "Initial_Value" 1 "OFF" 2 "Standby" 3 "Active" 4 "Failed" ;
VAL_ 1001 T_BOX_SysErrSts 0 "No error" 1 "Error" 2 "Standby Battery Error" 3 "Reserved" ;
VAL_ 1045 ADAS_Meta_ProtVer_Minor 0 "Valid values" ;
VAL_ 1045 ADAS_Meta_SpdUnits 0 "KM/H" 1 "MPH" ;
VAL_ 1045 ADAS_Meta_MapVerYear 0 "Valid_values" 63 "Invalid" ;
VAL_ 1045 ADAS_Meta_MapVerQtr 0 "Valid values" ;
VAL_ 1045 ADAS_Meta_RegionCode 0 "Unknow" 1 "Valid_values" 32767 "Invalid" ;
VAL_ 1045 ADAS_Meta_DrvSide 0 "Drvg Side Left" 1 "Drvg Side Right" ;
VAL_ 1045 ADAS_Meta_HwVer 0 "Unknown" 1 "Valid_values" ;
VAL_ 1045 ADAS_Meta_ProtVer_MinorSub 0 "Valid values" ;
VAL_ 1045 ADAS_Meta_ProtVer_Major 0 "Valid values" ;
VAL_ 1045 ADAS_Meta_CycCnt 0 "Valid values" ;
VAL_ 1045 ADAS_Meta_CountryCode 0 "Unknown" 1 "Valid_values" ;
VAL_ 1045 ADAS_Meta_MapProvider 0 "Unknown" 1 "Nokia HERE (NAVTEQ)" 2 "TomTom (Tele Atlas)" 3 "Zenrin" 4 "IPC" 5 "NavInfo" 6 "Other" 7 "N/A" ;
VAL_ 1045 ADAS_Meta_MsgTyp 0 "System Specific" 1 "Position" 2 "Segment" 3 "Stub" 4 "Profile Short" 5 "Profile Long" 6 "Meta-data" 7 "Reserved" ;
VAL_ 68 CarWashModeReq 0 "OFF" 1 "ON" 2 "No_action" 3 "Reserved" ;
VAL_ 74 AutoAVMSwSet_Cmd 0 "No Request" 1 "Request" ;
VAL_ 74 SwToFieldCalRstCmd 0 "Off" 1 "On" ;
VAL_ 74 View_SoftswitchCmd 0 "No request" 1 "Request" ;
VAL_ 74 FPAS_AutoModSwt 0 "No Request" 1 "Request" ;
VAL_ 74 MEBSwtSet 0 "No Request" 1 "Request" ;
VAL_ 74 CarMdlDispCmd 0 "No Request" 1 "Request" ;
VAL_ 74 CarMdlTrsprcySwtCmd 0 "No Request" 1 "Request" ;
VAL_ 74 AutoViewChgCmd 0 "No Request" 1 "Request" ;
VAL_ 74 SlopViewExitReq 0 "No_action" 1 "Request" ;
VAL_ 74 LaneCalActvtCmd 0 "Off" 1 "On" ;
VAL_ 74 Sgl_View_Sel 0 "No Commands" 1 "Touch 2D Front Button" 2 "Touch 2D Rear Button" 3 "Touch 2D Left Button" 4 "Touch 2D Right Button" 5 "Touch 2D Left Front  Button" 6 "Touch 2D Right Front Button" 7 "Touch 2D Left Back Button" 8 "Touch 2D Right Back Button" 9 "Touch return Button" 10 "Touch Engine Room Button" 11 "Touch_Front_Wheel_Button" 12 "Touch_Rear_Wheel_Button" 13 "Vertical_View_Button" 14 "Single_View_Button" 15 "Request" ;
VAL_ 74 AutoAVMmodSet 0 "No_Action" 1 "Half_screen" 2 "Full_screen" ;
VAL_ 74 SlopViewFuncSet 0 "No_action" 1 "OFF" 2 "ON" ;
VAL_ 74 WheelVieSwt 0 "No_Action" 1 "Request" ;
VAL_ 96 RollingCounter_HCU_PT14 0 "Valid_values" 15 "Invalid_value" ;
VAL_ 96 EGRreq 0 "No_request" 1 "limit_EGR" 2 "OFF" ;
VAL_ 96 HCU_TgtGearReq_TCU 0 "Default_value" 1 "_1st_gear" 2 "_2nd_gear" 3 "_3rd_gear" 4 "_4th_gear" 5 "N1_gear" 6 "N2_gear" 7 "N3_gear" 8 "N4_gear" 9 "Pre_1_gear" 10 "Pre_2_gear" 11 "Pre_3_gear" 12 "Pre_4_gear" 13 "R" ;
VAL_ 96 EmgyEngageReq_TCU 0 "No_request" 1 "Request" ;
VAL_ 96 EmgyShiftNReq_TCU 0 "No_request" 1 "Request" ;
VAL_ 96 ShiftAllwdCmd_TCU 0 "Not_allowed" 1 "Allowed" ;
VAL_ 96 HCU_bAcvTqCtrl 0 "Inactive" 1 "Active" ;
VAL_ 96 HCU_bAcvSyncReq 0 "Inactive" 1 "Active" ;
VAL_ 96 HCU_TCUPTAllwdCmd 0 "Not_Allowed" 1 "Allowed" ;
VAL_ 96 HCU_TCUKPAllwdCmd 0 "Not_Allowed" 1 "Allowed" ;
VAL_ 96 RollingCounter_HCU_HP11 0 "Valid_values" 15 "Invalid_value" ;
VAL_ 96 HCU_TCUEmgyEngageReq 0 "No_Request" 1 "Request" ;
VAL_ 96 HCU_AccPedalPosnCorrdValid 0 "Invaild" 1 "Vaild" ;
VAL_ 96 TargetGear_RA 0 "Default_value" 1 "_1st_gear" 2 "_2nd_gear" 3 "N_gear" ;
VAL_ 96 HCU_TCUEmgyShiftNReq 0 "No_Request" 1 "Request" ;
VAL_ 96 HCU_StLimphm 0 "Inactive" 1 "Active" ;
VAL_ 96 HCU_TrqReq_TrsmClutchValid 0 "Invalid" 1 "Valid" ;
VAL_ 96 HCU_AccPedalPosnCorrd 0 "Valid_values" ;
VAL_ 96 RollingCounter_HCU_HP10 0 "Valid_Value" 15 "Invalid_Value" ;
VAL_ 96 TrqReq_FAValid 0 "Invaild" 1 "Vaild" ;
VAL_ 96 HCU_EPBReleaseReq 0 "No_Request" 1 "Request" ;
VAL_ 96 TrqReq_FA 0 "Valid_values" ;
VAL_ 96 HCU_PowertrainSts 0 "Sleep" 1 "Initialize_Mode" 2 "power_Up" 3 "power_Down" 4 "Home" 5 "run" 6 "Charging" 7 "Cellphone_AC" 8 "Limphome" 9 "Emergency_Mode" 10 "V2L" 11 "Prepare_Sleep" 12 "ready" 13 "LV_Charging" 14 "LT_Charging" 15 "IL_Heating" 16 "Thermal_Run_Away" 17 "End_Of_Line" 18 "BattTempKeep" 19 "Reserved" ;
VAL_ 96 HCU_ActvSysOperMode 0 "Default_value" 1 "EV" 2 "Series" 3 "Direct_Drive" 4 "Power_Split" ;
VAL_ 96 HCU_TgtSysOperMode 0 "Default_value" 1 "EV" 2 "Series" 3 "Direct_Drive" 4 "Power_Split" ;
VAL_ 96 HCU_EPBReleaseReqValid 0 "Invaild" 1 "Vaild" ;
VAL_ 96 HCU_ChrgDeplt 0 "No" 1 "Yes" ;
VAL_ 96 HCU_DCTCreepInhbn 0 "Not_Active" 1 "Active" ;
VAL_ 96 HCU_KickDownActv 0 "Not_Active" 1 "Active" ;
VAL_ 96 TrqReqFastPathEnable 0 "Not_enable" 1 "Enable" ;
VAL_ 96 TrqReqSlowPathEnable 0 "Not_enable" 1 "Enable" ;
VAL_ 96 HCU_EngBrkActv_Flg 0 "No_Engine_Brake" 1 "Engine_Brake_Active" ;
VAL_ 96 HCU_TCUSleepReq 0 "No_Request" 1 "Request" ;
VAL_ 96 HCU_TgtSyPosnReq 0 "Default_value" 1 "EV" 2 "Power_Split" ;
VAL_ 96 HCU_EVTgtGearSts 0 "Not_Active" 1 "Active" 2 "InValid_Values" ;
VAL_ 96 TrqLowLimit 0 "Valid_values" 1023 "Invalid" ;
VAL_ 96 Checksum_HCU_HP10 0 "Valid_Values" ;
VAL_ 96 RollingCounter_HCU_HP1 0 "Valid_values" 15 "Invalid_value" ;
VAL_ 96 HCU_TgtEngTrqValid 0 "Invalid_Value" 1 "Valid_Value" ;
VAL_ 96 HCU_TrqReqWoDCT_TrsmClutchValid 0 "Invalid_Value" 1 "Valid_Value" ;
VAL_ 96 HCU_MaxEngTrqLimtValid 0 "Invalid_Value" 1 "Valid_Value" ;
VAL_ 96 HCU_NetTrq_TrsmClutchValid 0 "Invalid_Value" 1 "Valid_Value" ;
VAL_ 96 HCU_K0ClutchAdaptAck 0 "Inactive" 1 "Active" ;
VAL_ 96 HCU_TrsmClutchAdaptAck 0 "Inactive" 1 "Active" ;
VAL_ 96 HCU_MaxTrqLimt_TrsmClutch 0 "Valid_values" ;
VAL_ 96 HCU_TrqReqWoDCT_TrsmClutch 0 "Valid_values" ;
VAL_ 96 HCU_TrqReq_TrsmClutch 0 "Valid_values" ;
VAL_ 96 HCU_NetTrq_TrsmClutch 0 "Valid_values" ;
VAL_ 96 RollingCounter_HCU_HP8 0 "Valid_values" 15 "Invalid_value" ;
VAL_ 96 HCU_StCluReq 0 "No_Request" 1 "Force_Open" 2 "Comfort_Open" 3 "Closed" ;
VAL_ 96 TorqueLossValid 0 "Invalid_value" 1 "Valid_value" ;
VAL_ 96 HCU_TrqLimMax_Norm 0 "Valid_values" ;
VAL_ 96 TorqueLoss 0 "Valid_values" ;
VAL_ 96 RollingCounter_HCU_PT1 0 "Valid_Value" 15 "Invalid_Value" ;
VAL_ 96 HCU_StartStopTypReq 0 "Init_and_no_start" 1 "_12V_starter_start_idle" 2 "P0_P1_P2_12V_BSG_normal_start_idle" 3 "P0_P1_P2_12V_BSG_cold_start_idle" 5 "P0_P1_P2_comfort_start_drive" 6 "P0_P1_P2_dynamic_start_drive" 7 "P2_fast_start_drive" 8 "_12V_starter_12V_BSG_start_drive" 9 "Lever_method_start" 10 "P2_slipping_start_coasting_braking" 11 "P2_fast_start_coasting_Braking" 13 "Launch_start" ;
VAL_ 96 ActWheelTrqDmd 0 "Vaild_Value" ;
VAL_ 96 VCU_RoadTyp 0 "Initial_value" 1 "Type1" 2 "Type2" 3 "Type3" 4 "Type4" 5 "Type5" 6 "Type6" 7 "Type7" 8 "Type8" 9 "Type9" 10 "Type10" 11 "Type11" 12 "Type12" 13 "Type13" 14 "Type14" 15 "Type15" ;
VAL_ 96 Checksum_HCU_PT1 0 "Valid_Values" ;
VAL_ 96 RollingCounter_HCU_PT11 0 "Valid_values" 15 "Invalid_value" ;
VAL_ 96 HCU_TrqCrksftReq 0 "Valid_values" ;
VAL_ 96 HCU_ActTqCrksft 0 "Valid_values" ;
VAL_ 96 HCU_ActTqCrksftValid 0 "Invalid" 1 "Valid" ;
VAL_ 96 HCU_RefAllwdCmd_TCU 0 "Not_Allowed" 1 "Allowed" ;
VAL_ 96 HCU_ECMPumpReq 0 "Valid_values" ;
VAL_ 96 Idle_C_AWDActv 0 "Not_active" 1 "Active" ;
VAL_ 96 Idle_H_AWDActv 0 "Not_active" 1 "Active" ;
VAL_ 96 Idle_E_AWDActv 0 "Not_active" 1 "Active" ;
VAL_ 121 RollingCounter_ECM1 0 "Valid value" 15 "Invalid value" ;
VAL_ 121 EngSpdVldty 0 "Invalid" 1 "Valid" 2 "Initial value" 3 "Reserved" ;
VAL_ 121 EngSpd 0 "Valid values" ;
VAL_ 121 Start_StopSts 0 "non-start/stop mode" 1 "Engine standby" 2 "Engine Stopped" 3 "Starter restart" 4 "Engine restart" 5 "Engine Operation" 6 "Engine auto-stopping" 7 "Invalid" ;
VAL_ 121 BrkPedalSts 0 "Not pressed" 1 "Pressed" 2 "Reserved" 3 "Error" ;
VAL_ 121 Checksum_ECM1 0 "Valid value" ;
VAL_ 124 TCU_TrqRatio 0 "Valid values" 65534 "Unknown" 65535 "Invalid value" ;
VAL_ 124 RatAct 0 "valid values" 254 "Unknown" 255 "Invalid" ;
VAL_ 124 TC_SLIP_STATE 0 "Closed" 1 "Open" 2 "Micro slip" 3 "Slip" 4 "Reversed" 7 "Invalid" ;
VAL_ 161 RollingCounter_CSA2 0 "Valid value" 15 "Invalid value" ;
VAL_ 161 HWA_OK_OFFSwt 0 "No press" 1 "Pressed" ;
VAL_ 161 ManualShiftReq 0 "no shift/ no control" 1 "Shift up request" 2 "Shift down request" 3 "both pedals pressed" 4 "Reserved" 6 "Invalid" 7 "Fault" ;
VAL_ 161 CC_ACCSwtErr 0 "No error" 1 "Error" ;
VAL_ 161 ACCTimeGapSetSwt 0 "No_press" 1 "Pressed" ;
VAL_ 161 CC_ACC_DecSetSpd_SetSwt 0 "No press" 1 "Pressed" ;
VAL_ 161 CC_ACC_IncSetSpd_ResuSwt 0 "No press" 1 "Pressed" ;
VAL_ 161 SAS_Sts 0 "SAS Angle And Speed Correct" 1 "SAS Not Calibrated" 2 "Intermittent Error Detected" 3 "Permanent Error Detected" ;
VAL_ 161 ACC_TimeGap_DecSetSwt 0 "No press" 1 "Pressed" ;
VAL_ 161 ACC_TimeGap_IncSetSwt 0 "No press" 1 "Pressed" ;
VAL_ 161 CC_ACC_CANCEL_OFFSwt 0 "No press" 1 "Pressed" ;
VAL_ 161 CC_ACC_CRUISE_OFFSwt 0 "No press" 1 "Pressed" ;
VAL_ 161 SteerWheelSpdSign 0 "Left (Positive)" 1 "Right (Negative)" ;
VAL_ 161 SteerWheelSpd 0 "Valid value" 10161 "Reserved" 32767 "Invalid" ;
VAL_ 161 SteerWheelAngSign 0 "Left (Positive)" 1 "Right (Negative)" ;
VAL_ 161 SteerWheelAng 0 "Valid value" 7801 "Reserved" 32767 "Invalid" ;
VAL_ 161 Checksum_CSA2 0 "Valid values" ;
VAL_ 181 RollingCounter_VCU19 0 "Valid_values" 15 "Invalid_value" ;
VAL_ 181 FuelCutOffReq 0 "NO_request" 1 "Request" ;
VAL_ 181 FullTrqReq 0 "NO_request" 1 "Request" ;
VAL_ 181 RelsIGNReq 0 "NO_Request" 1 "Request" ;
VAL_ 181 HCU_GentrIdleSts_Flg 0 "No_GM_Idle" 1 "GM_Idle" ;
VAL_ 181 HCU_EngStartPre 0 "Not_Active" 1 "Active" ;
VAL_ 181 CrsCtrlOvldAccelPedal 0 "Not_active" 1 "Active" ;
VAL_ 181 HCU_EngStopReq 0 "NO_Request" 1 "Request" ;
VAL_ 181 HCU_EngStartReq 0 "NO_Request" 1 "Request" ;
VAL_ 181 TotWheelTrq_FA 0 "Vaild value" ;
VAL_ 181 NoRampsReq 0 "NO_request" 1 "Request" ;
VAL_ 181 FastTrqIntvntn 0 "Not_active" 1 "Active" ;
VAL_ 181 HCU_EngIdleReq 0 "NO_Request" 1 "Request" ;
VAL_ 181 TotWheelTrqVld_FA 0 "Invaild" 1 "Vaild" ;
VAL_ 181 TrqAct_RAValid 0 "Invalid" 1 "Valid" ;
VAL_ 181 TrqAct_RA 0 "Valid_values" ;
VAL_ 181 RollingCounter_VCU8 0 "Valid_values" 15 "Invalid_value" ;
VAL_ 181 HCU_PTRdy 0 "No_Ready" 1 "Ready" ;
VAL_ 181 AntiSurgeDamperInhb 0 "Not_inhibit" 1 "Inhibit" ;
VAL_ 181 IdleTrqReserveReq 0 "Valid_values" ;
VAL_ 181 HCU_EngStopReq_Mon 0 "NO_Request" 1 "Request" ;
VAL_ 181 HCU_TrqInterventionStateESP 0 "No_ESP_Intervention" 1 "ESP_TrqRedFastReq_FA" 2 "ESP_TrqRedSlowReq_FA" 3 "ESP_TrqIncReq_FA" ;
VAL_ 181 HCU_TrsmStsReq 0 "Transmission_Passive_Request" 1 "Transmission_Active_Request" ;
VAL_ 181 IdleLoadTrq 0 "Valid_values" 4095 "Invalid" ;
VAL_ 181 TrqReqSlowPath 0 "Valid_values" 4095 "Invalid" ;
VAL_ 181 TrqReqFastPath 0 "Valid_values" 4095 "Invalid" ;
VAL_ 181 RollingCounter_VCU15 0 "Valid_Value" 15 "Invalid_Value" ;
VAL_ 181 TotWheelTrq_RA 0 "Vaild value" ;
VAL_ 181 VCU_RespHWP 0 "No_Response" 1 "Response" ;
VAL_ 181 TotWheelTrqVld_RA 0 "Invaild" 1 "Vaild" ;
VAL_ 181 VCU_HWPInterface 0 "No_Response" 1 "Response" 2 "Response_Partially" 3 "Reserved" ;
VAL_ 181 VCU_HWPInterErrReason 0 "No_error" 1 "ERR_with_Main_ECU_on_PTCAN" 2 "ERR_with_Main_ECU_on_PMCAN" 3 "ERR_with_Main_ECU_on_both_CAN" 4 "ERR_with_Backup_ECU_on_PTCAN" 5 "ERR_with_Backup_ECU_on_PMCAN" 6 "ERR_with_Backup_ECU_on_both_CAN" 7 "ERR_with_Main_ECU_and_Backup_ECU" 8 "ERR_with_Main_ECU_and_Backup_ECU_on_PT_CAN" 9 "ERR_with_Main_ECU_and_Backup_ECU_on_PM_CAN" 10 "Reserved" ;
VAL_ 181 VCU_DrvrIntvGearSts 0 "False" 1 "True" ;
VAL_ 181 Checksum_VCU15 0 "Valid_Values" ;
VAL_ 181 RollingCounter_VCU6 0 "Valid_Value" 15 "Invalid_Value" ;
VAL_ 181 VCU_RaceLaunchAvlSts 0 "Race_Launch_is_available" 1 "Race_Launch_is_not_available_due_to_ESP_is_not_OFF" 2 "Race_Launch_is_not_available_due_to_power_system_limitations" 3 "Race_Launch_is_not_available_due_to_battery_SOC_temperature_low" ;
VAL_ 181 VCU_ActAccrPedlRat 0 "Valid" ;
VAL_ 181 VCU_AutParkAvlSts 0 "Not_Available" 1 "Available" ;
VAL_ 181 VCU_BrkPedlSts 0 "No_Active" 1 "Brake_Active" 2 "Invalid" 3 "Reserved" ;
VAL_ 181 HCU_BrkPedalStsValid 0 "Invalid_Value" 1 "Valid_Value" ;
VAL_ 181 VCU_APedlPosVld 0 "Invalid" 1 "Valid" ;
VAL_ 181 VCU_AccelPedalPosnValid 0 "Invalid_Value" 1 "Valid_Value" ;
VAL_ 181 VCU_VirtAccrPedlRat 0 "Valid" ;
VAL_ 181 Checksum_VCU6 0 "Valid_Values" ;
VAL_ 181 RollingCounter_VCU4 0 "Valid_values" 15 "Invalid_value" ;
VAL_ 181 VCU_CurrRgnTqVld 0 "Not_Initialized" 1 "Normal" 2 "Faulty" ;
VAL_ 181 VCU_MaxAvlRgnTqVld 0 "Not_Initialized" 1 "Normal" 2 "Faulty" ;
VAL_ 181 VCU_EPBActvReqVld 0 "Invalid" 1 "Valid" ;
VAL_ 181 VCU_EPBActvReq 0 "No_request" 1 "Request" ;
VAL_ 181 VCU_CurrRgnTq 0 "Valid_values" ;
VAL_ 181 VCU_MaxAvlRgnTq 0 "Valid_values" ;
VAL_ 181 RollingCounter_VCU1 0 "Valid_values" 15 "Invalid_value" ;
VAL_ 181 VCU_HvPowerCtrl 0 "Default" 1 "Powerup" 2 "Powerup_For_Charge" 3 "Powerdown" 4 "Emergency_To_Shut_Down" 5 "DC_Charging_For_400V_S1_S3" 6 "DC_Charging_For_400V_S1" 7 "DC_Charging_For_400V_S3" ;
VAL_ 181 VCU_IntellEscapeSts 0 "Not_Active" 1 "Active" ;
VAL_ 181 VCU_LoUBattSpU 0 "Valid_values" 255 "Invalid" ;
VAL_ 181 VCU_DCDCModReq 0 "Default" 1 "Standby" 2 "Buck" 3 "Precharge" 4 "Discharge" ;
VAL_ 181 VCU_ChrgEna 0 "Init_value" 1 "Disable" 2 "Enable" 3 "Enable_Heating_only" ;
VAL_ 181 VCU_ACURefFailr 0 "Withdraw_Referencing_Due_To_Timeout" 1 "Withdraw_Referencing_Due_To_Driver_Demand" 2 "Normal" ;
VAL_ 181 VCU_RaceLaunchSts 0 "Not_active" 1 "Active" 2 "Timeout_protection" 3 "Super_race_launch_active" 4 "Super_race_launch_is_not_available_due_to_battery_available_power_low_normal_race_activated" 5 "Super_race_launch_is_not_available_due_to_transmission_temperature_high_normal_race_activated" 6 "The_maximum_times_of_super_race_launch_is_reached_normal_race_activatedivated" ;
VAL_ 181 VCU_ACUEmgyShiftNReq 0 "Invalid" 1 "Valid" ;
VAL_ 181 VCU_ShiftAllwdCmd_ACU 0 "ShiftNotPermission" 1 "ShiftPermission" ;
VAL_ 181 VCU_TgtGearReq_ACU 0 "Default_value" 1 "_1st_gear" 2 "_2nd_gear" 3 "N_gear" 4 "Pre_2_gear" 5 "Pre_1_gear" ;
VAL_ 181 VCU_ACUSleepReq 0 "Wake_Up" 1 "Sleep" ;
VAL_ 181 VCU_RefAllwdCmd_ACU 0 "Not_Allowed" 1 "Allowed" ;
VAL_ 181 VCU_ACUEmgyEngageReq 0 "No_Request" 1 "Request" ;
VAL_ 181 RollingCounter_VCU18 0 "Valid_values" 15 "Invalid_value" ;
VAL_ 181 HCU_K0ClutchStatusReq 0 "No_Request" 1 "Open_Request" 2 "Close_Request" 3 "HCU_K0_Torque_Control_Request" ;
VAL_ 181 HCU_MinEngTrqLimValid 0 "Invalid_Value" 1 "Valid_Value" ;
VAL_ 181 FastRedTrqLimValid 0 "Invalid_value" 1 "Valid_value" ;
VAL_ 181 HCU_TrsmClutchStatusReq 0 "No_Request" 1 "Comfort_Open_Request" 2 "Emergency_Open_Request" 3 "Slipping_Request" ;
VAL_ 181 HCU_TrsmClutchTargetSpeedDif 0 "Valid_values" ;
VAL_ 181 HCU_K0ClutchTrqReq 0 "Valid_values" ;
VAL_ 181 HCU_MinTrqLim_TrsmClutch 0 "Valid_values" ;
VAL_ 181 HCU_FastRedTrqLim_TrsmClutch 0 "Valid_values" ;
VAL_ 189 RollingCounter_ESP12 0 "Valid value" 15 "Invalid value" ;
VAL_ 189 ESP_VehHldSts 0 "Not active" 1 "Active" ;
VAL_ 189 TgtRcprtnTrqReq 0 "Valid values" ;
VAL_ 189 Checksum_ESP12 0 "Valid values" ;
VAL_ 189 TgtRcprtnTrqSts 0 "Not Initialized" 1 "Normal" 2 "Faulty" 3 "Reserved" ;
VAL_ 199 E_ShiftFault 0 "E-shift Normal" 1 "E-shift fault" 2 "reserved" ;
VAL_ 199 DrvReqPark 0 "no request" 1 "driver request park button" 2 "Park button fault" 3 "reserved" ;
VAL_ 199 DRV_RQ_SHFT 0 "Shifter position zero (Z) / POS_ZERO" 1 "Reserved" 2 "Shifter position two (forward twice / X2) / POS_TWO" 3 "Shifter position three (forward once / X1) / POS_THREE" 4 "Shifter position four (backwards once / Y1) / POS_FOUR" 5 "Shifter position five (backwards twice / Y2) / POS_FIVE" 6 "Reserved" 7 "Reserved" 8 "Shifter not initialized / INIT" 9 "Reserved" 15 "Signal not available / SNA (Double fault shifter sensor)" ;
VAL_ 216 ESP_VehHldSts 0 "Not_active" 1 "Active" ;
VAL_ 240 ACU_ShiftInProgress 0 "Not in progress" 1 "In progress" 2 "Reserved" 3 "Invalid" ;
VAL_ 669 InCarTemp 0 "Valid value" 254 "Initial value" 255 "Invalid value" ;
VAL_ 901 ACAmbTemp 0 "Valid value" 254 "Initial value" 255 "Invalid Value" ;
VAL_ 901 ACFrntBlwrSpd 0 "OFF" 1 "Level_1_Low" 2 "Level_2" 3 "Level_3" 4 "Level_4" 5 "Level_5" 6 "Level_6" 7 "Level_7_Hi" 8 "Reserved" 14 "Auto blower level" 15 "Initial value" ;
VAL_ 688 DrvRearDoorWinPosnSts_Perc 0 "Unknown" 1 "Close" 2 "Open" 3 "5%Open" 4 "10%Open" 5 "15%Open" 6 "20%Open" 7 "25%Open" 8 "30%Open" 9 "35%Open" 10 "40%Open" 11 "45%Open" 12 "50%Open" 13 "55%Open" 14 "60%Open" 15 "65%Open" 16 "70%Open" 17 "75%Open" 18 "80%Open" 19 "85%Open" 20 "90%Open" 21 "95%Open" 22 "Reserved" ;
VAL_ 714 DrvWinPosnSts_Perc 0 "Unknown" 1 "Close" 2 "Open" 3 "5%Open" 4 "10%Open" 5 "15%Open" 6 "20%Open" 7 "25%Open" 8 "30%Open" 9 "35%Open" 10 "40%Open" 11 "45%Open" 12 "50%Open" 13 "55%Open" 14 "60%Open" 15 "65%Open" 16 "70%Open" 17 "75%Open" 18 "80%Open" 19 "85%Open" 20 "90%Open" 21 "95%Open" 22 "Reserved" ;
VAL_ 714 RSDS_Driver_LED_Sts 0 "No error" 1 "error" ;
VAL_ 680 TranPMode_Sts 0 "Normal Mode" 1 "Transport Mode" ;
VAL_ 148 FMCU_ActualOperMod 0 "Reserved" 1 "Init" 2 "PreCharge" 3 "Standby" 4 "TrqCtl" 5 "SpdCtl" 6 "VoltageCtrl" 7 "Discharge" 8 "Afterrun" 9 "Boost" 10 "Calibrate_offset_angle" 11 "Failure" 12 "Reserved" 13 "PWheatMode" 14 "Reserved" 15 "Invalid" ;
VAL_ 148 FMCU_ActTrq 0 "Valid_Values" 16381 "Reserved" 16383 "Invalid" ;
VAL_ 210 RollingCounter_FMCU5 0 "Valid_values" 15 "Invalid_value" ;
VAL_ 210 FMCU_LockRotorSts 0 "Unlock" 1 "Lock" ;
VAL_ 210 FMCU_ErrorCode 0 "Valid_values" ;
VAL_ 210 FMCU_ActRotSpd 0 "Valid" 65535 "Invalid" ;
VAL_ 210 FMCU_ActPosRotSpd 0 "Valid_values" 65535 "Invalid" ;
VAL_ 210 FMCU_InvPlsOffSts 0 "Inactive" 1 "Active" 2 "Invalid" ;
VAL_ 210 FMCU_ASCSts 0 "Inactive" 1 "Active" 2 "Invalid" ;
VAL_ 210 FMCU_FailSts 0 "No_Error" 1 "Only_Report_DFC" 2 "Limited_Operation_failure" 3 "Failure_Enter_standby_Fail_Silent_disable" 4 "Failure_ASC_or_freewheeling_dependent_on_speed_Emergency_shutdown" 5 "Failure_ASC_independent_on_speed" 6 "Discharge_failure_ASC_independent_on_speed" ;
VAL_ 230 RMCU_ActTrq 0 "Valid_Values" 16381 "Reserved" 16383 "Invalid" ;
VAL_ 231 RMCU_ActualOperMod 1 "Init" 2 "PreCharge" 3 "Standby" 4 "TrqCtl" 5 "SpdCtl" 6 "VoltageCtrl" 7 "Discharge" 8 "Afterrun" 9 "Boost" 10 "Calibrate_offset_angle" 11 "Failure" 13 "PWheatMode" 14 "Parkingheating" 15 "BUCK" ;
VAL_ 231 RMCU_ActRotSpd 0 "Valid" 65535 "Invalid" ;
VAL_ 768 ASLCtrlSts 0 "OFF" 1 "Standby" 2 "Overspeed" 3 "Limit" 4 "Reserved" 5 "KickDown" 6 "Reserved" ;
VAL_ 768 TgtASLVehSpd 0 "Valid_Values" ;
VAL_ 768 RWSModSts 0 "Initial_Value" 1 "PDCUMod" 2 "AdasMod" 3 "IBCMod" 4 "SBWMod" ;
VAL_ 768 RWSModFailSts 0 "NO_Fault" 1 "Adas_AngReqLimit_Exceed" 2 "Adas_AngSpdReqLimit_Exceed" 3 "ADAS_VldSig_Invalid" 4 "ADAS_Msg_Invalid" 5 "PDCU_Sys_Failure" 6 "RWS_Sys_Failure" 7 "ADAS_DrvgVldSig_Invalid" 8 "BTC_Mod_Sts" 9 "ADAS_DrvgMsg_Invalid" ;
VAL_ 188 RWS_FailSts 0 "No_fault" 1 "Permanent_Error_Detected" 2 "Intermittent_Error_Detected" 3 "Unimportant_Error_Detected" ;
VAL_ 188 RWS_SteerSpd 0 "Initial_Value" ;
VAL_ 188 RWS_SteerSpdVld 0 "Invalid" 1 "Valid" ;
VAL_ 188 RWS_AngActVld 0 "Invalid" 1 "Valid" ;
VAL_ 188 RWS_AngAct 4095 "Initial_Value" ;
VAL_ 188 RWS_StsResp 0 "Initial_Value" 1 "Normal" 2 "CrabMod" 3 "ManualMod" ;
VAL_ 209 RollingCounter_IBooster1 0 "Valid value" 15 "Invalid value" ;
VAL_ 209 DrvReqFxBrkDomAvail_Backup 0 "SignalAvailability_NotInitialized" 1 "SignalAvailability_Fault" 2 "SignalAvailability_Full" 3 "Reserved" ;
VAL_ 209 IsDrvReqFxBrakeDom_Backup 0 "Not_dominate" 1 "Dominate" ;
VAL_ 209 Checksum_IBooster1 0 "Valid values" ;
VAL_ 241 BMS_ErrCategory 0 "No Error" 1 "Level1" 2 "Level2" 3 "Level3" 4 "Level4" 5 "Level5" 6 "Level6" 7 "Level7" ;
VAL_ 255 RollingCounter_Body_Hei 15 "Invalid_value" ;
VAL_ 255 HeiSnsrSts_RR 0 "Initial_value" 1 "No_Failure" 2 "Failure" ;
VAL_ 255 HeiSnsrSts_RL 0 "Initial_value" 1 "No_Failure" 2 "Failure" ;
VAL_ 255 HeiSnsrSts_FR 0 "Initial_value" 1 "No_Failure" 2 "Failure" ;
VAL_ 255 HeiSnsrSts_FL 0 "Initial_value" 1 "No_Failure" 2 "Failure" ;
VAL_ 255 HeiSnsrLvlCtrlCalCmpl 0 "Initial_value" 1 "Level_calibration_not_completed" 2 "Level_calibration_completed" ;
VAL_ 255 HeiSnsrCurrHei_RR 0 "Initial_value" 255 "Invalid_value" ;
VAL_ 255 HeiSnsrCurrHei_RL 0 "Initial_value" 255 "Invalid_value" ;
VAL_ 255 HeiSnsrCurrHei_FR 0 "Initial_value" 255 "Invalid_value" ;
VAL_ 255 HeiSnsrCurrHei_FL 0 "Initial_value" 255 "Invalid_value" ;
VAL_ 287 L3_ADCRampOffSuspendSts_Backup 0 "ADC_Normal" 1 "ADC_SuspenByOtherBrake" 2 "ADC_RampOffByDriverBrake" 3 "Reserved" ;
VAL_ 288 RollingCounter_ABS2_Backup 0 "Valid value" 15 "Invalid value" ;
VAL_ 288 WssRREdgesSumVld_Backup 0 "Invalid" 1 "Valid" ;
VAL_ 288 WssRLEdgesSumVld_Backup 0 "Invalid" 1 "Valid" ;
VAL_ 288 WssRLEdgesSum_Backup 0 "Valid Values" ;
VAL_ 288 WssRREdgesSum_Backup 0 "Valid Values" ;
VAL_ 288 RRWheelSpd_Backup 0 "Valid values" 5334 "Reserved" ;
VAL_ 288 RRWheelSpdVld_Backup 0 "Invalid" 1 "Valid" ;
VAL_ 288 RRWheelDriveDirection_Backup 0 "Invalid" 1 "Forward" 2 "Backward" 3 "Stop" ;
VAL_ 288 RLWheelSpd_Backup 0 "Valid values" 5334 "Reserved" ;
VAL_ 288 RLWheelSpdVld_Backup 0 "Invalid" 1 "Valid" ;
VAL_ 288 RLWheelDriveDirection_Backup 0 "Invalid" 1 "Forward" 2 "Backward" 3 "Stop" ;
VAL_ 288 Checksum_ABS2_Backup 0 "Valid values" ;
VAL_ 288 RollingCounter_IBooster_FD2_5 0 "Valid value" 15 "Invalid value" ;
VAL_ 288 Checksum_IBooster_FD2_5 0 "Valid values" ;
VAL_ 288 RollingCounter_ABS3_Backup 0 "Valid value" 15 "Invalid value" ;
VAL_ 288 VehSpd_Backup 0 "Valid values" 5334 "Reserved" ;
VAL_ 288 VehSpdVld_Backup 0 "Invalid" 1 "Valid" ;
VAL_ 288 Checksum_ABS3_Backup 0 "Valid values" ;
VAL_ 288 RollingCounter_ABS1_Backup 0 "Valid value" 15 "Invalid value" ;
VAL_ 288 WssFREdgesSumVld_Backup 0 "Invalid" 1 "Valid" ;
VAL_ 288 WssFLEdgesSumVld_Backup 0 "Invalid" 1 "Valid" ;
VAL_ 288 WssFREdgesSum_Backup 0 "Valid Values" ;
VAL_ 288 WssFLEdgesSum_Backup 0 "Valid Values" ;
VAL_ 288 FRWheelSpd_Backup 0 "Valid values" 5334 "Reserved" ;
VAL_ 288 FRWheelSpdVld_Backup 0 "Invalid" 1 "Valid" ;
VAL_ 288 FRWheelDriveDirection_Backup 0 "Invalid" 1 "Forward" 2 "Backward" 3 "Stop" ;
VAL_ 288 FLWheelSpd_Backup 0 "Valid values" 5334 "Reserved" ;
VAL_ 288 FLWheelSpdVld_Backup 0 "Invalid" 1 "Valid" ;
VAL_ 288 FLWheelDriveDirection_Backup 0 "Invalid" 1 "Forward" 2 "Backward" 3 "Stop" ;
VAL_ 288 Checksum_ABS1_Backup 0 "Valid values" ;
VAL_ 288 VehStandstill_Backup 0 "Not standstill" 1 "Standstill" 2 "Invalid (short unavailability, max 3s)" 3 "Reserved" ;
VAL_ 288 IB_BrkPedalAppldVld 0 "Not initialized" 1 "Normal" 2 "Faulty" 3 "Reserved" ;
VAL_ 288 IB_BrkPedalAppld 0 "Not applied" 1 "Applied" ;
VAL_ 296 DCDC_FailSts 0 "No error" 1 "Level1 fault" 2 "Level2 fault" 3 "Level3 fault" 4 "Reserved" ;
VAL_ 320 RollingCounter_RWA_FD2_2 15 "Invalid_value" ;
VAL_ 320 SBWActr_PinionAngSpd_Backup 0 "Initial_value" ;
VAL_ 320 SBWActr_PinionAng_Backup 0 "Initial_value" ;
VAL_ 326 SuspLvlTrigSrc 0 "No_leveling" 1 "leveling_by_switch" 2 "leveling_by_driving_mode" 3 "leveling_by_expert_mode" 4 "leveling_by_vehicle_speed" 5 "leveling_by_key" 6 "leveling_by_APP" 7 "leveling_by_kicking" ;
VAL_ 326 RollingCounter_VDC1 0 "Valid_value" 15 "Invalid_value" ;
VAL_ 326 LvlCtrlCalCmpl 0 "Level calibration not completed" 1 "Level calibration completed" ;
VAL_ 326 TarLvlChg 0 "Normal" 1 "Low_Level_2_EasyAccess" 2 "Low_Level_1_Highway" 3 "High_Level_1_Off_road1" 4 "High_Level_2_Off_road2" 5 "High_Level_3_Extra_off_road" 6 "Locked_Low_Level_2_Locked_EasyAccess" 7 "Rear_Axle_Loading" ;
VAL_ 326 CurrLvlCtrlMode 0 "Normal" 1 "Low_Level_2_EasyAccess" 2 "Low_Level_1_Highway" 3 "High_Level_1_Off_road1" 4 "High_Level_2_Off_road2" 5 "High_Level_3_Extra_off_road" 6 "Locked_Low_Level_2_Locked_EasyAccess" 7 "Rear_Axle_Loading" ;
VAL_ 326 CurrHei_RR 0 "Valid" 255 "Invalid" ;
VAL_ 326 CurrHei_RL 0 "Valid" 255 "Invalid" ;
VAL_ 326 CurrHei_FR 0 "Valid" 255 "Invalid" ;
VAL_ 326 CurrHei_FL 0 "Valid" 255 "Invalid" ;
VAL_ 326 LvlAdjmtSts 0 "No_action" 1 "Lowering" 2 "Lifting" 3 "Pending" 4 "Rear_lowering" 5 "Rear_lifting" 6 "Rear_pending" 7 "Reserved" ;
VAL_ 326 Checksum_VDC1 0 "Valid values" ;
VAL_ 332 RollingCounter_RWA_FD1_2 15 "Invalid_value" ;
VAL_ 332 SBWActr_PinionAngSpd 0 "Initial_value" ;
VAL_ 332 SBWActr_PinionAng 0 "Initial_value" ;
VAL_ 346 RollingCounter_LBM2 0 "Valid value" 15 "Invalid value" ;
VAL_ 346 LBMPackVoltageASIL 0 "Valid" 16383 "Invalid" ;
VAL_ 346 Checksum_LBM2 0 "Valid values" ;
VAL_ 356 RollingCounter_EPS_FD2_3 15 "Invalid_value" ;
VAL_ 356 RollingCounter_EPS_FD2_2 15 "Invalid_value" ;
VAL_ 356 EPS_LKATrqOvlDlvdSts_Backup 0 "Not_active" 1 "Active" 2 "Temporary_inhibit" 3 "Permanently_failed" ;
VAL_ 356 EPS_LKAAngDlvdSts_Backup 0 "Not_active" 1 "Active" 2 "Temporary_inhibit" 3 "Permanently_failed" ;
VAL_ 356 EPS_HADHndShkRespSt_Backup 0 "Off" 1 "Reserved" 2 "Reserved" 3 "Reserved" 4 "HWP_Active" 5 "Failure" ;
VAL_ 356 EPS_AvailSts_Backup 0 "Temporary_inhibit" 1 "Available_for_control" 2 "Active" 3 "Permanently_failed" ;
VAL_ 356 EPS_DrvInpTrqVal_HiResVld_Backup 0 "Invalid" 1 "Valid" ;
VAL_ 356 EPS_AvailStsforHAD_Backup 0 "Not_available" 1 "Available_degraded" 2 "Available" ;
VAL_ 356 EPS_HADerror_Reason_Backup 0 "No_Error" 1 "IDC_L3_Backupquest_Is_Invalid_" 2 "IDC_L3_Communication_Error" 3 "IDC_L3_Fault" 4 "EPS_Internal_Error_Detected_" 5 "Under_Voltage_Detected_" 6 "Over_Voltage_Detected_" 7 "ADS_Backupquested_Steering_Angle_Is_Above_The_Limit" 8 "Change_Rate_Of_ADS_Backupquested_Steering_Angle_Is_Above_The_Limit_" 9 "Vehicle_Speed_Wheel_Speed_Error" 10 "IDC_L2_Error" 11 "TAS_Sensor_Error" ;
VAL_ 356 EPS_LKATorqOvrlDlvdVld_Backup 0 "Invalid" 1 "Valid" ;
VAL_ 356 RollingCounter_EPS_FD2_1 15 "Invalid_value" ;
VAL_ 356 EPS_TrqSnsrSts_Backup 0 "Normal" 1 "Abnormal" ;
VAL_ 356 EPS_InterferDetdVld_Backup 0 "Invalid" 1 "Valid" ;
VAL_ 356 EPS_SteerWheelSpd_Backup 32767 "Invalid" ;
VAL_ 356 EPS_SteerWheelSpdSign_Backup 0 "Left_Positive" 1 "Right_Negative" ;
VAL_ 356 EPS_SteerWheelAng_Backup 32767 "Invalid" ;
VAL_ 356 EPS_SteerWheelAngVld_Backup 0 "Invalid" 1 "Valid" ;
VAL_ 356 EPS_SteerWheelAngSign_Backup 0 "Left_Positive" 1 "Right_Negative" ;
VAL_ 356 EPS_InterferDetd_Backup 0 "No_Interference" 1 "Interference" ;
VAL_ 356 EPS_AngCmdOverRange_Backup 0 "Not_over_ange" 1 "Over_ange" ;
VAL_ 356 EPS_FailSts_Backup 0 "No_fault" 1 "Permanent_Error_Detected" 2 "Intermittent_Error_Detected" ;
VAL_ 536 DCDC_ActSts 0 "Init" 1 "Standby" 2 "Buck" 3 "Precharge" 4 "Discharge" 5 "Failure" 6 "Presleep" 7 "Reserved" ;
VAL_ 597 PhyHazardSwt 0 "No_pressed" 1 "Pressed" ;
VAL_ 597 RFPosnLmpFailSts_Zone 0 "No_failure" 1 "Failure" ;
VAL_ 597 LFPosnLmpFailSts_Zone 0 "No_failure" 1 "Failure" ;
VAL_ 597 RFTurnLmpFailSts_Zone 0 "No_failure" 1 "Failure" ;
VAL_ 597 LFTurnLmpFailSts_Zone 0 "No_failure" 1 "Failure" ;
VAL_ 597 RLowBeamFailSts_Zone 0 "No_failure" 1 "Failure" ;
VAL_ 597 LLowBeamFailSts_Zone 0 "No_failure" 1 "Failure" ;
VAL_ 597 RHiBeamFailSts_Zone 0 "No_failure" 1 "Failure" ;
VAL_ 597 LHiBeamFailSts_Zone 0 "No_failure" 1 "Failure" ;
VAL_ 597 HiPosnBrkLmpFailSts_Zone 0 "No_failure" 1 "Failure" ;
VAL_ 597 RRFogLmpFailSts_Zone 0 "No_failure" 1 "Failure" ;
VAL_ 597 LRFogLmpFailSts_Zone 0 "No_failure" 1 "Failure" ;
VAL_ 597 RFFogLmpFailSts_Zone 0 "No_failure" 1 "Failure" ;
VAL_ 597 LFFogLmpFailSts_Zone 0 "No_failure" 1 "Failure" ;
VAL_ 597 RBrkLmpFailSts_Zone 0 "No_failure" 1 "Failure" ;
VAL_ 597 LBrkLmpFailSts_Zone 0 "No_failure" 1 "Failure" ;
VAL_ 597 RRPosnLmpFailSts_Zone 0 "No_failure" 1 "Failure" ;
VAL_ 597 LRPosnLmpFailSts_Zone 0 "No_failure" 1 "Failure" ;
VAL_ 597 RRTurnLmpFailSts_Zone 0 "No_failure" 1 "Failure" ;
VAL_ 597 LRTurnLmpFailSts_Zone 0 "No_failure" 1 "Failure" ;
VAL_ 597 HiPosnBrkLmpOutpSts_Zone 0 "OFF" 1 "ON" ;
VAL_ 597 PosnLmpOutpSts_Zone 0 "OFF" 1 "ON" ;
VAL_ 597 RBrkLmpOutpSts_Zone 0 "OFF" 1 "ON" ;
VAL_ 597 LBrkLmpOutpSts_Zone 0 "OFF" 1 "ON" ;
VAL_ 597 RFogLmpSts_Zone 0 "OFF" 1 "ON" ;
VAL_ 597 FFogLmpSts_Zone 0 "OFF" 1 "ON" ;
VAL_ 597 RTurnLmpSts_Zone 0 "OFF" 1 "ON" ;
VAL_ 597 LTurnLmpSts_Zone 0 "OFF" 1 "ON" ;
VAL_ 597 LowBeamSts_Zone 0 "OFF" 1 "ON" ;
VAL_ 597 HiBeamSts_Zone 0 "OFF" 1 "ON" ;
VAL_ 647 RollingCounter_HC1 0 "Valid value" 15 "Invalid value" ;
VAL_ 647 ALS_FailSts 0 "No failure" 1 "Failure" ;
VAL_ 647 Checksum_HC1 0 "Valid values" ;
VAL_ 748 DVR_360VideoCaptureReq 0 "Off" 1 "On" ;
VAL_ 748 DVRSts 0 "DVR_Normal Operation" 1 "DVR_Error Operation" 2 "TF1 is not inset" 3 "TF1 is fault" 4 "TF1 is full" 5 "TF1 is writing slow" 6 "TF2 is not inset" 7 "TF2 is fault" 8 "TF2 is full" 9 "TF2 is writing slow" 10 "Reserved" ;
VAL_ 770 WarnKeyInCarWhenExit 0 "No_Warning" 1 "Warning" ;
VAL_ 772 FLIntellgntAsscLmpSts 0 "Initial_value" 1 "Off" 2 "Breathe" 3 "Always_Bright" ;
VAL_ 776 LTurnLmpFailSts_HCM 0 "No failure" 1 "failure" ;
VAL_ 776 LTurnLmpSts 0 "OFF" 1 "ON" ;
VAL_ 776 LHiBeamSts 0 "Off" 1 "On" ;
VAL_ 776 LHiBeamFailSts_HCM 0 "No failure" 1 "failure" ;
VAL_ 776 LLowBeamSts 0 "Off" 1 "On" ;
VAL_ 776 LLowBeamFailSts_HCM 0 "No failure" 1 "failure" ;
VAL_ 776 LFPosnLmpFailSts_HCM 0 "No_failure" 1 "Failure" ;
VAL_ 781 RTurnLmpFailSts_HCM 0 "No failure" 1 "failure" ;
VAL_ 781 RTurnLmpSts 0 "OFF" 1 "ON" ;
VAL_ 781 RHiBeamSts 0 "Off" 1 "On" ;
VAL_ 781 RHiBeamFailSts_HCM 0 "No failure" 1 "failure" ;
VAL_ 781 RLowBeamSts 0 "Off" 1 "On" ;
VAL_ 781 RLowBeamFailSts_HCM 0 "No failure" 1 "failure" ;
VAL_ 781 RFPosnLmpFailSts_HCM 0 "No_Failure" 1 "Failure" ;
VAL_ 816 FRIntellgntAsscLmpSts 0 "Initial_value" 1 "Off" 2 "Breathe" 3 "Always_Bright" ;
VAL_ 818 RLIntellgntAsscLmpSts 0 "Initial_value" 1 "Off" 2 "Breathe" 3 "Always_Bright" ;
VAL_ 818 RFLTurnLmpFailSts 0 "No_Failure" 1 "Failure" ;
VAL_ 818 RFLBrkLmpFailSts 0 "No_Failure" 1 "Failure" ;
VAL_ 819 RRIntellgntAsscLmpSts 0 "Initial_value" 1 "Off" 2 "Breathe" 3 "Always_Bright" ;
VAL_ 819 RFRTurnLmpFailSts 0 "No_Failure" 1 "Failure" ;
VAL_ 819 RFRBrkLmpFailSts 0 "No_Failure" 1 "Failure" ;
VAL_ 860 ValetParkingModSts 0 "Initial_value" 1 "OFF" 2 "ON" ;
VAL_ 879 WtrPmpSts 0 "Initial_Value" 1 "OFF" 2 "ON" 3 "Fault" ;
VAL_ 879 WtrPmpActRotSpd 0 "Initial_Value" 255 "Signal_Not_Populated" ;
